VERSION ""

NS_ :

BS_:

BU_:

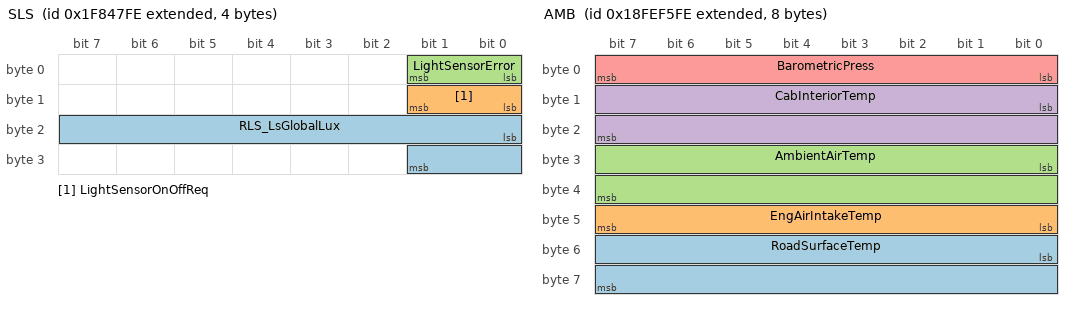
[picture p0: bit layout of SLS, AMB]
BO_ 2180532222 SLS: 4 Vector__XXX
 SG_ RLS_LsGlobalLux : 16|10@1+ (25,0) [0|25000] "" Vector__XXX
 SG_ LightSensorOnOffReq : 8|2@1+ (1,0) [0|0] "" Vector__XXX
 SG_ LightSensorError : 0|2@1+ (1,0) [0|3] "" Vector__XXX

BO_ 2566845950 AMB: 8 Vector__XXX
 SG_ RoadSurfaceTemp : 48|16@1+ (0.03125,-273) [-273|1734.96875] "C" Vector__XXX
 SG_ EngAirIntakeTemp : 40|8@1+ (1,-40) [-40|210] "C" Vector__XXX
 SG_ AmbientAirTemp : 24|16@1+ (0.03125,-273) [-273|1734.96875] "C" Vector__XXX
 SG_ CabInteriorTemp : 8|16@1+ (0.03125,-273) [-273|1734.96875] "C" Vector__XXX
 SG_ BarometricPress : 0|8@1+ (0.5,0) [0|125] "kPa" Vector__XXX

BO_ 2583065598 CENTLOCKOUT: 2 Vector__XXX
 SG_ CentralLockFailState : 8|4@1+ (1,0) [0|15] "-" Vector__XXX
 SG_ CentralLockCommand : 0|5@1+ (1,0) [0|31] "-" Vector__XXX

BO_ 2515942654 ClimateTempData: 3 Vector__XXX
 SG_ CabinTempSensorFault : 16|1@1+ (1,0) [0|1] "" Vector__XXX
 SG_ ActualCabinTemperature : 0|16@1+ (0.03125,-273) [-273|1774.96875] "degC" Vector__XXX

BO_ 2180392702 RSDS: 1 Vector__XXX
 SG_ RollerShutterFaults : 3|3@1+ (1,0) [0|7] "" Vector__XXX
 SG_ RollerShutterStatus : 0|3@1+ (1,0) [0|7] "" Vector__XXX

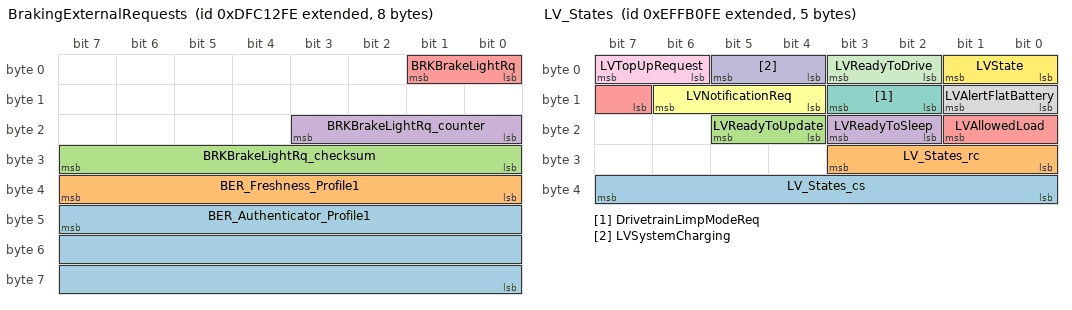
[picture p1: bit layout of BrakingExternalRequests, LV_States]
BO_ 2382107390 BrakingExternalRequests: 8 Vector__XXX
 SG_ BER_Authenticator_Profile1 : 47|24@0+ (1,0) [0|16777215] "" Vector__XXX
 SG_ BER_Freshness_Profile1 : 39|8@0+ (1,0) [0|255] "" Vector__XXX
 SG_ BRKBrakeLightRq_checksum : 24|8@1+ (1,0) [0|255] "" Vector__XXX
 SG_ BRKBrakeLightRq_counter : 16|4@1+ (1,0) [0|15] "" Vector__XXX
 SG_ BRKBrakeLightRq : 0|2@1+ (1,0) [0|3] "" Vector__XXX

BO_ 2399121662 LV_States: 5 Vector__XXX
 SG_ LV_States_cs : 32|8@1+ (1,0) [0|255] "" Vector__XXX
 SG_ LV_States_rc : 24|4@1+ (1,0) [0|15] "" Vector__XXX
 SG_ LVReadyToUpdate : 20|2@1+ (1,0) [0|3] "" Vector__XXX
 SG_ LVReadyToSleep : 18|2@1+ (1,0) [0|3] "" Vector__XXX
 SG_ LVAllowedLoad : 15|3@1+ (1,0) [0|7] "" Vector__XXX
 SG_ LVNotificationReq : 12|3@1+ (1,0) [0|7] "" Vector__XXX
 SG_ DrivetrainLimpModeReq : 10|2@1+ (1,0) [0|3] "" Vector__XXX
 SG_ LVAlertFlatBattery : 8|2@1+ (1,0) [0|3] "" Vector__XXX
 SG_ LVTopUpRequest : 6|2@1+ (1,0) [0|3] "" Vector__XXX
 SG_ LVSystemCharging : 4|2@1+ (1,0) [0|3] "" Vector__XXX
 SG_ LVReadyToDrive : 2|2@1+ (1,0) [0|3] "" Vector__XXX
 SG_ LVState : 0|2@1+ (1,0) [0|3] "" Vector__XXX

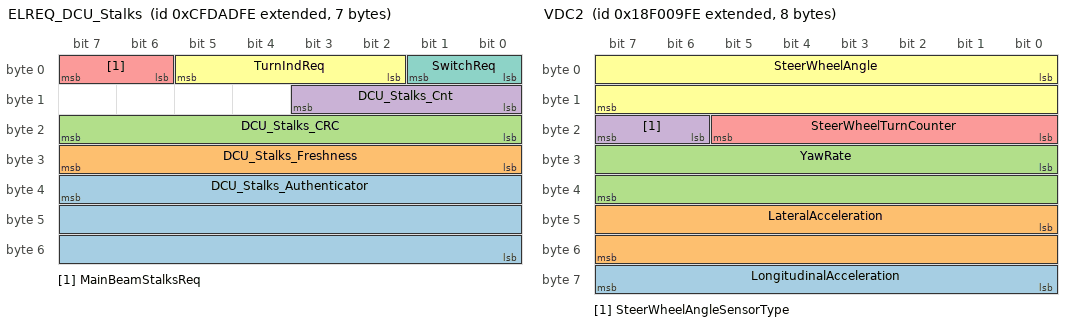
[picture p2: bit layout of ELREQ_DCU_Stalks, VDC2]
BO_ 2365435390 ELREQ_DCU_Stalks: 7 Vector__XXX
 SG_ DCU_Stalks_Authenticator : 39|24@0+ (1,0) [0|16777215] "" Vector__XXX
 SG_ DCU_Stalks_Freshness : 31|8@0+ (1,0) [0|255] "" Vector__XXX
 SG_ DCU_Stalks_CRC : 16|8@1+ (1,0) [0|0] "" Vector__XXX
 SG_ DCU_Stalks_Cnt : 8|4@1+ (1,0) [0|0] "" Vector__XXX
 SG_ MainBeamStalksReq : 6|2@1+ (1,0) [0|3] "" Vector__XXX
 SG_ TurnIndReq : 2|4@1+ (1,0) [0|3] "" Vector__XXX
 SG_ SwitchReq : 0|2@1+ (1,0) [0|3] "" Vector__XXX

BO_ 2365473278 LCMD: 8 Vector__XXX
 SG_ ImplementRearWorkLightCmd : 62|2@1+ (1,0) [0|3] "" Vector__XXX
 SG_ ImplLeftFacingWorkLightCmd : 60|2@1+ (1,0) [0|3] "" Vector__XXX
 SG_ ImplRightFwdWorkLightCmd : 58|2@1+ (1,0) [0|3] "" Vector__XXX
 SG_ LightingDataRqCmd : 56|2@1+ (1,0) [0|3] "" Vector__XXX
 SG_ ImplLeftForwardWorkLightCmd : 54|2@1+ (1,0) [0|3] "" Vector__XXX
 SG_ ImplRightFacingWorkLightCmd : 52|2@1+ (1,0) [0|3] "" Vector__XXX
 SG_ ImplOEMOption1LightCmd : 50|2@1+ (1,0) [0|3] "" Vector__XXX
 SG_ ImplOEMOption2LightCmd : 48|2@1+ (1,0) [0|3] "" Vector__XXX
 SG_ TrctrFrntHghMdWkLightsCmd : 46|2@1+ (1,0) [0|3] "" Vector__XXX
 SG_ TrctrFrntLowMdWkLightsCmd : 44|2@1+ (1,0) [0|3] "" Vector__XXX
 SG_ TrctrSdeHighMdWkLightsCmd : 42|2@1+ (1,0) [0|3] "" Vector__XXX
 SG_ TrctrSideLowMdWkLightsCmd : 40|2@1+ (1,0) [0|3] "" Vector__XXX
 SG_ TrctrRarHighMdWkLightsCmd : 38|2@1+ (1,0) [0|3] "" Vector__XXX
 SG_ TrctrRearLowMdWkLightsCmd : 36|2@1+ (1,0) [0|3] "" Vector__XXX
 SG_ TrctrUndrsdeMdWkLightsCmd : 34|2@1+ (1,0) [0|3] "" Vector__XXX
 SG_ RearFogLightsCmd : 32|2@1+ (1,0) [0|3] "" Vector__XXX
 SG_ TractorMarkerLightCmd : 30|2@1+ (1,0) [0|3] "" Vector__XXX
 SG_ ImplementMarkerLightCmd : 28|2@1+ (1,0) [0|3] "" Vector__XXX
 SG_ TractorClearanceLightCmd : 26|2@1+ (1,0) [0|3] "" Vector__XXX
 SG_ ImplementClearanceLightCmd : 24|2@1+ (1,0) [0|3] "" Vector__XXX
 SG_ LeftStopLightCmd : 22|2@1+ (1,0) [0|3] "" Vector__XXX
 SG_ RightStopLightCmd : 20|2@1+ (1,0) [0|3] "" Vector__XXX
 SG_ CenterStopLightCmd : 18|2@1+ (1,0) [0|3] "" Vector__XXX
 SG_ BackUpLightAndAlarmHornCmd : 16|2@1+ (1,0) [0|3] "" Vector__XXX
 SG_ LeftTurnSignalLightsCmd : 14|2@1+ (1,0) [0|3] "" Vector__XXX
 SG_ RightTurnSignalLightsCmd : 12|2@1+ (1,0) [0|3] "" Vector__XXX
 SG_ RotatingBeaconLightCmd : 10|2@1+ (1,0) [0|3] "" Vector__XXX
 SG_ TractorFrontFogLightsCmd : 8|2@1+ (1,0) [0|3] "" Vector__XXX
 SG_ HighBeamHeadLightCmd : 6|2@1+ (1,0) [0|3] "" Vector__XXX
 SG_ LowBeamHeadLightCmd : 4|2@1+ (1,0) [0|3] "" Vector__XXX
 SG_ AltBeamHeadLightCmd : 2|2@1+ (1,0) [0|3] "" Vector__XXX
 SG_ RunningLightCmd : 0|2@1+ (1,0) [0|3] "" Vector__XXX

BO_ 2566799614 LD: 8 Vector__XXX
 SG_ ImplementRearWorkLight : 62|2@1+ (1,0) [0|3] "" Vector__XXX
 SG_ ImplLeftFacingWorkLight : 60|2@1+ (1,0) [0|3] "" Vector__XXX
 SG_ ImplRightForwardWorkLight : 58|2@1+ (1,0) [0|3] "" Vector__XXX
 SG_ ImplLeftForwardWorkLight : 54|2@1+ (1,0) [0|3] "" Vector__XXX
 SG_ ImplRightFacingWorkLight : 52|2@1+ (1,0) [0|3] "" Vector__XXX
 SG_ ImplementOEMOption1Light : 50|2@1+ (1,0) [0|3] "" Vector__XXX
 SG_ ImplementOEMOption2Light : 48|2@1+ (1,0) [0|3] "" Vector__XXX
 SG_ TrctorFrontHighMdWkLights : 46|2@1+ (1,0) [0|3] "" Vector__XXX
 SG_ TractorFrontLowMdWkLights : 44|2@1+ (1,0) [0|3] "" Vector__XXX
 SG_ TractorSideHighMdWkLights : 42|2@1+ (1,0) [0|3] "" Vector__XXX
 SG_ TractorSideLowMdWkLights : 40|2@1+ (1,0) [0|3] "" Vector__XXX
 SG_ TractorRearHighMdWkLights : 38|2@1+ (1,0) [0|3] "" Vector__XXX
 SG_ TractorRearLowMdWkLights : 36|2@1+ (1,0) [0|3] "" Vector__XXX
 SG_ TrctorUndersideMdWkLights : 34|2@1+ (1,0) [0|3] "" Vector__XXX
 SG_ RearFogLights : 32|2@1+ (1,0) [0|3] "" Vector__XXX
 SG_ TractorMarkerLight : 30|2@1+ (1,0) [0|3] "" Vector__XXX
 SG_ ImplementMarkerLight : 28|2@1+ (1,0) [0|3] "" Vector__XXX
 SG_ TractorClearanceLight : 26|2@1+ (1,0) [0|3] "" Vector__XXX
 SG_ ImplementClearanceLight : 24|2@1+ (1,0) [0|3] "" Vector__XXX
 SG_ LeftStopLight : 22|2@1+ (1,0) [0|3] "" Vector__XXX
 SG_ RightStopLight : 20|2@1+ (1,0) [0|3] "" Vector__XXX
 SG_ CenterStopLight : 18|2@1+ (1,0) [0|3] "" Vector__XXX
 SG_ BackUpLightAndAlarmHorn : 16|2@1+ (1,0) [0|3] "" Vector__XXX
 SG_ LeftTurnSignalLights : 14|2@1+ (1,0) [0|3] "" Vector__XXX
 SG_ RightTurnSignalLights : 12|2@1+ (1,0) [0|3] "" Vector__XXX
 SG_ RotatingBeaconLight : 10|2@1+ (1,0) [0|3] "" Vector__XXX
 SG_ TractorFrontFogLights : 8|2@1+ (1,0) [0|3] "" Vector__XXX
 SG_ HighBeamHeadLight : 6|2@1+ (1,0) [0|3] "" Vector__XXX
 SG_ LowBeamHeadLight : 4|2@1+ (1,0) [0|3] "" Vector__XXX
 SG_ AltBeamHeadLight : 2|2@1+ (1,0) [0|3] "" Vector__XXX
 SG_ RunningLight : 0|2@1+ (1,0) [0|3] "" Vector__XXX

BO_ 2565868030 VDC2: 8 Vector__XXX
 SG_ LongitudinalAcceleration : 56|8@1+ (0.1,-12.5) [-12.5|12.5] "m/s" Vector__XXX
 SG_ LateralAcceleration : 40|16@1+ (0.00048828125,-15.687) [-15.687|15.687] "m/s" Vector__XXX
 SG_ YawRate : 24|16@1+ (0.0001220703125,-3.92) [-3.92|3.92] "rad/s" Vector__XXX
 SG_ SteerWheelAngleSensorType : 22|2@1+ (1,0) [0|3] "" Vector__XXX
 SG_ SteerWheelTurnCounter : 16|6@1+ (1,-32) [-10|10] "turns" Vector__XXX
 SG_ SteerWheelAngle : 0|16@1+ (0.0009765625,-31.374) [-31.374|31.374] "rad" Vector__XXX

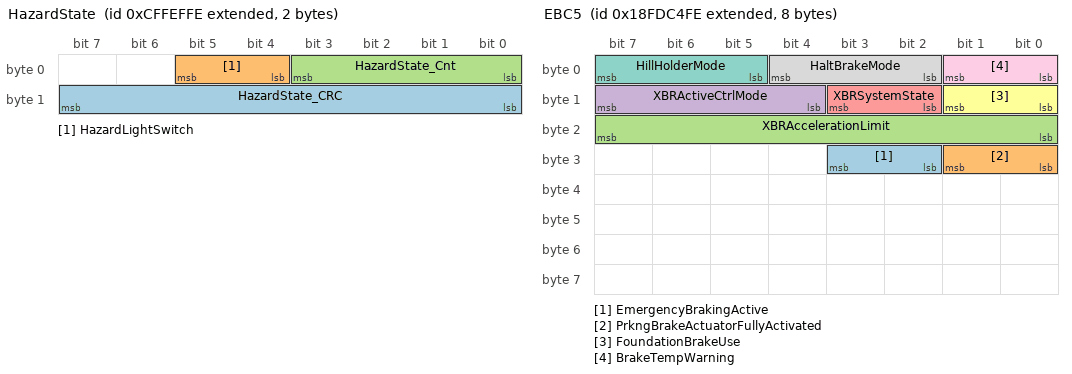
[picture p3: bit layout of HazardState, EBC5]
BO_ 2365583358 HazardState: 2 Vector__XXX
 SG_ HazardState_CRC : 8|8@1+ (1,0) [0|0] "" Vector__XXX
 SG_ HazardLightSwitch : 4|2@1+ (1,0) [0|3] "" Vector__XXX
 SG_ HazardState_Cnt : 0|4@1+ (1,0) [0|0] "" Vector__XXX

BO_ 2566767870 EBC5: 8 Vector__XXX
 SG_ EmergencyBrakingActive : 26|2@1+ (1,0) [0|3] "" Vector__XXX
 SG_ PrkngBrakeActuatorFullyActivated : 24|2@1+ (1,0) [0|3] "" Vector__XXX
 SG_ XBRAccelerationLimit : 16|8@1+ (0.1,-12.5) [-10|10] "m/s" Vector__XXX
 SG_ XBRActiveCtrlMode : 12|4@1+ (1,0) [0|15] "" Vector__XXX
 SG_ XBRSystemState : 10|2@1+ (1,0) [0|3] "" Vector__XXX
 SG_ FoundationBrakeUse : 8|2@1+ (1,0) [0|3] "" Vector__XXX
 SG_ HillHolderMode : 5|3@1+ (1,0) [0|7] "" Vector__XXX
 SG_ HaltBrakeMode : 2|3@1+ (1,0) [0|7] "" Vector__XXX
 SG_ BrakeTempWarning : 0|2@1+ (1,0) [0|3] "" Vector__XXX

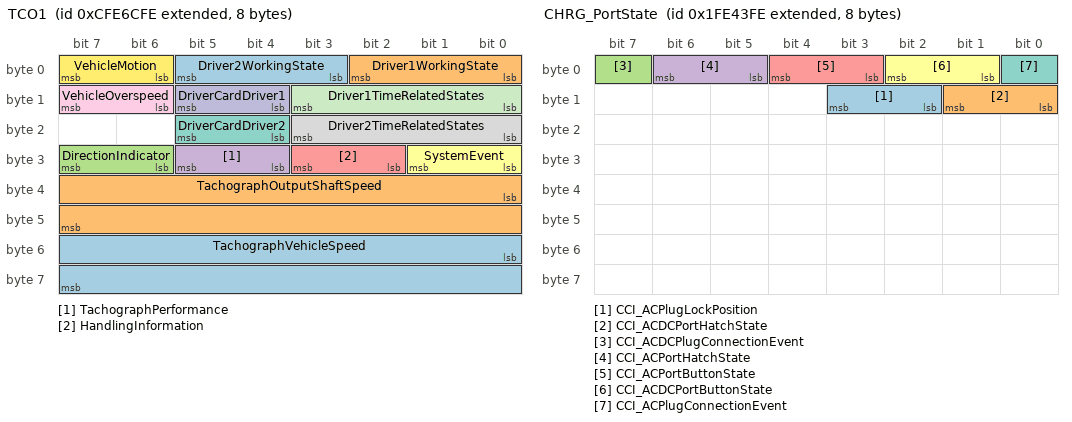
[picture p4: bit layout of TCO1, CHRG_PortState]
BO_ 2365484286 TCO1: 8 Vector__XXX
 SG_ TachographVehicleSpeed : 48|16@1+ (0.00390625,0) [0|250.996] "km/h" Vector__XXX
 SG_ TachographOutputShaftSpeed : 32|16@1+ (0.125,0) [0|8031.875] "rpm" Vector__XXX
 SG_ DirectionIndicator : 30|2@1+ (1,0) [0|3] "" Vector__XXX
 SG_ TachographPerformance : 28|2@1+ (1,0) [0|3] "" Vector__XXX
 SG_ HandlingInformation : 26|2@1+ (1,0) [0|3] "" Vector__XXX
 SG_ SystemEvent : 24|2@1+ (1,0) [0|3] "" Vector__XXX
 SG_ DriverCardDriver2 : 20|2@1+ (1,0) [0|3] "" Vector__XXX
 SG_ Driver2TimeRelatedStates : 16|4@1+ (1,0) [0|15] "" Vector__XXX
 SG_ VehicleOverspeed : 14|2@1+ (1,0) [0|3] "" Vector__XXX
 SG_ DriverCardDriver1 : 12|2@1+ (1,0) [0|3] "" Vector__XXX
 SG_ Driver1TimeRelatedStates : 8|4@1+ (1,0) [0|15] "" Vector__XXX
 SG_ VehicleMotion : 6|2@1+ (1,0) [0|3] "" Vector__XXX
 SG_ Driver2WorkingState : 3|3@1+ (1,0) [0|7] "" Vector__XXX
 SG_ Driver1WorkingState : 0|3@1+ (1,0) [0|7] "" Vector__XXX

BO_ 2180924414 CHRG_PortState: 8 Vector__XXX
 SG_ CCI_ACPlugLockPosition : 10|2@1+ (1,0) [0|3] "" Vector__XXX
 SG_ CCI_ACDCPortHatchState : 8|2@1+ (1,0) [0|3] "" Vector__XXX
 SG_ CCI_ACDCPlugConnectionEvent : 7|1@1+ (1,0) [0|1] "" Vector__XXX
 SG_ CCI_ACPortHatchState : 5|2@1+ (1,0) [0|3] "" Vector__XXX
 SG_ CCI_ACPortButtonState : 3|2@1+ (1,0) [0|3] "" Vector__XXX
 SG_ CCI_ACDCPortButtonState : 1|2@1+ (1,0) [0|3] "" Vector__XXX
 SG_ CCI_ACPlugConnectionEvent : 0|1@1+ (1,0) [0|1] "" Vector__XXX

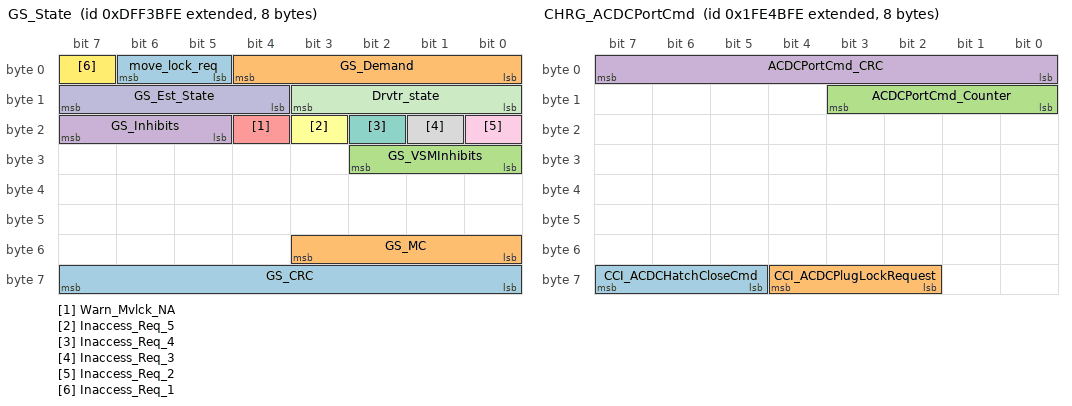
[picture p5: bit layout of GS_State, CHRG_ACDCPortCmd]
BO_ 2382314494 GS_State: 8 Vector__XXX
 SG_ GS_CRC : 56|8@1+ (1,0) [0|255] "" Vector__XXX
 SG_ GS_MC : 48|4@1+ (1,0) [0|15] "" Vector__XXX
 SG_ GS_VSMInhibits : 24|3@1+ (1,0) [0|7] "" Vector__XXX
 SG_ GS_Inhibits : 21|3@1+ (1,0) [0|7] "" Vector__XXX
 SG_ Warn_Mvlck_NA : 20|1@1+ (1,0) [0|1] "" Vector__XXX
 SG_ Inaccess_Req_5 : 19|1@1+ (1,0) [0|1] "" Vector__XXX
 SG_ Inaccess_Req_4 : 18|1@1+ (1,0) [0|1] "" Vector__XXX
 SG_ Inaccess_Req_3 : 17|1@1+ (1,0) [0|1] "" Vector__XXX
 SG_ Inaccess_Req_2 : 16|1@1+ (1,0) [0|1] "" Vector__XXX
 SG_ GS_Est_State : 12|4@1+ (1,0) [0|15] "" Vector__XXX
 SG_ Drvtr_state : 8|4@1+ (1,0) [0|15] "" Vector__XXX
 SG_ Inaccess_Req_1 : 7|1@1+ (1,0) [0|1] "" Vector__XXX
 SG_ move_lock_req : 5|2@1+ (1,0) [0|3] "" Vector__XXX
 SG_ GS_Demand : 0|5@1+ (1,0) [0|31] "" Vector__XXX

BO_ 2180926462 CHRG_ACDCPortCmd: 8 Vector__XXX
 SG_ CCI_ACDCHatchCloseCmd : 61|3@1+ (1,0) [0|7] "" Vector__XXX
 SG_ CCI_ACDCPlugLockRequest : 58|3@1+ (1,0) [0|7] "" Vector__XXX
 SG_ ACDCPortCmd_Counter : 8|4@1+ (1,0) [0|15] "" Vector__XXX
 SG_ ACDCPortCmd_CRC : 0|8@1+ (1,0) [0|255] "" Vector__XXX

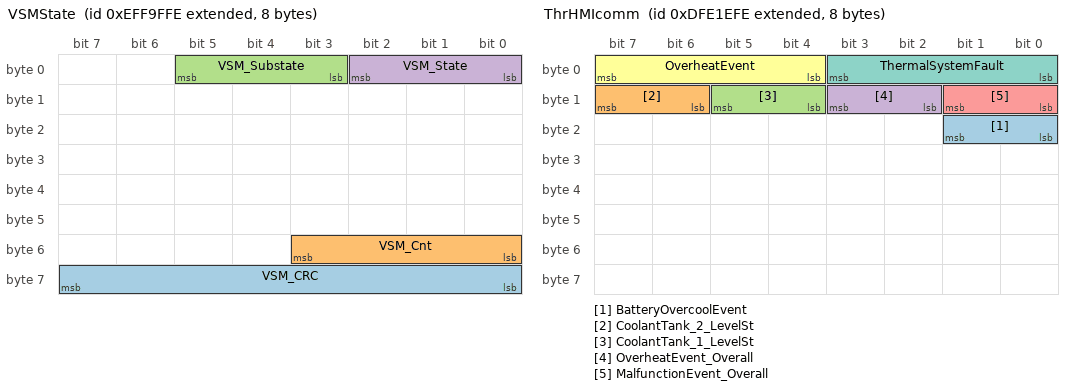
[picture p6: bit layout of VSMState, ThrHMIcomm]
BO_ 2399117310 VSMState: 8 Vector__XXX
 SG_ VSM_CRC : 56|8@1+ (1,0) [0|255] "" Vector__XXX
 SG_ VSM_Cnt : 48|4@1+ (1,0) [0|15] "" Vector__XXX
 SG_ VSM_Substate : 3|3@1+ (1,0) [0|7] "" Vector__XXX
 SG_ VSM_State : 0|3@1+ (1,0) [0|7] "" Vector__XXX

BO_ 2566883070 DoorLockNotify: 1 Vector__XXX
 SG_ RollerShutterLatchNotify : 3|3@1+ (1,0) [0|3] "-" Vector__XXX
 SG_ DoorLatchNotify : 0|3@1+ (1,0) [0|3] "-" Vector__XXX

BO_ 2382241534 ThrHMIcomm: 8 Vector__XXX
 SG_ BatteryOvercoolEvent : 16|2@1+ (1,0) [0|3] "" Vector__XXX
 SG_ CoolantTank_2_LevelSt : 14|2@1+ (1,0) [0|0] "" Vector__XXX
 SG_ CoolantTank_1_LevelSt : 12|2@1+ (1,0) [0|0] "" Vector__XXX
 SG_ OverheatEvent_Overall : 10|2@1+ (1,0) [0|0] "" Vector__XXX
 SG_ MalfunctionEvent_Overall : 8|2@1+ (1,0) [0|0] "" Vector__XXX
 SG_ OverheatEvent : 4|4@1+ (1,0) [0|0] "" Vector__XXX
 SG_ ThermalSystemFault : 0|4@1+ (1,0) [0|0] "" Vector__XXX

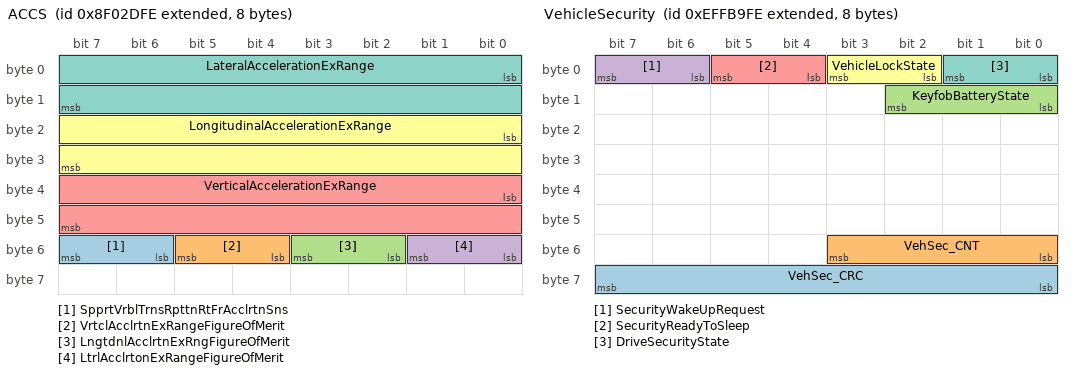
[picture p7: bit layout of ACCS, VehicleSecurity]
BO_ 2297441790 ACCS: 8 Vector__XXX
 SG_ SpprtVrblTrnsRpttnRtFrAcclrtnSns : 54|2@1+ (1,0) [0|3] "" Vector__XXX
 SG_ VrtclAcclrtnExRangeFigureOfMerit : 52|2@1+ (1,0) [0|3] "" Vector__XXX
 SG_ LngtdnlAcclrtnExRngFigureOfMerit : 50|2@1+ (1,0) [0|3] "" Vector__XXX
 SG_ LtrlAcclrtonExRangeFigureOfMerit : 48|2@1+ (1,0) [0|3] "" Vector__XXX
 SG_ VerticalAccelerationExRange : 32|16@1+ (0.01,-320) [-320|322.55] "m/s" Vector__XXX
 SG_ LongitudinalAccelerationExRange : 16|16@1+ (0.01,-320) [-320|322.55] "m/s" Vector__XXX
 SG_ LateralAccelerationExRange : 0|16@1+ (0.01,-320) [-320|322.55] "m/s" Vector__XXX

BO_ 2583173886 WPRWSH_UserRequest: 1 Vector__XXX
 SG_ WipeRequest : 2|3@1+ (1,0) [0|7] "" Vector__XXX
 SG_ WashRequest : 0|2@1+ (1,0) [0|3] "" Vector__XXX

BO_ 2516075518 RideHeight_Info: 8 Vector__XXX
 SG_ RideHeight_Value : 0|3@1+ (1,0) [0|0] "" Vector__XXX

BO_ 2566882814 VehicleKeyState: 8 Vector__XXX
 SG_ KeyRange : 3|3@1+ (1,0) [0|7] "-" Vector__XXX
 SG_ KeyCommand : 0|3@1+ (1,0) [0|7] "-" Vector__XXX

BO_ 2583062526 CENTLOCKIN_HMI: 8 Vector__XXX
 SG_ CentralLockRequest : 0|3@1+ (1,0) [0|7] "-" Vector__XXX

BO_ 2399123966 VehicleSecurity: 8 Vector__XXX
 SG_ VehSec_CRC : 56|8@1+ (1,0) [0|255] "" Vector__XXX
 SG_ VehSec_CNT : 48|4@1+ (1,0) [0|15] "" Vector__XXX
 SG_ KeyfobBatteryState : 8|3@1+ (1,0) [0|7] "" Vector__XXX
 SG_ SecurityWakeUpRequest : 6|2@1+ (1,0) [0|3] "" Vector__XXX
 SG_ SecurityReadyToSleep : 4|2@1+ (1,0) [0|3] "" Vector__XXX
 SG_ VehicleLockState : 2|2@1+ (1,0) [0|3] "" Vector__XXX
 SG_ DriveSecurityState : 0|2@1+ (1,0) [0|3] "" Vector__XXX

BO_ 2583065854 CENTLOCKIN_KeyFob: 8 Vector__XXX
 SG_ CentralLockRequest : 0|3@1+ (1,0) [0|7] "-" Vector__XXX

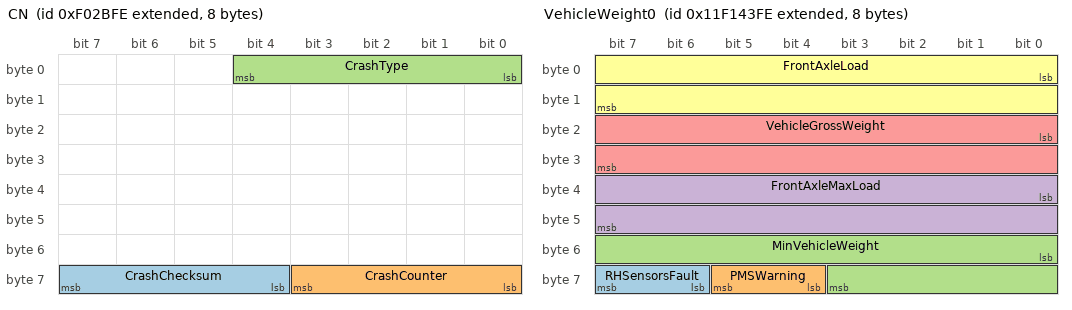
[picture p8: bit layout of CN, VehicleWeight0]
BO_ 2163223550 CN: 8 Vector__XXX
 SG_ CrashChecksum : 60|4@1+ (1,0) [0|15] "" Vector__XXX
 SG_ CrashCounter : 56|4@1+ (1,0) [0|15] "" Vector__XXX
 SG_ CrashType : 0|5@1+ (1,0) [0|31] "" Vector__XXX

BO_ 2448507902 VehicleWeight0: 8 Vector__XXX
 SG_ RHSensorsFault : 62|2@1+ (1,0) [0|3] "" Vector__XXX
 SG_ PMSWarning : 60|2@1+ (1,0) [0|3] "" Vector__XXX
 SG_ MinVehicleWeight : 48|12@1+ (10,0) [0|40000] "kg" Vector__XXX
 SG_ FrontAxleMaxLoad : 32|16@1+ (1,0) [0|65535] "kg" Vector__XXX
 SG_ VehicleGrossWeight : 16|16@1+ (1,0) [0|65535] "kg" Vector__XXX
 SG_ FrontAxleLoad : 0|16@1+ (1,0) [0|65535] "kg" Vector__XXX

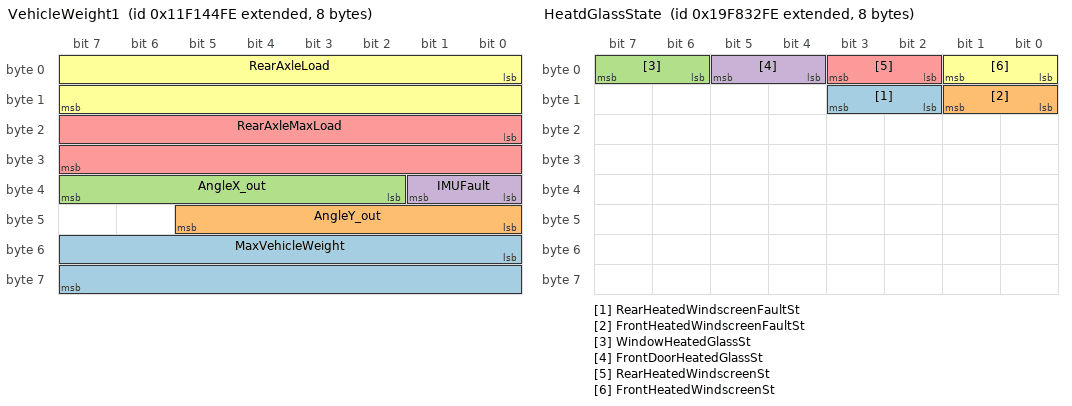
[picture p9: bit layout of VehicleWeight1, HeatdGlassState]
BO_ 2448508158 VehicleWeight1: 8 Vector__XXX
 SG_ MaxVehicleWeight : 48|16@1+ (1,0) [0|65535] "kg" Vector__XXX
 SG_ AngleY_out : 40|6@1+ (1.5,-45) [-45|45] "deg" Vector__XXX
 SG_ AngleX_out : 34|6@1+ (1.5,-45) [-45|45] "deg" Vector__XXX
 SG_ IMUFault : 32|2@1+ (1,0) [0|3] "" Vector__XXX
 SG_ RearAxleMaxLoad : 16|16@1+ (1,0) [0|65535] "kg" Vector__XXX
 SG_ RearAxleLoad : 0|16@1+ (1,0) [0|65535] "kg" Vector__XXX

BO_ 2583180030 HeatdGlassState: 8 Vector__XXX
 SG_ RearHeatedWindscreenFaultSt : 10|2@1+ (1,0) [0|3] "" Vector__XXX
 SG_ FrontHeatedWindscreenFaultSt : 8|2@1+ (1,0) [0|3] "" Vector__XXX
 SG_ WindowHeatedGlassSt : 6|2@1+ (1,0) [0|3] "" Vector__XXX
 SG_ FrontDoorHeatedGlassSt : 4|2@1+ (1,0) [0|3] "" Vector__XXX
 SG_ RearHeatedWindscreenSt : 2|2@1+ (1,0) [0|3] "" Vector__XXX
 SG_ FrontHeatedWindscreenSt : 0|2@1+ (1,0) [0|3] "" Vector__XXX

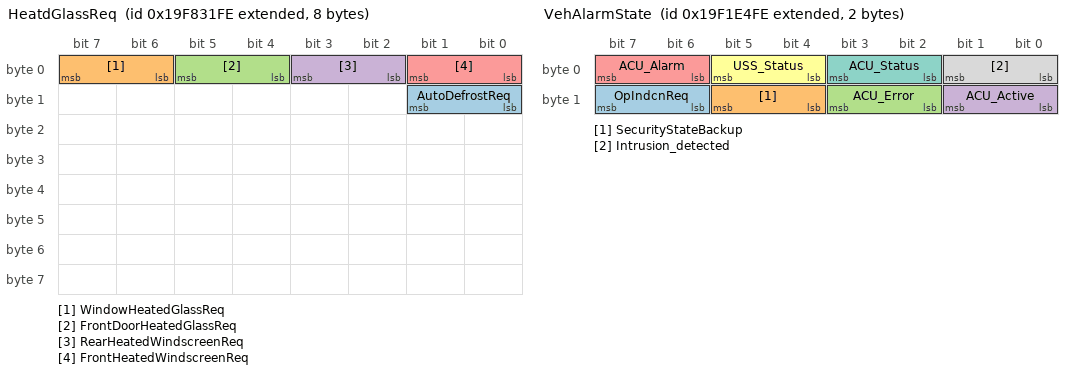
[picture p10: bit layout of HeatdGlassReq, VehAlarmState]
BO_ 2583179774 HeatdGlassReq: 8 Vector__XXX
 SG_ AutoDefrostReq : 8|2@1+ (1,0) [0|3] "" Vector__XXX
 SG_ WindowHeatedGlassReq : 6|2@1+ (1,0) [0|3] "" Vector__XXX
 SG_ FrontDoorHeatedGlassReq : 4|2@1+ (1,0) [0|3] "" Vector__XXX
 SG_ RearHeatedWindscreenReq : 2|2@1+ (1,0) [0|3] "" Vector__XXX
 SG_ FrontHeatedWindscreenReq : 0|2@1+ (1,0) [0|3] "" Vector__XXX

BO_ 2499547902 CDC: 8 Vector__XXX
 SG_ MirrorRight2HeatCmd : 54|2@1+ (1,0) [0|3] "" Vector__XXX
 SG_ MirrorLeft2HeatCmd : 52|2@1+ (1,0) [0|3] "" Vector__XXX
 SG_ MirrorRight1HeatCmd : 50|2@1+ (1,0) [0|3] "" Vector__XXX
 SG_ MirrorLeft1HeatCmd : 48|2@1+ (1,0) [0|3] "" Vector__XXX
 SG_ MirrorRight2VerticalCmd : 46|2@1+ (1,0) [0|3] "" Vector__XXX
 SG_ MirrorRight2HorizontalCmd : 44|2@1+ (1,0) [0|3] "" Vector__XXX
 SG_ MirrorLeft2VerticalCmd : 42|2@1+ (1,0) [0|3] "" Vector__XXX
 SG_ MirrorLeft2HorizontalCmd : 40|2@1+ (1,0) [0|3] "" Vector__XXX
 SG_ MirrorRight1VerticalCmd : 38|2@1+ (1,0) [0|3] "" Vector__XXX
 SG_ MirrorRight1HorizontalCmd : 36|2@1+ (1,0) [0|3] "" Vector__XXX
 SG_ MirrorLeft1VerticalCmd : 34|2@1+ (1,0) [0|3] "" Vector__XXX
 SG_ MirrorLeft1HorizontalCmd : 32|2@1+ (1,0) [0|3] "" Vector__XXX
 SG_ RightRearWindowPosCmd : 27|3@1+ (1,0) [0|7] "" Vector__XXX
 SG_ LeftRearWindowPosCmd : 24|3@1+ (1,0) [0|7] "" Vector__XXX
 SG_ RightFrontWindowPosCmd : 19|3@1+ (1,0) [0|7] "" Vector__XXX
 SG_ LeftFrontWindowPosCmd : 16|3@1+ (1,0) [0|7] "" Vector__XXX
 SG_ RemoteCabDoorLockReq : 8|3@1+ (1,0) [0|7] "" Vector__XXX
 SG_ DoorsLockActCmd : 0|3@1+ (1,0) [0|7] "" Vector__XXX

BO_ 2583177470 WPRWSH_RainData: 1 Vector__XXX
 SG_ RainIntensity : 0|3@1+ (1,0) [0|7] "" Vector__XXX

BO_ 2364552702 ImmoState: 1 Vector__XXX
 SG_ ImmoState : 0|2@1+ (1,0) [0|3] "" Vector__XXX

BO_ 2582766846 VehAlarmState: 2 Vector__XXX
 SG_ OpIndcnReq : 14|2@1+ (1,0) [0|3] "" Vector__XXX
 SG_ SecurityStateBackup : 12|2@1+ (1,0) [0|0] "" Vector__XXX
 SG_ ACU_Error : 10|2@1+ (1,0) [0|0] "" Vector__XXX
 SG_ ACU_Active : 8|2@1+ (1,0) [0|3] "" Vector__XXX
 SG_ ACU_Alarm : 6|2@1+ (1,0) [0|3] "" Vector__XXX
 SG_ USS_Status : 4|2@1+ (1,0) [0|3] "" Vector__XXX
 SG_ ACU_Status : 2|2@1+ (1,0) [0|3] "" Vector__XXX
 SG_ Intrusion_detected : 0|2@1+ (1,0) [0|3] "-" Vector__XXX

BO_ 2565865982 EBC1: 8 Vector__XXX
 SG_ TrctrMntdTrailerABSWarningSignal : 62|2@1+ (1,0) [0|3] "" Vector__XXX
 SG_ TrailerABSStatus : 60|2@1+ (1,0) [0|3] "" Vector__XXX
 SG_ HaltBrakeSwitch : 58|2@1+ (1,0) [0|3] "" Vector__XXX
 SG_ SrcAddrssOfCntrllngDvcFrBrkeCtrl : 48|8@1+ (1,0) [0|253] "" Vector__XXX
 SG_ ATC_ASRInformationSignal : 46|2@1+ (1,0) [0|3] "" Vector__XXX
 SG_ ABS_EBSAmberWarningSignal : 44|2@1+ (1,0) [0|3] "" Vector__XXX
 SG_ EBSRedWarningSignal : 42|2@1+ (1,0) [0|3] "" Vector__XXX
 SG_ ABSFullyOperational : 40|2@1+ (1,0) [0|3] "" Vector__XXX
 SG_ EngRetarderSelection : 32|8@1+ (0.4,0) [0|100] "%" Vector__XXX
 SG_ RemoteAccelEnableSwitch : 30|2@1+ (1,0) [0|3] "" Vector__XXX
 SG_ EngAuxShutdownSwitch : 28|2@1+ (1,0) [0|3] "" Vector__XXX
 SG_ EngDerateSwitch : 26|2@1+ (1,0) [0|3] "" Vector__XXX
 SG_ AccelInterlockSwitch : 24|2@1+ (1,0) [0|3] "" Vector__XXX
 SG_ TractionCtrlOverrideSwitch : 22|2@1+ (1,0) [0|3] "" Vector__XXX
 SG_ ASRHillHolderSwitch : 20|2@1+ (1,0) [0|3] "" Vector__XXX
 SG_ ASROffroadSwitch : 18|2@1+ (1,0) [0|3] "" Vector__XXX
 SG_ ABSOffroadSwitch : 16|2@1+ (1,0) [0|3] "" Vector__XXX
 SG_ BrakePedalPos : 8|8@1+ (0.4,0) [0|100] "%" Vector__XXX
 SG_ EBSBrakeSwitch : 6|2@1+ (1,0) [0|3] "" Vector__XXX
 SG_ AntiLockBrakingActive : 4|2@1+ (1,0) [0|3] "" Vector__XXX
 SG_ ASRBrakeCtrlActive : 2|2@1+ (1,0) [0|3] "" Vector__XXX
 SG_ ASREngCtrlActive : 0|2@1+ (1,0) [0|3] "" Vector__XXX

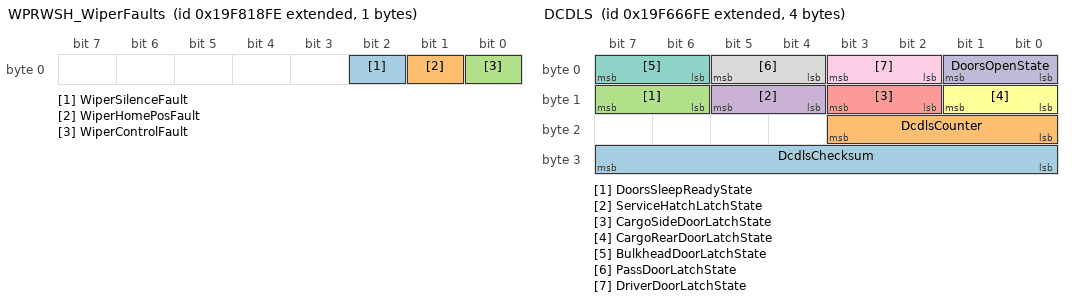
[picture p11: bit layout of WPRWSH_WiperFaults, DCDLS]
BO_ 2583173374 WPRWSH_WiperFaults: 1 Vector__XXX
 SG_ WiperSilenceFault : 2|1@1+ (1,0) [0|1] "" Vector__XXX
 SG_ WiperHomePosFault : 1|1@1+ (1,0) [0|1] "" Vector__XXX
 SG_ WiperControlFault : 0|1@1+ (1,0) [0|1] "" Vector__XXX

BO_ 2381731326 TP_TouchEvent: 8 Vector__XXX
 SG_ TouchFailState : 3|3@1+ (1,0) [0|7] "" Vector__XXX
 SG_ TouchEvent : 0|3@1+ (1,0) [0|7] "" Vector__XXX

BO_ 2583062270 DCDLS: 4 Vector__XXX
 SG_ DcdlsChecksum : 24|8@1+ (1,0) [0|255] "" Vector__XXX
 SG_ DcdlsCounter : 16|4@1+ (1,0) [0|15] "" Vector__XXX
 SG_ DoorsSleepReadyState : 14|2@1+ (1,0) [0|3] "-" Vector__XXX
 SG_ ServiceHatchLatchState : 12|2@1+ (1,0) [0|3] "" Vector__XXX
 SG_ CargoSideDoorLatchState : 10|2@1+ (1,0) [0|3] "-" Vector__XXX
 SG_ CargoRearDoorLatchState : 8|2@1+ (1,0) [0|3] "-" Vector__XXX
 SG_ BulkheadDoorLatchState : 6|2@1+ (1,0) [0|3] "-" Vector__XXX
 SG_ PassDoorLatchState : 4|2@1+ (1,0) [0|3] "-" Vector__XXX
 SG_ DriverDoorLatchState : 2|2@1+ (1,0) [0|3] "-" Vector__XXX
 SG_ DoorsOpenState : 0|2@1+ (1,0) [0|3] "-" Vector__XXX

BO_ 2516060670 ParkAssistRequest: 8 Vector__XXX
 SG_ paEnableReq : 2|2@1+ (1,0) [0|3] "" Vector__XXX
 SG_ paAutoReq : 0|2@1+ (1,0) [0|3] "" Vector__XXX

BO_ 2516060414 ParkAssistStatus: 8 Vector__XXX
 SG_ paStatus : 0|2@1+ (1,0) [0|3] "" Vector__XXX

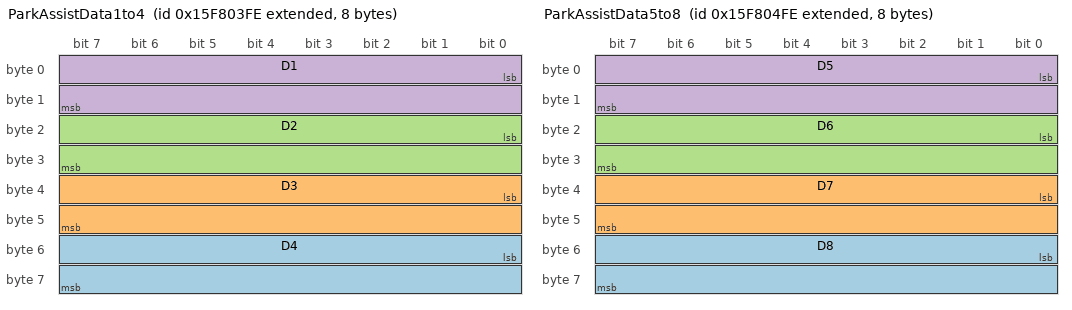
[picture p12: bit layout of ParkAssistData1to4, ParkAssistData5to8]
BO_ 2516059134 ParkAssistData1to4: 8 Vector__XXX
 SG_ D4 : 48|16@1+ (1,0) [0|65535] "mm" Vector__XXX
 SG_ D3 : 32|16@1+ (1,0) [0|65535] "mm" Vector__XXX
 SG_ D2 : 16|16@1+ (1,0) [0|65535] "mm" Vector__XXX
 SG_ D1 : 0|16@1+ (1,0) [0|65535] "mm" Vector__XXX

BO_ 2516059390 ParkAssistData5to8: 8 Vector__XXX
 SG_ D8 : 48|16@1+ (1,0) [0|65535] "mm" Vector__XXX
 SG_ D7 : 32|16@1+ (1,0) [0|65535] "mm" Vector__XXX
 SG_ D6 : 16|16@1+ (1,0) [0|65535] "mm" Vector__XXX
 SG_ D5 : 0|16@1+ (1,0) [0|65535] "mm" Vector__XXX

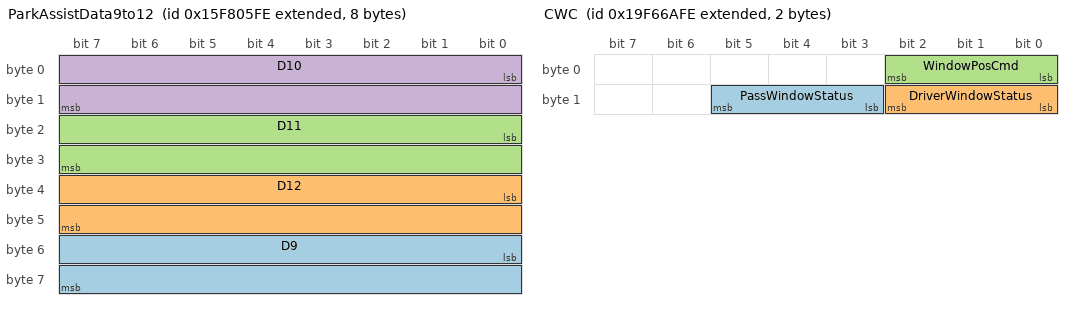
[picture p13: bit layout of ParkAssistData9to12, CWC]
BO_ 2516059646 ParkAssistData9to12: 8 Vector__XXX
 SG_ D9 : 48|16@1+ (1,0) [0|65535] "mm" Vector__XXX
 SG_ D12 : 32|16@1+ (1,0) [0|65535] "mm" Vector__XXX
 SG_ D11 : 16|16@1+ (1,0) [0|65535] "mm" Vector__XXX
 SG_ D10 : 0|16@1+ (1,0) [0|65535] "mm" Vector__XXX

BO_ 2381723902 HVAC_Feedback: 8 Vector__XXX
 SG_ HVACActualLVPower : 56|7@1+ (1,0) [0|127] "W" Vector__XXX
 SG_ RecircModeState : 52|3@1+ (1,0) [0|7] "" Vector__XXX
 SG_ OutletSelectionState : 48|4@1+ (1,0) [0|15] "" Vector__XXX
 SG_ BlowerSpeed : 40|7@1+ (1,0) [0|100] "%" Vector__XXX
 SG_ AirOutTemperature : 30|10@1+ (0.2,-50) [-50|154.6] "degC" Vector__XXX
 SG_ IsolationValveIntegrityFault : 29|1@1+ (1,0) [0|1] "" Vector__XXX
 SG_ WindscreenFlapIntegrityFault : 28|1@1+ (1,0) [0|1] "" Vector__XXX
 SG_ HVACFailure : 27|1@1+ (1,0) [0|1] "" Vector__XXX
 SG_ FrontFlapIntegrityFault : 26|1@1+ (1,0) [0|1] "" Vector__XXX
 SG_ AirInTemperature : 16|10@1+ (0.2,-50) [-50|154.6] "degC" Vector__XXX
 SG_ FloorFlapIntegrityFault : 15|1@1+ (1,0) [0|1] "" Vector__XXX
 SG_ RecircFlapIntegrityFault : 14|1@1+ (1,0) [0|1] "" Vector__XXX
 SG_ BlowerIntegrityFault : 13|1@1+ (1,0) [0|1] "" Vector__XXX
 SG_ TAirOutSensorIntegrityFault : 12|1@1+ (1,0) [0|1] "" Vector__XXX
 SG_ TAirInSensorIntegrityFault : 11|1@1+ (1,0) [0|1] "" Vector__XXX
 SG_ TChillerCoreSensorIntegrityFault : 10|1@1+ (1,0) [0|1] "" Vector__XXX
 SG_ ColdCoilTemperature : 0|10@1+ (0.2,-50) [-50|154.6] "degC" Vector__XXX

BO_ 2583063294 CWC: 2 Vector__XXX
 SG_ PassWindowStatus : 11|3@1+ (1,0) [0|3] "" Vector__XXX
 SG_ DriverWindowStatus : 8|3@1+ (1,0) [0|3] "" Vector__XXX
 SG_ WindowPosCmd : 0|3@1+ (1,0) [0|7] "" Vector__XXX

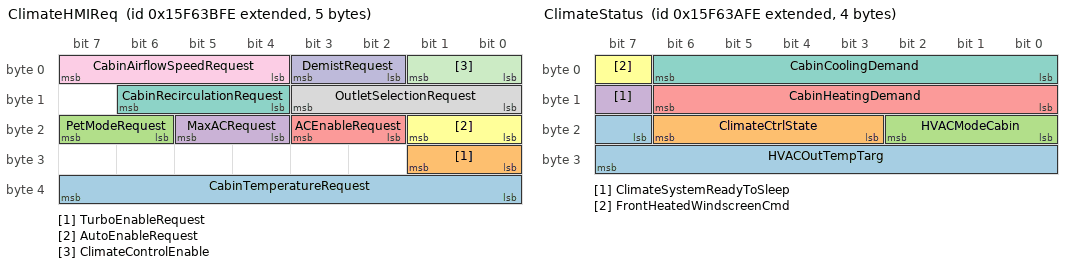
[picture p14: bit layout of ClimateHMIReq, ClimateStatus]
BO_ 2515942398 ClimateHMIReq: 5 Vector__XXX
 SG_ CabinTemperatureRequest : 32|8@1+ (0.25,0) [0|63.75] "degC" Vector__XXX
 SG_ TurboEnableRequest : 24|2@1+ (1,0) [0|3] "" Vector__XXX
 SG_ PetModeRequest : 22|2@1+ (1,0) [0|3] "" Vector__XXX
 SG_ MaxACRequest : 20|2@1+ (1,0) [0|3] "" Vector__XXX
 SG_ ACEnableRequest : 18|2@1+ (1,0) [0|3] "" Vector__XXX
 SG_ AutoEnableRequest : 16|2@1+ (1,0) [0|3] "" Vector__XXX
 SG_ CabinRecirculationRequest : 12|3@1+ (1,0) [0|7] "" Vector__XXX
 SG_ OutletSelectionRequest : 8|4@1+ (1,0) [0|15] "" Vector__XXX
 SG_ CabinAirflowSpeedRequest : 4|4@1+ (1,0) [0|15] "" Vector__XXX
 SG_ DemistRequest : 2|2@1+ (1,0) [0|3] "" Vector__XXX
 SG_ ClimateControlEnable : 0|2@1+ (1,0) [0|3] "" Vector__XXX

BO_ 2515949566 ClimateHMIState: 6 Vector__XXX
 SG_ ClimateSystemEffortDisp : 40|8@1+ (1,-100) [-100|100] "%" Vector__XXX
 SG_ IsolationValveIntegrityFault : 38|1@1+ (1,0) [0|1] "" Vector__XXX
 SG_ FloorFlapIntegrityFault : 37|1@1+ (1,0) [0|1] "" Vector__XXX
 SG_ FrontFlapIntegrityFault : 36|1@1+ (1,0) [0|1] "" Vector__XXX
 SG_ WindscreenFlapIntegrityFault : 35|1@1+ (1,0) [0|1] "" Vector__XXX
 SG_ RecircFlapIntegrityFault : 34|1@1+ (1,0) [0|1] "" Vector__XXX
 SG_ BlowerIntegrityFault : 33|1@1+ (1,0) [0|1] "" Vector__XXX
 SG_ RainLightSensorIntegrityFault : 32|1@1+ (1,0) [0|1] "" Vector__XXX
 SG_ AmbientTempSensorIntegrity : 31|1@1+ (1,0) [0|1] "" Vector__XXX
 SG_ CabinTempSensorIntegrityFault : 30|1@1+ (1,0) [0|1] "" Vector__XXX
 SG_ TAirOutSensorIntegrityFault : 29|1@1+ (1,0) [0|1] "" Vector__XXX
 SG_ TChillerCoreSensorIntegrityFault : 28|1@1+ (1,0) [0|1] "" Vector__XXX
 SG_ TAirInSensorIntegrityFault : 27|1@1+ (1,0) [0|1] "" Vector__XXX
 SG_ HVACFailure : 26|1@1+ (1,0) [0|1] "" Vector__XXX
 SG_ TurboEnableState : 24|2@1+ (1,0) [0|3] "" Vector__XXX
 SG_ PetModeState : 22|2@1+ (1,0) [0|3] "" Vector__XXX
 SG_ MaxACState : 20|2@1+ (1,0) [0|3] "" Vector__XXX
 SG_ ACEnableState : 18|2@1+ (1,0) [0|3] "" Vector__XXX
 SG_ AutoEnableState : 16|2@1+ (1,0) [0|3] "" Vector__XXX
 SG_ RecirculationRequestState : 12|3@1+ (1,0) [0|7] "" Vector__XXX
 SG_ OutletSelectionState : 8|4@1+ (1,0) [0|15] "" Vector__XXX
 SG_ BlowerSpeedRequestState : 4|4@1+ (1,0) [0|15] "" Vector__XXX
 SG_ DemistRequestState : 2|2@1+ (1,0) [0|3] "" Vector__XXX
 SG_ ClimateControlEnableState : 0|2@1+ (1,0) [0|3] "" Vector__XXX

BO_ 2515942142 ClimateStatus: 4 Vector__XXX
 SG_ HVACOutTempTarg : 23|9@1+ (0.2,-10) [-10|92.2] "degC" Vector__XXX
 SG_ ClimateCtrlState : 19|4@1+ (1,0) [0|0] "" Vector__XXX
 SG_ HVACModeCabin : 16|3@1+ (1,0) [0|0] "" Vector__XXX
 SG_ ClimateSystemReadyToSleep : 15|1@1+ (1,0) [0|1] "" Vector__XXX
 SG_ CabinHeatingDemand : 8|7@1+ (1,0) [0|100] "%" Vector__XXX
 SG_ FrontHeatedWindscreenCmd : 7|1@1+ (1,0) [0|1] "" Vector__XXX
 SG_ CabinCoolingDemand : 0|7@1+ (1,0) [0|100] "%" Vector__XXX

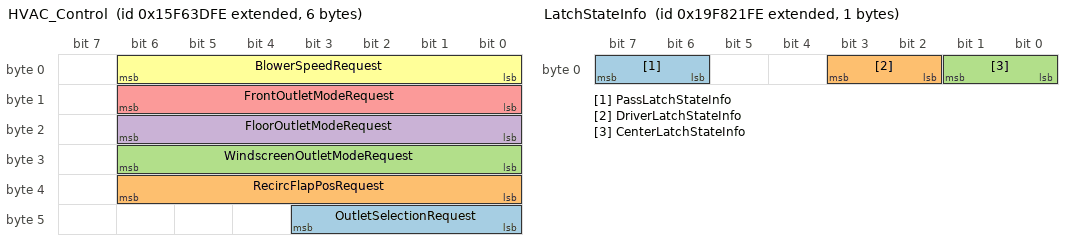
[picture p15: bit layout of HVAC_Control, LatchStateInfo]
BO_ 2515942910 HVAC_Control: 6 Vector__XXX
 SG_ OutletSelectionRequest : 40|4@1+ (1,0) [0|15] "" Vector__XXX
 SG_ RecircFlapPosRequest : 32|7@1+ (1,0) [0|100] "%" Vector__XXX
 SG_ WindscreenOutletModeRequest : 24|7@1+ (1,0) [0|100] "%" Vector__XXX
 SG_ FloorOutletModeRequest : 16|7@1+ (1,0) [0|100] "%" Vector__XXX
 SG_ FrontOutletModeRequest : 8|7@1+ (1,0) [0|100] "%" Vector__XXX
 SG_ BlowerSpeedRequest : 0|7@1+ (1,0) [0|100] "%" Vector__XXX

BO_ 2583175678 LatchStateInfo: 1 Vector__XXX
 SG_ PassLatchStateInfo : 6|2@1+ (1,0) [0|3] "" Vector__XXX
 SG_ DriverLatchStateInfo : 2|2@1+ (1,0) [0|3] "" Vector__XXX
 SG_ CenterLatchStateInfo : 0|2@1+ (1,0) [0|3] "" Vector__XXX

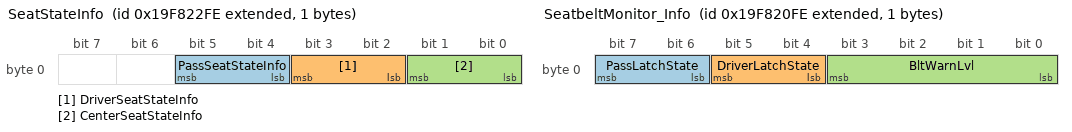
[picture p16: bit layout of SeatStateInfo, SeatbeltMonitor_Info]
BO_ 2583175934 SeatStateInfo: 1 Vector__XXX
 SG_ PassSeatStateInfo : 4|2@1+ (1,0) [0|3] "" Vector__XXX
 SG_ DriverSeatStateInfo : 2|2@1+ (1,0) [0|3] "" Vector__XXX
 SG_ CenterSeatStateInfo : 0|2@1+ (1,0) [0|3] "" Vector__XXX

BO_ 2381851134 HornSwitchState: 1 Vector__XXX
 SG_ HornSwitchReq : 0|2@1+ (1,0) [0|3] "" Vector__XXX

BO_ 2583175422 SeatbeltMonitor_Info: 1 Vector__XXX
 SG_ PassLatchState : 6|2@1+ (1,0) [0|3] "" Vector__XXX
 SG_ DriverLatchState : 4|2@1+ (1,0) [0|3] "" Vector__XXX
 SG_ BltWarnLvl : 0|4@1+ (1,0) [0|9] "" Vector__XXX

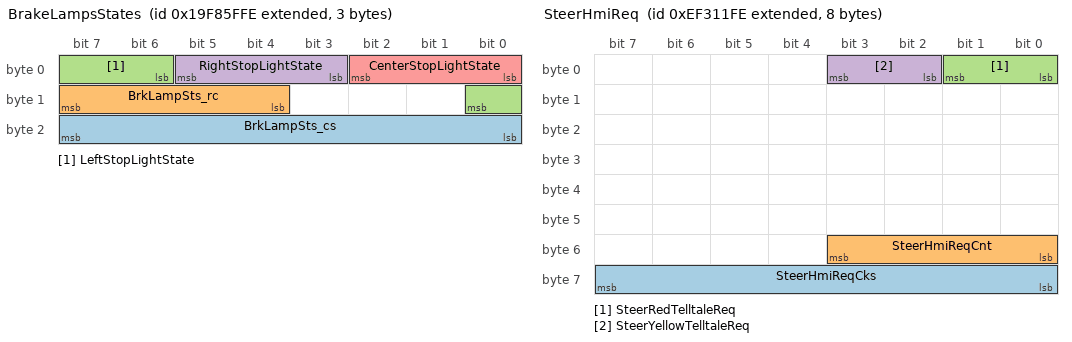
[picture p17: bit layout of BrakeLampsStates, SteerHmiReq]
BO_ 2583191550 BrakeLampsStates: 3 Vector__XXX
 SG_ BrkLampSts_cs : 16|8@1+ (1,0) [0|255] "" Vector__XXX
 SG_ BrkLampSts_rc : 12|4@1+ (1,0) [0|15] "" Vector__XXX
 SG_ LeftStopLightState : 6|3@1+ (1,0) [0|7] "" Vector__XXX
 SG_ RightStopLightState : 3|3@1+ (1,0) [0|7] "" Vector__XXX
 SG_ CenterStopLightState : 0|3@1+ (1,0) [0|7] "" Vector__XXX

BO_ 2398294526 SteerHmiReq: 8 VCU
 SG_ SteerHmiReqCks : 63|8@0+ (1,0) [0|255] "" Vector__XXX
 SG_ SteerHmiReqCnt : 51|4@0+ (1,0) [0|15] "" Vector__XXX
 SG_ SteerRedTelltaleReq : 1|2@0+ (1,0) [0|3] ""  HMI
 SG_ SteerYellowTelltaleReq : 3|2@0+ (1,0) [0|3] ""  HMI

BO_ 2381861118 STR_States: 8 Vector__XXX
 SG_ STRReadyToSleep : 2|2@1+ (1,0) [0|3] "" Vector__XXX
 SG_ STRReadyToDrive : 0|2@1+ (1,0) [0|3] "" Vector__XXX

BO_ 2566845694 TIRE1: 8 Vector__XXX
 SG_ TirePressThresholdDetection_00 m0 : 61|3@1+ (1,0) [0|7] "" Vector__XXX
 SG_ TirePressThresholdDetection_20 m32 : 61|3@1+ (1,0) [0|7] "" Vector__XXX
 SG_ TirePressThresholdDetection_21 m33 : 61|3@1+ (1,0) [0|7] "" Vector__XXX
 SG_ TirePressThresholdDetection_22 m34 : 61|3@1+ (1,0) [0|7] "" Vector__XXX
 SG_ TirePressThresholdDetection_23 m35 : 61|3@1+ (1,0) [0|7] "" Vector__XXX
 SG_ TirePressThresholdDetection_30 m48 : 61|3@1+ (1,0) [0|7] "" Vector__XXX
 SG_ TirePressThresholdDetection_31 m49 : 61|3@1+ (1,0) [0|7] "" Vector__XXX
 SG_ TirePressThresholdDetection_32 m50 : 61|3@1+ (1,0) [0|7] "" Vector__XXX
 SG_ TirePressThresholdDetection_33 m51 : 61|3@1+ (1,0) [0|7] "" Vector__XXX
 SG_ TirePressThresholdDetection_01 m1 : 61|3@1+ (1,0) [0|7] "" Vector__XXX
 SG_ TirePressThresholdDetection_10 m16 : 61|3@1+ (1,0) [0|7] "" Vector__XXX
 SG_ TirePressThresholdDetection_11 m17 : 61|3@1+ (1,0) [0|7] "" Vector__XXX
 SG_ TirePressThresholdDetection_12 m18 : 61|3@1+ (1,0) [0|7] "" Vector__XXX
 SG_ TirePressThresholdDetection_13 m19 : 61|3@1+ (1,0) [0|7] "" Vector__XXX
 SG_ TireAirLeakageRate_00 m0 : 40|16@1+ (0.1,0) [0|6425.5] "Pa/s" Vector__XXX
 SG_ TireAirLeakageRate_01 m1 : 40|16@1+ (0.1,0) [0|6425.5] "Pa/s" Vector__XXX
 SG_ TireAirLeakageRate_10 m16 : 40|16@1+ (0.1,0) [0|6425.5] "Pa/s" Vector__XXX
 SG_ TireAirLeakageRate_11 m17 : 40|16@1+ (0.1,0) [0|6425.5] "Pa/s" Vector__XXX
 SG_ TireAirLeakageRate_12 m18 : 40|16@1+ (0.1,0) [0|6425.5] "Pa/s" Vector__XXX
 SG_ TireAirLeakageRate_13 m19 : 40|16@1+ (0.1,0) [0|6425.5] "Pa/s" Vector__XXX
 SG_ TireAirLeakageRate_20 m32 : 40|16@1+ (0.1,0) [0|6425.5] "Pa/s" Vector__XXX
 SG_ TireAirLeakageRate_21 m33 : 40|16@1+ (0.1,0) [0|6425.5] "Pa/s" Vector__XXX
 SG_ TireAirLeakageRate_22 m34 : 40|16@1+ (0.1,0) [0|6425.5] "Pa/s" Vector__XXX
 SG_ TireAirLeakageRate_23 m35 : 40|16@1+ (0.1,0) [0|6425.5] "Pa/s" Vector__XXX
 SG_ TireAirLeakageRate_30 m48 : 40|16@1+ (0.1,0) [0|6425.5] "Pa/s" Vector__XXX
 SG_ TireAirLeakageRate_31 m49 : 40|16@1+ (0.1,0) [0|6425.5] "Pa/s" Vector__XXX
 SG_ TireAirLeakageRate_32 m50 : 40|16@1+ (0.1,0) [0|6425.5] "Pa/s" Vector__XXX
 SG_ TireAirLeakageRate_33 m51 : 40|16@1+ (0.1,0) [0|6425.5] "Pa/s" Vector__XXX
 SG_ ExTirePressSupport : 38|2@1+ (1,0) [0|3] "" Vector__XXX
 SG_ CTIWheelEndElectricalFault_00 m0 : 36|2@1+ (1,0) [0|3] "" Vector__XXX
 SG_ CTIWheelEndElectricalFault_01 m1 : 36|2@1+ (1,0) [0|3] "" Vector__XXX
 SG_ CTIWheelEndElectricalFault_10 m16 : 36|2@1+ (1,0) [0|3] "" Vector__XXX
 SG_ CTIWheelEndElectricalFault_11 m17 : 36|2@1+ (1,0) [0|3] "" Vector__XXX
 SG_ CTIWheelEndElectricalFault_12 m18 : 36|2@1+ (1,0) [0|3] "" Vector__XXX
 SG_ CTIWheelEndElectricalFault_13 m19 : 36|2@1+ (1,0) [0|3] "" Vector__XXX
 SG_ CTIWheelEndElectricalFault_20 m32 : 36|2@1+ (1,0) [0|3] "" Vector__XXX
 SG_ CTIWheelEndElectricalFault_21 m33 : 36|2@1+ (1,0) [0|3] "" Vector__XXX
 SG_ CTIWheelEndElectricalFault_22 m34 : 36|2@1+ (1,0) [0|3] "" Vector__XXX
 SG_ CTIWheelEndElectricalFault_23 m35 : 36|2@1+ (1,0) [0|3] "" Vector__XXX
 SG_ CTIWheelEndElectricalFault_30 m48 : 36|2@1+ (1,0) [0|3] "" Vector__XXX
 SG_ CTIWheelEndElectricalFault_31 m49 : 36|2@1+ (1,0) [0|3] "" Vector__XXX
 SG_ CTIWheelEndElectricalFault_32 m50 : 36|2@1+ (1,0) [0|3] "" Vector__XXX
 SG_ CTIWheelEndElectricalFault_33 m51 : 36|2@1+ (1,0) [0|3] "" Vector__XXX
 SG_ CTITireStatus_00 m0 : 34|2@1+ (1,0) [0|3] "" Vector__XXX
 SG_ CTITireStatus_01 m1 : 34|2@1+ (1,0) [0|3] "" Vector__XXX
 SG_ CTITireStatus_10 m16 : 34|2@1+ (1,0) [0|3] "" Vector__XXX
 SG_ CTITireStatus_11 m17 : 34|2@1+ (1,0) [0|3] "" Vector__XXX
 SG_ CTITireStatus_12 m18 : 34|2@1+ (1,0) [0|3] "" Vector__XXX
 SG_ CTITireStatus_13 m19 : 34|2@1+ (1,0) [0|3] "" Vector__XXX
 SG_ CTITireStatus_20 m32 : 34|2@1+ (1,0) [0|3] "" Vector__XXX
 SG_ CTITireStatus_21 m33 : 34|2@1+ (1,0) [0|3] "" Vector__XXX
 SG_ CTITireStatus_22 m34 : 34|2@1+ (1,0) [0|3] "" Vector__XXX
 SG_ CTITireStatus_23 m35 : 34|2@1+ (1,0) [0|3] "" Vector__XXX
 SG_ CTITireStatus_30 m48 : 34|2@1+ (1,0) [0|3] "" Vector__XXX
 SG_ CTITireStatus_31 m49 : 34|2@1+ (1,0) [0|3] "" Vector__XXX
 SG_ CTITireStatus_32 m50 : 34|2@1+ (1,0) [0|3] "" Vector__XXX
 SG_ CTITireStatus_33 m51 : 34|2@1+ (1,0) [0|3] "" Vector__XXX
 SG_ CTIWheelSensorStatus_00 m0 : 32|2@1+ (1,0) [0|3] "" Vector__XXX
 SG_ CTIWheelSensorStatus_01 m1 : 32|2@1+ (1,0) [0|3] "" Vector__XXX
 SG_ CTIWheelSensorStatus_10 m16 : 32|2@1+ (1,0) [0|3] "" Vector__XXX
 SG_ CTIWheelSensorStatus_11 m17 : 32|2@1+ (1,0) [0|3] "" Vector__XXX
 SG_ CTIWheelSensorStatus_12 m18 : 32|2@1+ (1,0) [0|3] "" Vector__XXX
 SG_ CTIWheelSensorStatus_13 m19 : 32|2@1+ (1,0) [0|3] "" Vector__XXX
 SG_ CTIWheelSensorStatus_20 m32 : 32|2@1+ (1,0) [0|3] "" Vector__XXX
 SG_ CTIWheelSensorStatus_21 m33 : 32|2@1+ (1,0) [0|3] "" Vector__XXX
 SG_ CTIWheelSensorStatus_22 m34 : 32|2@1+ (1,0) [0|3] "" Vector__XXX
 SG_ CTIWheelSensorStatus_23 m35 : 32|2@1+ (1,0) [0|3] "" Vector__XXX
 SG_ CTIWheelSensorStatus_30 m48 : 32|2@1+ (1,0) [0|3] "" Vector__XXX
 SG_ CTIWheelSensorStatus_31 m49 : 32|2@1+ (1,0) [0|3] "" Vector__XXX
 SG_ CTIWheelSensorStatus_32 m50 : 32|2@1+ (1,0) [0|3] "" Vector__XXX
 SG_ CTIWheelSensorStatus_33 m51 : 32|2@1+ (1,0) [0|3] "" Vector__XXX
 SG_ TireTemp_00 m0 : 16|16@1+ (0.03125,-273) [-273|1735] "C" Vector__XXX
 SG_ TireTemp_01 m1 : 16|16@1+ (0.03125,-273) [-273|1735] "C" Vector__XXX
 SG_ TireTemp_10 m16 : 16|16@1+ (0.03125,-273) [-273|1735] "C" Vector__XXX
 SG_ TireTemp_12 m18 : 16|16@1+ (0.03125,-273) [-273|1735] "C" Vector__XXX
 SG_ TireTemp_13 m19 : 16|16@1+ (0.03125,-273) [-273|1735] "C" Vector__XXX
 SG_ TireTemp_20 m32 : 16|16@1+ (0.03125,-273) [-273|1735] "C" Vector__XXX
 SG_ TireTemp_21 m33 : 16|16@1+ (0.03125,-273) [-273|1735] "C" Vector__XXX
 SG_ TireTemp_22 m34 : 16|16@1+ (0.03125,-273) [-273|1735] "C" Vector__XXX
 SG_ TireTemp_23 m35 : 16|16@1+ (0.03125,-273) [-273|1735] "C" Vector__XXX
 SG_ TireTemp_30 m48 : 16|16@1+ (0.03125,-273) [-273|1735] "C" Vector__XXX
 SG_ TireTemp_31 m49 : 16|16@1+ (0.03125,-273) [-273|1735] "C" Vector__XXX
 SG_ TireTemp_32 m50 : 16|16@1+ (0.03125,-273) [-273|1735] "C" Vector__XXX
 SG_ TireTemp_33 m51 : 16|16@1+ (0.03125,-273) [-273|1735] "C" Vector__XXX
 SG_ TireTemp_11 m17 : 16|16@1+ (0.03125,-273) [-273|1735] "C" Vector__XXX
 SG_ TirePress_00 m0 : 8|8@1+ (4,0) [0|1000] "kPa" Vector__XXX
 SG_ TirePress_01 m1 : 8|8@1+ (4,0) [0|1000] "kPa" Vector__XXX
 SG_ TirePress_10 m16 : 8|8@1+ (4,0) [0|1000] "kPa" Vector__XXX
 SG_ TirePress_11 m17 : 8|8@1+ (4,0) [0|1000] "kPa" Vector__XXX
 SG_ TirePress_12 m18 : 8|8@1+ (4,0) [0|1000] "kPa" Vector__XXX
 SG_ TirePress_13 m19 : 8|8@1+ (4,0) [0|1000] "kPa" Vector__XXX
 SG_ TirePress_20 m32 : 8|8@1+ (4,0) [0|1000] "kPa" Vector__XXX
 SG_ TirePress_21 m33 : 8|8@1+ (4,0) [0|1000] "kPa" Vector__XXX
 SG_ TirePress_22 m34 : 8|8@1+ (4,0) [0|1000] "kPa" Vector__XXX
 SG_ TirePress_23 m35 : 8|8@1+ (4,0) [0|1000] "kPa" Vector__XXX
 SG_ TirePress_30 m48 : 8|8@1+ (4,0) [0|1000] "kPa" Vector__XXX
 SG_ TirePress_31 m49 : 8|8@1+ (4,0) [0|1000] "kPa" Vector__XXX
 SG_ TirePress_32 m50 : 8|8@1+ (4,0) [0|1000] "kPa" Vector__XXX
 SG_ TirePress_33 m51 : 8|8@1+ (4,0) [0|1000] "kPa" Vector__XXX
 SG_ TireLocation M : 0|8@1+ (1,0) [0|255] "" Vector__XXX

BO_ 2650238974 ADAS_States: 8 Vector__XXX
 SG_ ADSReadyToSleep : 0|2@1+ (1,0) [0|3] "" Vector__XXX

BO_ 2600457214 VSM_DEBUG_OUT_1: 8 Vector__XXX
 SG_ VSM_Inp_BdShutDwnCrctVld : 63|1@1+ (1,0) [0|0] "" Vector__XXX
 SG_ VSM_Inp_BdShutDwnCrct : 62|1@1+ (1,0) [0|0] "" Vector__XXX
 SG_ VSM_GSSuggestedState : 60|2@1+ (1,0) [0|3] "" Vector__XXX
 SG_ VSM_DTS_Ignition : 59|1@1+ (1,0) [0|0] "" Vector__XXX
 SG_ VSM_DBG_DenyShutdown : 58|1@1+ (1,0) [0|0] "" Vector__XXX
 SG_ VSM_DBG_StandStill : 57|1@1+ (1,0) [0|0] "" Vector__XXX
 SG_ VSM_Inp_CrashValid : 56|1@1+ (1,0) [0|0] "" Vector__XXX
 SG_ VSM_Inp_BrPedPrValid : 55|1@1+ (1,0) [0|0] "" Vector__XXX
 SG_ VSM_Inp_VehSpdValid : 54|1@1+ (1,0) [0|0] "" Vector__XXX
 SG_ VSM_Inp_LvTopUp : 53|1@1+ (1,0) [0|0] "" Vector__XXX
 SG_ VSM_Inp_FlatBat : 52|1@1+ (1,0) [0|0] "" Vector__XXX
 SG_ VSM_Inp_HVBatStrReq : 51|1@1+ (1,0) [0|0] "" Vector__XXX
 SG_ VSM_Inp_VSMGSState : 48|3@1+ (1,0) [0|7] "" Vector__XXX
 SG_ VSM_Inp_OTAUpdReq : 45|3@1+ (1,0) [0|0] "" Vector__XXX
 SG_ VSM_Inp_Crash : 44|1@1+ (1,0) [0|0] "" Vector__XXX
 SG_ VSM_Inp_VehLockState : 42|2@1+ (1,0) [0|0] "" Vector__XXX
 SG_ VSM_Inp_ImmoState : 40|2@1+ (1,0) [0|0] "" Vector__XXX
 SG_ VSM_Inp_ChargeReq : 39|1@1+ (1,0) [0|0] "" Vector__XXX
 SG_ VSM_Inp_ThermCondReq : 38|1@1+ (1,0) [0|0] "" Vector__XXX
 SG_ VSM_Inp_ChrgPluggedIn : 37|1@1+ (1,0) [0|0] "" Vector__XXX
 SG_ VSM_Inp_ApprWakeReq : 36|1@1+ (1,0) [0|0] "" Vector__XXX
 SG_ VSM_Inp_DoorOpenSt : 35|1@1+ (1,0) [0|0] "" Vector__XXX
 SG_ VSM_Inp_DriverPres : 34|1@1+ (1,0) [0|0] "" Vector__XXX
 SG_ VSM_Inp_HMIWakeUp : 33|1@1+ (1,0) [0|0] "" Vector__XXX
 SG_ VSM_Inp_BrPedPr : 32|1@1+ (1,0) [0|0] "" Vector__XXX
 SG_ VSM_Inp_DriverDoorTPoint : 31|1@1+ (1,0) [0|0] "" Vector__XXX
 SG_ VSM_Int_DriverAbsenceTimer : 30|1@1+ (1,0) [0|0] "" Vector__XXX
 SG_ VSM_Int_ParkTimer : 29|1@1+ (1,0) [0|0] "" Vector__XXX
 SG_ VSM_Int_LowBatteryTimerCond : 28|1@1+ (1,0) [0|0] "" Vector__XXX
 SG_ VSM_Int_LowBatteryTimer : 27|1@1+ (1,0) [0|0] "" Vector__XXX
 SG_ VSM_Int_SleepTimer : 26|1@1+ (1,0) [0|0] "" Vector__XXX
 SG_ VSM_Int_Ready2AwakeSpeedCond : 25|1@1+ (1,0) [0|0] "" Vector__XXX
 SG_ VSM_StTran_Maint2Awake : 24|1@1+ (1,0) [0|0] "" Vector__XXX
 SG_ VSM_StTran_Awake2Maint : 23|1@1+ (1,0) [0|0] "" Vector__XXX
 SG_ VSM_StTran_Maint2InvAwake : 22|1@1+ (1,0) [0|0] "" Vector__XXX
 SG_ VSM_StTran_Maint2FullySleep : 21|1@1+ (1,0) [0|0] "" Vector__XXX
 SG_ VSM_StTran_Sleep2Maint : 20|1@1+ (1,0) [0|0] "" Vector__XXX
 SG_ VSM_StTran_FullySleep2InvAwake : 19|1@1+ (1,0) [0|0] "" Vector__XXX
 SG_ VSM_StTran_InvAwake2FullySleep : 18|1@1+ (1,0) [0|0] "" Vector__XXX
 SG_ VSM_StTran_Ready2Sleep : 17|1@1+ (1,0) [0|0] "" Vector__XXX
 SG_ VSM_StTran_Awake2Sleep : 16|1@1+ (1,0) [0|0] "" Vector__XXX
 SG_ VSM_StTran_Ready2Awake : 15|1@1+ (1,0) [0|0] "" Vector__XXX
 SG_ VSM_StTran_Awake2Ready : 14|1@1+ (1,0) [0|0] "" Vector__XXX
 SG_ VSM_StTran_Sleep2Awake : 13|1@1+ (1,0) [0|0] "" Vector__XXX
 SG_ VSM_Int_InitDecision : 9|4@1+ (1,0) [0|15] "" Vector__XXX
 SG_ VSM_Int_MandReadyValid : 8|1@1+ (1,0) [0|0] "" Vector__XXX
 SG_ VSM_InpRdy_ThermReady : 7|1@1+ (1,0) [0|0] "" Vector__XXX
 SG_ VSM_InpRdy_DTReady : 6|1@1+ (1,0) [0|0] "" Vector__XXX
 SG_ VSM_InpRdy_ChrgReady : 5|1@1+ (1,0) [0|0] "" Vector__XXX
 SG_ VSM_InpRdy_BrSys : 4|1@1+ (1,0) [0|0] "" Vector__XXX
 SG_ VSM_InpRdy_SteerReady : 3|1@1+ (1,0) [0|0] "" Vector__XXX
 SG_ VSM_InpRdy_LVReady : 2|1@1+ (1,0) [0|0] "" Vector__XXX
 SG_ VSM_InpRdy_HVReady : 1|1@1+ (1,0) [0|0] "" Vector__XXX
 SG_ VSM_Int_MandReady : 0|1@1+ (1,0) [0|0] "" Vector__XXX

BO_ 2399126014 COMMRequest1: 8 Vector__XXX
 SG_ HVBPCRequest : 2|2@1+ (1,0) [0|3] "" Vector__XXX
 SG_ HVBSMRequest : 0|2@1+ (1,0) [0|3] "" Vector__XXX

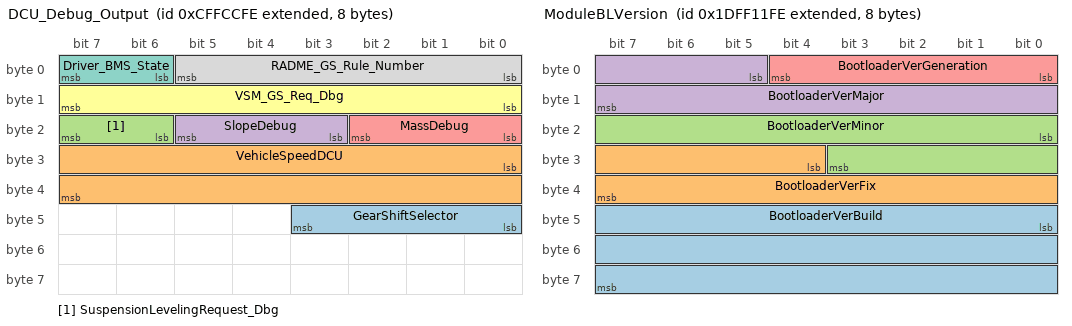
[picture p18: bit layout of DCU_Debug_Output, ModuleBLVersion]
BO_ 2365574398 DCU_Debug_Output: 8 Vector__XXX
 SG_ GearShiftSelector : 40|4@1+ (1,0) [0|0] "" Vector__XXX
 SG_ VehicleSpeedDCU : 24|16@1+ (0.004,-100) [-100|162.14] "kph" Vector__XXX
 SG_ SuspensionLevelingRequest_Dbg : 22|2@1+ (1,0) [0|0] "" Vector__XXX
 SG_ SlopeDebug : 19|3@1+ (0.01,-0.01) [-0.01|0.04] "rad" Vector__XXX
 SG_ MassDebug : 16|3@1- (500,5000) [3000|6500] "kg" Vector__XXX
 SG_ VSM_GS_Req_Dbg : 8|8@1- (1,0) [0|0] "" Vector__XXX
 SG_ Driver_BMS_State : 6|2@1+ (1,0) [0|0] "" Vector__XXX
 SG_ RADME_GS_Rule_Number : 0|6@1+ (1,0) [0|0] "" Vector__XXX

BO_ 2650739198 ModuleBLVersion: 8 Device
 SG_ BootloaderVerBuild : 40|24@1+ (1,0) [0|16777215] "" Vector__XXX
 SG_ BootloaderVerFix : 28|12@1+ (1,0) [0|4090] "" Vector__XXX
 SG_ BootloaderVerMinor : 16|12@1+ (1,0) [0|4095] "" Vector__XXX
 SG_ BootloaderVerMajor : 5|11@1+ (1,0) [0|2047] "" Vector__XXX
 SG_ BootloaderVerGeneration : 0|5@1+ (1,0) [0|31] "" Vector__XXX

CM_ BO_ 2180532222 "Control signals from light sensor #dbc\Software_Modules\Exterior_Lights\Light_Sensor\0.1.4.0\LightSens.dbc";
CM_ SG_ 2180532222 RLS_LsGlobalLux "Raw lux value provided by the RLS driver";
CM_ BO_ 2566845950 "Ambient Conditions #dbc\Software_Modules\Thermal_System\j1939_HVAC\0.1.1.0\j1939_HVAC.dbc";
CM_ SG_ 2566845950 RoadSurfaceTemp "Indicated temperature of road surface over which vehicle is operating.";
CM_ SG_ 2566845950 EngAirIntakeTemp "Temperature of air entering vehicle air induction system.";
CM_ SG_ 2566845950 AmbientAirTemp "Temperature of air surrounding vehicle.";
CM_ SG_ 2566845950 CabInteriorTemp "Temperature of air inside the part of the vehicle that encloses the driver and vehicle operating controls.

Note: See also SPN 1691.  SPN 1662 is an additional diagnostic SPN associated with cab temperature.";
CM_ SG_ 2566845950 BarometricPress "Absolute air pressure of the atmosphere.";
CM_ BO_ 2583065598 " #dbc\Software_Modules\Closures_System\CENTLOCK\0.3.1.0\CENTLOCK.dbc #dbc\Software_Modules\Closures_System\CENTLOCK\0.3.1.0\CENTLOCK.dbc";
CM_ SG_ 2583065598 CentralLockFailState "State of central lock command execution failure
";
CM_ SG_ 2583065598 CentralLockCommand "State of closures system command for doors central locking
";
CM_ BO_ 2515942654 "Cabin Climate Temperature State #dbc\Software_Modules\Thermal_System\Climate_System\0.3.1.0\Climate_System.dbc";
CM_ BO_ 2180392702 " #dbc\Software_Modules\Closures_System\Roller_Shutter\0.0.7.0\RollerShutter.dbc";
CM_ SG_ 2180392702 RollerShutterFaults "Indicates the roller shutter faults";
CM_ SG_ 2180392702 RollerShutterStatus "Indicates the sensed roller shutter state";
CM_ BO_ 2382107390 "Message with general information about current Drivetrain System state #dbc\Software_Modules\Braking_System\BRK_ext\0.1.1.0\BRK_ext.dbc";
CM_ BO_ 2399121662 "Message with LV system states #dbc\Software_Modules\LV_System\LVSYSOP\0.2.9.0\LVSYSOP.dbc #dbc\Software_Modules\LV_System\LVSYSOP\0.2.9.0\LVSYSOP.dbc #dbc\Software_Modules\LV_System\LVSYSOP\0.2.9.0\LVSYSOP.dbc";
CM_ SG_ 2399121662 LVReadyToUpdate "Feedback that device ready for FW update";
CM_ SG_ 2399121662 LVReadyToSleep "Signals if the LV Controller is ready to sleep";
CM_ SG_ 2399121662 LVAllowedLoad "LV load permission depending on a load shedding request";
CM_ SG_ 2399121662 LVNotificationReq "LV Notification request";
CM_ SG_ 2399121662 DrivetrainLimpModeReq "Drivetrain Limp mode request";
CM_ SG_ 2399121662 LVAlertFlatBattery "flat battery alarm";
CM_ SG_ 2399121662 LVTopUpRequest "whether either of the LV Batteries require charging";
CM_ SG_ 2399121662 LVSystemCharging "ALDC LV Controller charging state";
CM_ SG_ 2399121662 LVReadyToDrive "ALDC LV Controller Ready to Drive state";
CM_ SG_ 2399121662 LVState "ALDC LV Controller state";
CM_ BO_ 2365435390 "The message containing the request on external light sources from the operator's external light control switch(s). #dbc\Software_Modules\Exterior_Lights\ExtLightsSystem\0.3.4.0\ExtLightsSystem.dbc";
CM_ SG_ 2365435390 MainBeamStalksReq "A 2 bit parameter to indicate the selected position of the operator's main light stalk";
CM_ SG_ 2365435390 TurnIndReq "A 4 bit parameter to indicate the selected position of the operator's turn signal stalk";
CM_ SG_ 2365435390 SwitchReq "A 2 bit parameter to indicate the selected position of operator's switch";
CM_ BO_ 2365473278 "Lighting Command
The lighting command message has been defined as a global message from the tractor to all lighting controllers on the tractor and attached implements.  Separate messages are provided for tractor and implement work and driving ... #dbc\j1939MISRA\0.0.8.2\j1939.dbc";
CM_ SG_ 2365473278 ImplementRearWorkLightCmd "Command to activate or de-activate implement rear work lights.  (This is also the same as Reversing Lights for truck applications.)  

00 De-activate
01 Activate
10 Reserved
11 Don't Care";
CM_ SG_ 2365473278 ImplLeftFacingWorkLightCmd "Command to activate or de-activate the left facing work lights toward the left end of the implement.

00 De-activate
01 Activate
10 Reserved
11 Don't Care";
CM_ SG_ 2365473278 ImplRightFwdWorkLightCmd "Command to activate or de-activate the forward facing work lights toward the right end of the implement.

00 De-activate
01 Activate
10 Reserved
11 Don't Care";
CM_ SG_ 2365473278 LightingDataRqCmd "Command to provide a response of the light state

00 De-activate
01 Activate
10 Reserved
11 Don't Care";
CM_ SG_ 2365473278 ImplLeftForwardWorkLightCmd "Command to activate or de-activate work lights mounted on an implement to illuminate beyond left end of the implement.

00 De-activate
01 Activate
10 Reserved
11 Don't Care";
CM_ SG_ 2365473278 ImplRightFacingWorkLightCmd "Command to activate or de-activate work lights mounted on an implement to illuminate beyond right end of the implement.

00 De-activate
01 Activate
10 Reserved
11 Don't Care";
CM_ SG_ 2365473278 ImplOEMOption1LightCmd "Command to activate or de-activate an implement OEM option 1 light.  This is provided to meet special needs on implements, such as tank inspection or filling lights.

00 De-activate
01 Activate
10 Reserved
11 Don't Care";
CM_ SG_ 2365473278 ImplOEMOption2LightCmd "Command to activate or de-activate an implement OEM option 2 light.  This is provided to meet special needs on implements, such as tank inspection or filling lights.

00 De-activate
01 Activate
10 Reserved
11 Don't Care";
CM_ SG_ 2365473278 TrctrFrntHghMdWkLightsCmd "Command to activate or de-activate the tractor front high mounted work lights.

00 De-activate
01 Activate
10 Reserved
11 Don't Care";
CM_ SG_ 2365473278 TrctrFrntLowMdWkLightsCmd "Command to activate or de-activate the tractor front low mounted work lights.

00 De-activate
01 Activate
10 Reserved
11 Don't Care";
CM_ SG_ 2365473278 TrctrSdeHighMdWkLightsCmd "Command to activate or de-activate the tractor side high mounted work lights.

00 De-activate
01 Activate
10 Reserved
11 Don't Care";
CM_ SG_ 2365473278 TrctrSideLowMdWkLightsCmd "Command to activate or de-activate the tractor side low mounted work lights.

00 De-activate
01 Activate
10 Reserved
11 Don't Care";
CM_ SG_ 2365473278 TrctrRarHighMdWkLightsCmd "Command to activate or de-activate the tractor rear high  mounted work lights.

00 De-activate
01 Activate
10 Reserved
11 Don't Care";
CM_ SG_ 2365473278 TrctrRearLowMdWkLightsCmd "Command to activate or de-activate the tractor rear low  mounted work lights.

00 De-activate
01 Activate
10 Reserved
11 Don't Care";
CM_ SG_ 2365473278 TrctrUndrsdeMdWkLightsCmd "Command to activate or de-activate the tractor underside mounted work lights.

00 De-activate
01 Activate
10 Reserved
11 Don't Care";
CM_ SG_ 2365473278 RearFogLightsCmd "Command to activate or de-activate tractor or implement rear fog lights.  

00 De-activate
01 Activate
10 Reserved
11 Don't Care";
CM_ SG_ 2365473278 TractorMarkerLightCmd "Command to activate or de-activate tractor and implement front position lights, rear red tail lights, side amber running lights, license plate lights and instrument and switch back lights.  

00 De-activate
01 Activate
10 Reserved
11 Don't Care";
CM_ SG_ 2365473278 ImplementMarkerLightCmd "Command to activate or de-activate implement front position lights, rear red tail lights, side amber running lights, license plate lights and instrument and switch back lights.  

00 De-activate
01 Activate
10 Reserved
11 Don't Care";
CM_ SG_ 2365473278 TractorClearanceLightCmd "Command to activate or de-activate the tractor high mounted clearance and center ID lights

00 De-activate
01 Activate
10 Reserved
11 Don't Care";
CM_ SG_ 2365473278 ImplementClearanceLightCmd "Command to activate or de-activate the implement high mounted clearance and lights.  

00 De-activate
01 Activate
10 Reserved
11 Don't Care";
CM_ SG_ 2365473278 LeftStopLightCmd "Command to activate or de-activate the tractor and implement left stop lights

00 De-activate
01 Activate
10 Reserved
11 Don't Care";
CM_ SG_ 2365473278 RightStopLightCmd "Command to activate or de-activate the tractor and implement right stop light

00 De-activate
01 Activate
10 Reserved
11 Don't Care";
CM_ SG_ 2365473278 CenterStopLightCmd "Command to activate or de-activate the tractor and implement center stop light

00 De-activate
01 Activate
10 Reserved
11 Don't Care";
CM_ SG_ 2365473278 BackUpLightAndAlarmHornCmd "Command to activate or de-activate the back up lights and/ or associated alarm if required

00 De-activate
01 Activate
10 Reserved
11 Don't Care";
CM_ SG_ 2365473278 LeftTurnSignalLightsCmd "Command to activate or de-activate left turn signal lights on the tractor and all connected implements

00 De-activate
01 Activate
10 Reserved
11 Don't Care";
CM_ SG_ 2365473278 RightTurnSignalLightsCmd "Command to activate or de-activate right turn signal lights on the tractor and all connected implements

00 De-activate
01 Activate
10 Reserved
11 Don't Care";
CM_ SG_ 2365473278 RotatingBeaconLightCmd "Command to activate or de-activate slow moving vehicle indicator lights on tractor and/or implements.  Activation of the slow moving vehicle lights implies that the controller should manipulate the lighting as appropriate to provide the slow moving ...";
CM_ SG_ 2365473278 TractorFrontFogLightsCmd "Command to activate or de-activate tractor front fog lights.

00 De-activate
01 Activate
10 Reserved
11 Don't Care";
CM_ SG_ 2365473278 HighBeamHeadLightCmd "Command to activate or de-activate the tractor high beam head light lamps. 

00 De-activate
01 Activate
10 Reserved
11 Don't Care";
CM_ SG_ 2365473278 LowBeamHeadLightCmd "Command to activate or de-activate the tractor low beam head light lamps. 

00 De-activate
01 Activate
10 Reserved
11 Don't Care";
CM_ SG_ 2365473278 AltBeamHeadLightCmd "Command to activate or de-activate the tractor alternate head lights (only low beam is available on alternate head lights).  The alternate position lights are intended for use with loader and snow plows that tend to block the primary head lights.
 ...";
CM_ SG_ 2365473278 RunningLightCmd "Command to activate or de-activate the tractor or powered vehicle running lights.  Usually only used for on road vehicles.

00 De-activate
01 Activate
10 Reserved
11 Don't Care";
CM_ BO_ 2566799614 "Lighting Data
This lighting message is a response to the request for lighting data in the lighting command message.  Each lighting controller on the tractor and attached implements must transmit this message to the Tractor ECU when requested.  The ... #dbc\j1939MISRA\0.0.8.2\j1939.dbc";
CM_ SG_ 2566799614 ImplementRearWorkLight "This parameter provides measured data from the implement rear work lamps.

00 De-activated
01 Activated
10 Fault Detected
11 Not Available";
CM_ SG_ 2566799614 ImplLeftFacingWorkLight "This parameter provides measured data from the left facing work lights toward the left end of the implement.

00 De-activated
01 Activated
10 Fault Detected
11 Not Available";
CM_ SG_ 2566799614 ImplRightForwardWorkLight "This parameter provides measured data from the forward facing work lights toward the right end of the implement.

00 De-activated
01 Activated
10 Fault Detected
11 Not Available";
CM_ SG_ 2566799614 ImplLeftForwardWorkLight "This parameter provides measured data from the work lights mounted on an implement to illuminate the forward left end of the implement.

00 De-activate
01 Activate
10 Fault Detected
11 Not Available";
CM_ SG_ 2566799614 ImplRightFacingWorkLight "This parameter provides measured data from the work lights mounted on an implement to illuminate beyond right end of the implement.

00 De-activated
01 Activated
10 Fault Detected
11 Not Available";
CM_ SG_ 2566799614 ImplementOEMOption1Light "This parameter provides measured data from the implement OEM option 1 light.

00 De-activated
01 Activated
10 Fault Detected
11 Not Available";
CM_ SG_ 2566799614 ImplementOEMOption2Light "This parameter provides measured data from the implement OEM option 2 light.

00 De-activated
01 Activated
10 Fault Detected
11 Not Available";
CM_ SG_ 2566799614 TrctorFrontHighMdWkLights "This parameter provides measured data from the tractor front high mounted work lights. 

00 De-activated
01 Activated
10 Fault Detected
11 Not Available";
CM_ SG_ 2566799614 TractorFrontLowMdWkLights "This parameter provides measured data from the tractor front low mounted work lights. 

00 De-activated
01 Activated
10 Fault Detected
11 Not Available";
CM_ SG_ 2566799614 TractorSideHighMdWkLights "This parameter provides measured data from the tractor side high mounted work lights. 

00 De-activated
01 Activated
10 Fault Detected
11 Not Available";
CM_ SG_ 2566799614 TractorSideLowMdWkLights "This parameter provides measured data from the tractor side low mounted work lights. 

00 De-activated
01 Activated
10 Fault Detected
11 Not Available";
CM_ SG_ 2566799614 TractorRearHighMdWkLights "This parameter provides measured data from the tractor rear high mounted work lights. 

00 De-activated
01 Activated
10 Fault Detected
11 Not Available";
CM_ SG_ 2566799614 TractorRearLowMdWkLights "This parameter provides measured data from the tractor rear low mounted work lights.

00 De-activated
01 Activated
10 Fault Detected
11 Not Available";
CM_ SG_ 2566799614 TrctorUndersideMdWkLights "This parameter provides measured data from the tractor underside mounted work lights. 

00 De-activated
01 Activated
10 Fault Detected
11 Not Available";
CM_ SG_ 2566799614 RearFogLights "This parameter provides measured data from the tractor and/or implement rear fog lights.

00 De-activated
01 Activated
10 Fault Detected
11 Not Available";
CM_ SG_ 2566799614 TractorMarkerLight "This parameter provides measured data from the tractor and attached implement marker lights, including front position lights, rear tail lights, side running lights, license plate lights and instruments and switch back lights.
00 De-activated
01 ...";
CM_ SG_ 2566799614 ImplementMarkerLight "This parameter provides measured data from an attached implement marker lights, including front position lights, rear tail lights, side running lights, license plate lights and instruments and switch back lights.
00 De-activated
01 Activated
10 ...";
CM_ SG_ 2566799614 TractorClearanceLight "This parameter provides measured data from the tractor high mounted clearance and center ID lights.

00 De-activated
01 Activated
10 Fault Detected
11 Not Available";
CM_ SG_ 2566799614 ImplementClearanceLight "This parameter provides measured data from an attached implement high mounted clearance lights.

00 De-activated
01 Activated
10 Fault Detected
11 Not Available";
CM_ SG_ 2566799614 LeftStopLight "This parameter provides measured data from the tractor and attached implement left stop lights.

00 De-activated
01 Activated
10 Fault Detected
11 Not Available";
CM_ SG_ 2566799614 RightStopLight "This parameter provides measured data from the tractor and attached implement right stop lights.

00 De-activated
01 Activated
10 Fault Detected
11 Not Available";
CM_ SG_ 2566799614 CenterStopLight "This parameter provides measured data from the tractor and attached implement center stop lights.

00 De-activated
01 Activated
10 Fault Detected
11 Not Available";
CM_ SG_ 2566799614 BackUpLightAndAlarmHorn "This parameter provides measured data from the back up lights and/ or associated alarm.

00 De-activated
01 Activated
10 Fault Detected
11 Not Available";
CM_ SG_ 2566799614 LeftTurnSignalLights "This parameter provides measured data from the tractor and attached implement left turn signal lights.

00 De-activated
01 Activated
10 Fault Detected
11 Not Available";
CM_ SG_ 2566799614 RightTurnSignalLights "This parameter provides measured data from the tractor and attached implement right turn signal lights.

00 De-activated
01 Activated
10 Fault Detected
11 Not Available";
CM_ SG_ 2566799614 RotatingBeaconLight "This parameter provides measured data from the beacon light on tractor or attached implements.

00 De-activated
01 Activated
10 Fault Detected
11 Not Available";
CM_ SG_ 2566799614 TractorFrontFogLights "This parameter provides measured data from the tractor front fog lights.

00 De-activated
01 Activated
10 Fault Detected
11 Not Available";
CM_ SG_ 2566799614 HighBeamHeadLight "This parameter provides measured data from the tractor high beam head light lamps. 

00 De-activated
01 Activated
10 Fault Detected
11 Not Available";
CM_ SG_ 2566799614 LowBeamHeadLight "This parameter provides measured data from the tractor low beam head light lamps. 

00 De-activated
01 Activated
10 Fault Detected
11 Not Available";
CM_ SG_ 2566799614 AltBeamHeadLight "This parameter provides measured data from the tractor alternate beam head light lamps. 

00 De-activated
01 Activated
10 Fault Detected
11 Not Available";
CM_ SG_ 2566799614 RunningLight "This parameter provides measured data from the vehicle's running lights.

00 De-activated
01 Activated
10 Fault Detected
11 Not Available";
CM_ BO_ 2565868030 "Vehicle Dynamic Stability Control 2
Contains information which relates to the vehicle's movement. #dbc\j1939MISRA\0.0.8.2\j1939.dbc";
CM_ SG_ 2565868030 LongitudinalAcceleration "Indicates the longitudinal acceleration of the vehicle. A positive longitudinal acceleration signal results when the vehicle speed increases, regardless of driving the vehicle forward or backward.  This parameter is applicable to vehicle speed ...";
CM_ SG_ 2565868030 LateralAcceleration "Indicates a lateral acceleration of the vehicle (the component of vehicle acceleration vector along the Y-axis). A positive lateral acceleration signal results when the vehicle is accelerated to the left.  This parameter is defined according to a ...";
CM_ SG_ 2565868030 YawRate "Indicates the rate of rotation about the vertical axis (i.e. the z-axis).  A positive yaw rate signal results when the vehicle turns counter-clockwise.   This parameter is defined according to a Z-Up axis system and the sign of the value is in ...";
CM_ SG_ 2565868030 SteerWheelAngleSensorType "Indicates whether the steering wheel angle sensor is capable of absolute measuring of the number of steering wheel turns or not (relative measuring to position at ignition on).
00 Relative measuring principle
01 Absolute measuring principle
10 ...";
CM_ SG_ 2565868030 SteerWheelTurnCounter "Indicates number of steering wheel turns, absolute position or relative position at ignition on. Positive values indicate left turns.";
CM_ SG_ 2565868030 SteerWheelAngle "The main operator`s steering wheel angle (on the steering column, not the actual wheel angle).  The vehicle being steered to the left (counterclockwise) results in a positive steering wheel angle.  This is the yaw angle of the steering wheel with ...";
CM_ BO_ 2365583358 "Operators External Light Controls Message
The message containing the information about the position of the operator's external light control switch(s).  Including switches for the Headlights, turn signals, hazard light, clearance lights, marker ... #dbc\Software_Modules\Exterior_Lights\HazardSwitch\0.0.3.0\HazardSwitch.dbc";
CM_ SG_ 2365583358 HazardLightSwitch "A 2 bit parameter to indicate the selected position of the operator's hazard light switch.

00   Hazard Lamps to be Off
01   Hazard Lamps to be Flashing
10   Error
11   Not available (do not change)";
CM_ BO_ 2566767870 "Electronic Brake Controller 5
Used for information on brake control. #dbc\j1939MISRA\0.0.8.2\j1939.dbc";
CM_ SG_ 2566767870 EmergencyBrakingActive "Signal which indicates an emergency braking situation (ref. ECE Regulation 13 paragraph 5.2.1.31) with high  deceleration values.  This signal can be used to activate the hazard lights (ref ECE Regulation 48 paragraph 6.23) to
indicate other road ...";
CM_ SG_ 2566767870 PrkngBrakeActuatorFullyActivated "Signal which indicates when the parking brake actuator is fully activated.  (see also SPN 70 and 619).

00 - Parking Brake Actuator not fully activated
01 - Parking Brake Actuator fully activated
10 - Error
11 - Not available";
CM_ SG_ 2566767870 XBRAccelerationLimit "The brake system may temporarily or generally limit the maximum brake performance available for external systems. A temporary limit may be nessary due to high brake temperature; a general limit may be defined by the vehicle manufacturer, e.g. a ...";
CM_ SG_ 2566767870 XBRActiveCtrlMode "This parameter indicates which XBR Control Mode is executed by the brake system.
0000                No brake demand being executed (default mode)
0001                Driver's brake demand being executed, no external brake demand
0010 ...";
CM_ SG_ 2566767870 XBRSystemState "This parameter indicates which external brake control is allowed.
00 - Any external brake demand will be accepted (brake system fully operational)
01 - Only external brake demand of highest XBR Priority (00) will be accepted  (e.g. because the ...";
CM_ SG_ 2566767870 FoundationBrakeUse "This parameter indicates if the brake system presently uses the foundation brakes.

00   Foundation brakes not in use
01   Foundation brakes in use
10   Reserved
11   Not available";
CM_ SG_ 2566767870 HillHolderMode "Signal which indicates the current mode of the hill holder function.
000            Inactive
001            Active
010            Active, but will change to inactive in a short time.  (This mode may be used to warn the driver)
011 ...";
CM_ SG_ 2566767870 HaltBrakeMode "Signal which indicates the current mode of the halt brake function.
000            Inactive
001            Active
010            Active, but not functioning properly.  (This mode may be used to warn the driver)
011 - 101  Not defined
110 ...";
CM_ SG_ 2566767870 BrakeTempWarning "This parameter indicates if the temperature in the service brakes exceeds a certain value. It can be used for a warning information for the driver. The temperature warning value is vehicle manufacturer specific.
00 Not Active
01 Active
10 ...";
CM_ BO_ 2365484286 "Tachograph #dbc\j1939MISRA\0.0.8.2\j1939.dbc #dbc\j1939MISRA\0.0.8.2\j1939.dbc";
CM_ SG_ 2365484286 TachographVehicleSpeed "Speed of the vehicle registered by the tachograph.";
CM_ SG_ 2365484286 TachographOutputShaftSpeed "Calculated speed of the transmission output shaft.";
CM_ SG_ 2365484286 DirectionIndicator "Indicates the direction of the vehicle.

00 - Forward
01 - Reverse
10 - Error
11 - Not available";
CM_ SG_ 2365484286 TachographPerformance "Indicates the tachograph performance; including electronic or mechanical analysis, instrument analysis, speed sensor analysis, mass storage analysis, and printer analysis.
00 - Normal performance
01 - Performance analysis
10 - Error
11 - Not ...";
CM_ SG_ 2365484286 HandlingInformation "Indicates that handling information is present.  Information could include 'no printer paper', 'no driver card', etc.

00 - No handling information
01 - Handling information
10 - Error
11 - Not available";
CM_ SG_ 2365484286 SystemEvent "Indicates that a tachograph event has occurred.  This may include power supply interruption, interruption of the speed sensor, incorrect data on the driver card, driving without a driver card, illegal removal of a driver card, insertion of a driver ...";
CM_ SG_ 2365484286 DriverCardDriver2 "Indicates the presence of a driver card

00 - Driver card not present
01 - Driver card present
10 - Error
11 - Not available";
CM_ SG_ 2365484286 Driver2TimeRelatedStates "Indicates if the driver approaches or exceeds working time limits (or other limits).
0000 Normal/No limits reached
0001 Limit #1 - 15 min before 4  h
0010 Limit #2 - 4  h reached
0011 Limit #3 - 15 min before 9 h
0100 Limit #4 - 9 h reached
 ...";
CM_ SG_ 2365484286 VehicleOverspeed "Indicates whether the vehicle is exceeding the legal speed limit set in the tachograph.

00 No overspeed
01 Overspeed
10 Error
11 Not available";
CM_ SG_ 2365484286 DriverCardDriver1 "Indicates the presence of a driver card

00 - Driver card not present
01 - Driver card present
10 - Error
11 - Not available";
CM_ SG_ 2365484286 Driver1TimeRelatedStates "Indicates if the driver approaches or exceeds working time limits (or other limits).
0000 Normal/No limits reached
0001 Limit #1 - 15 min before 4  h
0010 Limit #2 - 4  h reached
0011 Limit #3 - 15 min before 9 h
0100 Limit #4 - 9 h reached
 ...";
CM_ SG_ 2365484286 VehicleMotion "Indicates whether motion of the vehicle is detected or not.

00 Vehicle motion not detected
01 Vehicle motion detected
10 - Error
11 - Not available";
CM_ SG_ 2365484286 Driver2WorkingState "State of work of the driver.  

000 Rest - sleeping
001 Driver available - short break
010 Work - loading, unloading, working in an office
011 Drive - behind wheel 
100-101 Reserved
110 Error
111 Not available";
CM_ SG_ 2365484286 Driver1WorkingState "State of work of the driver.  

000 Rest - sleeping
001 Driver available - short break
010 Work - loading, unloading, working in an office
011 Drive - behind wheel 
100-101 Reserved
110 Error
111 Not available";
CM_ BO_ 2180924414 " #dbc\Components\BMS\Arrival_Charging_Controller\0.1.14.0\Arrival_Charging_Controller.dbc";
CM_ SG_ 2180924414 CCI_ACPlugLockPosition "Lock position of the plug lock on the AC side charging port lock.";
CM_ SG_ 2180924414 CCI_ACDCPortHatchState "State of the ACDC port charging hatch";
CM_ SG_ 2180924414 CCI_ACDCPlugConnectionEvent "ACDC charging port plug connection event.";
CM_ SG_ 2180924414 CCI_ACPortHatchState "State of the AC port charging hatch";
CM_ SG_ 2180924414 CCI_ACPortButtonState "AC Charging port button state.";
CM_ SG_ 2180924414 CCI_ACDCPortButtonState "ACDC Charging port button state.";
CM_ SG_ 2180924414 CCI_ACPlugConnectionEvent "AC charging port plug connection event.";
CM_ BO_ 2382314494 "Contains information about states of Gear Selector, Drivetrain, Gearbox Interlock and GS Request Sources.
 #dbc\GearSelector\GS\0.0.4.0\GS.dbc #dbc\GearSelector\GS\0.0.4.0\GS.dbc";
CM_ SG_ 2382314494 GS_VSMInhibits "Gear Selector Request from VSM";
CM_ SG_ 2382314494 GS_Inhibits "Gear Selector Request from VSM";
CM_ SG_ 2382314494 Inaccess_Req_5 "Flag  of the VSM request inaccessibility. If it is true then VSM GS request signal is valid but not correct in current circumstances";
CM_ SG_ 2382314494 Inaccess_Req_4 "Flag  of the HMI3 request inaccessibility. If it is true then HMI3 GS request signal is valid but not correct in current circumstances";
CM_ SG_ 2382314494 Inaccess_Req_3 "Flag  of the HMI2 request inaccessibility. If it is true then HMI2 GS request signal is valid but not correct in current circumstances";
CM_ SG_ 2382314494 Inaccess_Req_2 "Flag  of the HMI1 request inaccessibility. If it is true then HMI1 GS request signal is valid but not correct in current circumstances";
CM_ SG_ 2382314494 GS_Est_State "Gear Selector State estimated by Gear Selector module";
CM_ SG_ 2382314494 Drvtr_state "Drivetrain state calculated by Gear Selector module";
CM_ SG_ 2382314494 Inaccess_Req_1 "Flag  of the AI request inaccessibility. If it is true then AI GS request signal is valid but not correct in current circumstances";
CM_ SG_ 2382314494 move_lock_req "Move-locking device request";
CM_ SG_ 2382314494 GS_Demand "Gear selecor demand";
CM_ BO_ 2180926462 " #dbc\Components\BMS\Arrival_Charging_Controller\0.1.14.0\Arrival_Charging_Controller.dbc";
CM_ SG_ 2180926462 CCI_ACDCHatchCloseCmd "ACDC Charging port hatch close permission.";
CM_ SG_ 2180926462 CCI_ACDCPlugLockRequest "CCI Plug lock request";
CM_ SG_ 2180926462 ACDCPortCmd_Counter "Counter for CHRG_ACDCPortCmd message.";
CM_ SG_ 2180926462 ACDCPortCmd_CRC "CRC for CHRG_ACDCPortCmd message.";
CM_ BO_ 2399117310 "For DEBUG-TEST only! Consist of signals that can replace AIN siganls from Analog button block #dbc\Software_Modules\Vehicle_State_Machine\SimpVSM\0.0.3.0\SimpVSM.dbc #dbc\Software_Modules\Vehicle_State_Machine\SimpVSM\0.0.3.0\SimpVSM.dbc";
CM_ SG_ 2399117310 VSM_CRC "Gear selector request from AI";
CM_ SG_ 2399117310 VSM_Cnt "Gear selector request from AI";
CM_ SG_ 2399117310 VSM_State "Gear selector request from AI";
CM_ BO_ 2566883070 "Notifications from Doors to AVAS #dbc\Software_Modules\Closures_System\CLSAVAS\0.1.2.0\CLSAVAS.dbc #dbc\Software_Modules\Closures_System\CLSAVAS\0.1.2.0\CLSAVAS.dbc";
CM_ SG_ 2566883070 RollerShutterLatchNotify "Roller Shutter AVAS notification";
CM_ SG_ 2566883070 DoorLatchNotify "Doors AVAS notification";
CM_ BO_ 2382241534 " #dbc\Software_Modules\Thermal_System\VanThermal\0.7.0.0\VanThermal.dbc";
CM_ BO_ 2297441790 "Acceleration Sensor
The acceleration sensor message shall provide a measurement of the vehicle's acceleration in the lateral, longitudinal, and vertical axes.  The vehicle dynamics measurements in this message shall be according to a Z-Up axis ... #dbc\j1939MISRA\0.0.8.2\j1939.dbc";
CM_ SG_ 2297441790 SpprtVrblTrnsRpttnRtFrAcclrtnSns "Indicates which acceleration transmission rate are supported by the ECU in addition to the required 10 ms transmission rate.
00 - Reserve for SAE assignment
01 - Reserved for SAE assignment
10 - 20 ms rate supported
11 - ECU only supports ...";
CM_ SG_ 2297441790 VrtclAcclrtnExRangeFigureOfMerit "Figure of merit for vertical acceleration measurement.
00 = vertical acceleration is fully functional.  Data is within sensor specification
01 = verticalacceleration is degraded.  Data is suspect due to enviromental conditions
10 = error
11 = ...";
CM_ SG_ 2297441790 LngtdnlAcclrtnExRngFigureOfMerit "Figure of merit for longitudinal acceleration measurement.
00 = longitudinal acceleration is fully functional.  Data is within sensor specification
01 = longitudinal acceleration is degraded.  Data is suspect due to enviromental conditions
10 = ...";
CM_ SG_ 2297441790 LtrlAcclrtonExRangeFigureOfMerit "Figure of merit for lateral acceleration measurement.
00 = lateral acceleration is fully functional.  Data is within sensor specification
01 = lateral acceleration is degraded.  Data is suspect due to enviromental conditions
10 = error
11 = not ...";
CM_ SG_ 2297441790 VerticalAccelerationExRange "Indicates vertical acceleration of the vehicle and the effect of gravity (the component of vehicle acceleration vector along the Z-axis).  A positive vertical acceleration signal of 1 gravity results when the vehicle is stationary on a horizontal ...";
CM_ SG_ 2297441790 LongitudinalAccelerationExRange "Indicates longitudinal acceleration of the vehicle (the component of vehicle acceleration vector along the X-axis).  A positive longitudinal acceleration signal results when the vehicle speed increases in the forward direction.  Longitudinal ...";
CM_ SG_ 2297441790 LateralAccelerationExRange "Indicates lateral acceleration of the vehicle (the component of vehicle acceleration vector along the Y-axis).  A positive lateral acceleration signal results when the vehicle is accelerated to the left.  This parameter is defined according to a ...";
CM_ BO_ 2583173886 "Requests from the HMI to the Washer and Wiper controllers. #dbc\Software_Modules\Windshield_Wash_Wipe\WPRWSH\0.0.8.0\WPRWSH.dbc";
CM_ SG_ 2583173886 WipeRequest "Request from the HMI to the Wiper Controller.";
CM_ SG_ 2583173886 WashRequest "Request from the HMI to the Washer Controller.";
CM_ BO_ 2516075518 "The message contains the actual status of the suspension height.
HDLGHTLVL 1.0.0->ActualRideHeight #dbc\Software_Modules\Suspension_Control_System\HMI_SLC\0.2.0.1\HMI_SLC.dbc";
CM_ BO_ 2566882814 " #dbc\Components\Comunication_module\KeyFob\0.0.0.0\KeyFob.dbc";
CM_ SG_ 2566882814 KeyRange "Key fob range state
";
CM_ SG_ 2566882814 KeyCommand "Key fob command for doors central locking
";
CM_ BO_ 2583062526 " #dbc\Software_Modules\Closures_System\CENTLOCK\0.3.1.0\CENTLOCK.dbc";
CM_ SG_ 2583062526 CentralLockRequest "State of user request for doors central locking
";
CM_ BO_ 2399123966 "For DEBUG-TEST only! Consist of signals that can replace AIN siganls from Analog button block #dbc\Components\Comunication_module\ArrivalSecurity\0.1.2.0\ArrivalSecurity.dbc";
CM_ SG_ 2399123966 KeyfobBatteryState "Actual State of the Keyfob Battery";
CM_ BO_ 2583065854 " #dbc\Software_Modules\Closures_System\CENTLOCK\0.3.1.0\CENTLOCK.dbc";
CM_ SG_ 2583065854 CentralLockRequest "State of user request for doors central locking
";
CM_ BO_ 2163223550 "Crash Notification
This message is transmitted in case of a crash event.
The message contains information about the Crash Type, a Crash Counter and a Checksum. The function of the Crash Counter is to prevent other ECU's from reacting to a faulty ... #dbc\j1939MISRA\0.0.8.2\j1939.dbc #dbc\j1939MISRA\0.0.8.2\j1939.dbc #dbc\j1939MISRA\0.0.8.2\j1939.dbc";
CM_ SG_ 2163223550 CrashChecksum "The Crash Checksum is used to verify the signal path from the airbag ECU to other devices in case of a crash.
The 4 bit checksum is the sum of the high nibble and the low nibble of the sum of the identifier, the first 7 data bytes and the 4 bit ...";
CM_ SG_ 2163223550 CrashCounter "The Crash Counter prevents other ECUs from reacting to a faulty transmission of the Crash Notification PGN and serves as a safety mechanism. The Crash Counter becomes incremented by 1 for every sent message, starting with '0'. (0 follows 15)";
CM_ SG_ 2163223550 CrashType "Type of crash event. 

00001 = frontal crash
00010 = rear crash
00100 = side crash (left)
01000 = side crash (right)
10000 = rollover

It is possible to combine different Crash Types. (e.g. frontal and side crash (left) = 00101)";
CM_ BO_ 2448507902 "Vehicle Weight message with VGW information from Payload Management #dbc\Software_Modules\Payload_Management\PYLDSYS\0.0.7.0\PYLDSYS.dbc";
CM_ SG_ 2448507902 RHSensorsFault "Status of data flow from Ride Height Sensors";
CM_ SG_ 2448507902 PMSWarning "Figure of merit for ride height measurement.

00 - Ride height fully functional.  Data is within sensor specification. 
01 - Ride height degraded.  Data is suspect due to environmental conditions.
10 - Error
11 - Not available";
CM_ SG_ 2448507902 VehicleGrossWeight "Minimum value from ride height sensors measured on axles including distance unsprung mass";
CM_ BO_ 2448508158 "Vehicle Weight message with processed IMU  information from Payload Management #dbc\Software_Modules\Payload_Management\PYLDSYS\0.0.7.0\PYLDSYS.dbc";
CM_ SG_ 2448508158 IMUFault "Status of data flow from IMU";
CM_ BO_ 2583180030 " #dbc\Software_Modules\Thermal_System\HGCS\0.3.4.0\HGCS.dbc";
CM_ BO_ 2583179774 " #dbc\Software_Modules\Thermal_System\HGCS\0.3.4.0\HGCS.dbc";
CM_ BO_ 2499547902 "Cab Door Control
This message requests or commands the cabin door functionality; door latches, windows, and mirrors. Doors are numbered left to right, front to back. #dbc\j1939MISRA\0.0.8.2\j1939.dbc";
CM_ SG_ 2499547902 MirrorRight2HeatCmd "Command to activate heater for second mirror on the right side (passenger side for left-hand steer vehicle).  Mirror heat may be expected to latch in the 'on' state upon receipt of the command, stay on while the command is 'take no action' and turn ...";
CM_ SG_ 2499547902 MirrorLeft2HeatCmd "Command to activate heater for second mirror on the left side (driver side for left-hand steer vehicle).  Mirror heat may be expected to latch in the 'on' state upon receipt of the command, stay on while the command is 'take no action' and turn off ...";
CM_ SG_ 2499547902 MirrorRight1HeatCmd "Command to activate heater for primary mirror on the right side (passenger side for left-hand steer vehicle).  Mirror heat may be expected to latch in the 'on' state upon receipt of the command, stay on while the command is 'take no action' and turn ...";
CM_ SG_ 2499547902 MirrorLeft1HeatCmd "Command to activate heater for primary mirror on the left side (driver side for left-hand steer vehicle).  Mirror heat may be expected to latch in the 'on' state upon receipt of the command, stay on while the command is 'take no action' and turn off ...";
CM_ SG_ 2499547902 MirrorRight2VerticalCmd "Commands vertical position change of the second mirror on the right side (passenger side for lefthand steer vehicles).

00 = Move up
01 = Move down
10 = Reserved
11 = Take no action";
CM_ SG_ 2499547902 MirrorRight2HorizontalCmd "Commands horizontal position change of the second mirror on the right side (passenger side for lefthand steer vehicles).

00 = Move left
01 = Move right
10 = Reserved
11 = Take no action";
CM_ SG_ 2499547902 MirrorLeft2VerticalCmd "Commands vertical position change of the second mirror on the left side (driver side for left-hand steer vehicles). 

00 = Move up
01 = Move down
10 = Reserved
11 = Take no action";
CM_ SG_ 2499547902 MirrorLeft2HorizontalCmd "Commands horizontal position change of the second mirror on the left side (driver side for left-hand steer vehicles).

00 = Move left
01 = Move right
10 = Reserved
11 = Take no action";
CM_ SG_ 2499547902 MirrorRight1VerticalCmd "Commands vertical position change of the primary mirror on the right side (passenger side for lefthand steer vehicles).

00 = Move up
01 = Move down
10 = Reserved
11 = Take no action";
CM_ SG_ 2499547902 MirrorRight1HorizontalCmd "Commands horizontal position change of the primary mirror on the right side (passenger side for lefthand steer vehicles).

00 = Move left
01 = Move right
10 = Reserved
11 = Take no action";
CM_ SG_ 2499547902 MirrorLeft1VerticalCmd "Commands vertical position change of the primary mirror on the left side (driver side for left-hand steer vehicles).

00 = Move up
01 = Move down
10 = Reserved
11 = Take no action";
CM_ SG_ 2499547902 MirrorLeft1HorizontalCmd "Commands horizontal position change of the primary mirror on the left side (driver side for left-hand steer vehicles).

00 = Move left
01 = Move right
10 = Reserved
11 = Take no action";
CM_ SG_ 2499547902 RightRearWindowPosCmd "Commands position change of the right rear window.

000 = Window move up
001 = Window move down
010 = Window auto up
011 = Window auto down
100 = Reserved
101 = Reserved
110 = Reserved
111 = Take no action";
CM_ SG_ 2499547902 LeftRearWindowPosCmd "Commands position change of left rear window.

000 = Window move up
001 = Window move down
010 = Window auto up
011 = Window auto down
100 = Reserved
101 = Reserved
110 = Reserved
111 = Take no action";
CM_ SG_ 2499547902 RightFrontWindowPosCmd "Commands position change of right front window (passenger door window on left-hand steer vehicles).
000 = Window move up
001 = Window move down
010 = Window auto up
011 = Window auto down
100 = Reserved
101 = Reserved
110 = Reserved
111 = ...";
CM_ SG_ 2499547902 LeftFrontWindowPosCmd "Commands position change of left front window (driver door window on left-hand steer vehicles).
000 = Window move up
001 = Window move down
010 = Window auto up
011 = Window auto down
100 = Reserved
101 = Reserved
110 = Reserved
111 = Take ...";
CM_ SG_ 2499547902 RemoteCabDoorLockReq "Request to the cab door lock controller from Remote Keyless Entry or or other external device to lock or unlock doors.
This parameter is different from Cab Doors Lock Actuation Command (SPN xxxx) because this is a request to actuate door locks ...";
CM_ SG_ 2499547902 DoorsLockActCmd "Commands cab door latch state change: lock or unlock.
000 = Unlock left front cab door latch (driver door on LH steer vehicles)
001 = Unlock right front cab door latch (front passenger door for LH steer vehicles)
010 = Unlock left rear cab door ...";
CM_ BO_ 2583177470 "Rain data from the Rain Sensor Driver. #dbc\Software_Modules\Windshield_Wash_Wipe\WPRWSH\0.0.8.0\WPRWSH.dbc";
CM_ SG_ 2583177470 RainIntensity "Rain intensity logical interpretation.";
CM_ BO_ 2364552702 " #dbc\Components\Comunication_module\ArrivalSecurity\0.1.2.0\ArrivalSecurity.dbc";
CM_ BO_ 2582766846 " #dbc\Software_Modules\Safety_System\Alarm_system\0.1.2.0\ALARMDRV.dbc";
CM_ SG_ 2582766846 ACU_Active "State of siren ";
CM_ SG_ 2582766846 ACU_Alarm "State of alarm";
CM_ SG_ 2582766846 USS_Status "Arm or disarm USS status ";
CM_ SG_ 2582766846 ACU_Status "Arm or disarm ACU status ";
CM_ SG_ 2582766846 Intrusion_detected "State of intrusion detection
";
CM_ BO_ 2565865982 "Electronic Brake Controller 1
Used for brake control information #dbc\j1939MISRA\0.0.8.2\j1939.dbc";
CM_ SG_ 2565865982 TrctrMntdTrailerABSWarningSignal "This parameter commands the tractor-mounted trailer ABS optical warning signal.

00 Off
01 On 
10 Reserved
11 Take no action";
CM_ SG_ 2565865982 TrailerABSStatus "State signal which indicates that ABS in the trailer is actively controlling the brakes.  A message is sent to the tractor from the trailer (i.e. by PLC). The receiving device in the tractor transfers this information to the J1939 network.  At the ...";
CM_ SG_ 2565865982 HaltBrakeSwitch "Switch signal which indicates the position of the halt brake switch.

00    Halt brake switch passive
01    Halt brake switch active
10    Error
11    Not available";
CM_ SG_ 2565865982 SrcAddrssOfCntrllngDvcFrBrkeCtrl "The source address of the SAE J1939 device currently controlling the brake system. Its value may be the source address of the ECU transmitting the message (which means that no external SAE J1939 message is providing the active command) or the source ...";
CM_ SG_ 2565865982 ATC_ASRInformationSignal "This parameter commands the ATC/ASR driver information signal, for example a dash lamp.

00 Off
01 On 
10 Reserved
11 Take no action";
CM_ SG_ 2565865982 ABS_EBSAmberWarningSignal "This parameter commands the ABS/EBS amber/yellow optical warning signal

00 Off
01 On
10 Reserved
11 Take no action";
CM_ SG_ 2565865982 EBSRedWarningSignal "This parameter commands the EBS red optical warning signal

00 Off
01 On
10 Reserved
11 Take no action";
CM_ SG_ 2565865982 ABSFullyOperational "Signal which indicates whether an ABS system is fully operational or whether its functionality is reduced by a defect or by an intended action (e.g., by activation of an ABS-off-road switch or during special diagnostic procedures).  There are cases ...";
CM_ SG_ 2565865982 EngRetarderSelection "The position of the operator controlled selector, expressed as a percentage and determined by the ratio of the current position of the selector to its maximum possible position. Zero percent means no braking torque is requested by the operator from ...";
CM_ SG_ 2565865982 RemoteAccelEnableSwitch "Switch signal which indicates that the remote accelerator has been enabled and controls the engine.
00 - Off
01 - On
10 - Error
11 - Not available
NOTE-The accelerator interlock switch (see SPN 972) must be disabled in order for the remote ...";
CM_ SG_ 2565865982 EngAuxShutdownSwitch "Switch signal which requests that all engine fueling stop.

00 - Off
01 - On
10 - Error
11 - Not available";
CM_ SG_ 2565865982 EngDerateSwitch "Switch signal used to activate the torque limiting feature of the engine.  The specific nature of torque limiting should be verified with the manufacturer.

00 - Off
01 - On
10 - Error
11 - Not available";
CM_ SG_ 2565865982 AccelInterlockSwitch "Switch signal used to disable the accelerator and remote accelerator inputs, causing the engine to return to idle.

00 - Off
01 - On
10 - Error
11 - Not available";
CM_ SG_ 2565865982 TractionCtrlOverrideSwitch "Switch signal which indicates the position of the traction control override switch.  The traction control override signal disables the automatic traction control function allowing the wheels to spin.
00 - Off
01 - On
10 - Error
11 - Not ...";
CM_ SG_ 2565865982 ASRHillHolderSwitch "Switch signal which indicates the position of the ASR 'hill holder' switch.

00 - ASR 'hill holder' switch passive
01 - ASR 'hill holder' switch active
10 - Error
11 - Not available";
CM_ SG_ 2565865982 ASROffroadSwitch "Switch signal which indicates the position of the ASR off-road switch.

00 - ASR off-road switch passive
01 - ASR off-road switch active
10 - Error
11 - Not available";
CM_ SG_ 2565865982 ABSOffroadSwitch "Switch signal which indicates the position of the ABS off-road switch.

00 - ABS off-road switch passive
01 - ABS off-road switch active
10 - Error
11 - Not available";
CM_ SG_ 2565865982 BrakePedalPos "Ratio of brake pedal position to maximum pedal position.  Used for electric brake applications. 0% means no braking. Also when there are two brake pedals on the machine (Left Brake Pedal Position SPN 3033 and Right Brake Pedal Position SPN 3032) the ...";
CM_ SG_ 2565865982 EBSBrakeSwitch "Switch signal which indicates that the brake pedal is being pressed.  The EBS brake switch is independent of the brake light switch and has no provisions for external connections.
00 - Brake pedal is not being pressed
01 - Brake pedal is being ...";
CM_ SG_ 2565865982 AntiLockBrakingActive "State signal which indicates that the ABS is active.  The signal is set active when wheel brake pressure actually starts to be modulated by ABS and is reset to passive when all wheels are in a stable condition for a certain time.  The signal can ...";
CM_ SG_ 2565865982 ASRBrakeCtrlActive "State signal which indicates that ASR brake control is active. Active means that ASR actually controls wheel brake pressure at one or more wheels of the driven axle(s).
00 - ASR brake control passive but installed
01 - ASR brake control active
10 ...";
CM_ SG_ 2565865982 ASREngCtrlActive "State signal which indicates that ASR engine control has been commanded to be active. Active means that ASR actually tries to control the engine. This state signal is independent of other control commands to the engine (e.g., from the transmission) ...";
CM_ BO_ 2583173374 "Wiper faults detected by the Wiper Controller. #dbc\Software_Modules\Windshield_Wash_Wipe\WPRWSH\0.0.8.0\WPRWSH.dbc";
CM_ SG_ 2583173374 WiperSilenceFault "Indicates if Wiper Driver feedback is not on CAN network.";
CM_ SG_ 2583173374 WiperHomePosFault "Indicates if Wiper failed ''home position''.";
CM_ SG_ 2583173374 WiperControlFault "Indicates if Wiper failed to execute command from the Wiper Controller.";
CM_ BO_ 2381731326 " #dbc\Components\HMI\Smart_TP\0.2.5.0\SmartTP.dbc";
CM_ BO_ 2583062270 " #dbc\Software_Modules\Closures_System\CabinDoors\0.2.2.0\CabinDoors.dbc";
CM_ SG_ 2583062270 DoorsSleepReadyState "The status of all vehicle doors ";
CM_ SG_ 2583062270 CargoSideDoorLatchState "Actual state of the door latch";
CM_ SG_ 2583062270 CargoRearDoorLatchState "Actual state of the door latch";
CM_ SG_ 2583062270 BulkheadDoorLatchState "Actual state of the door latch";
CM_ SG_ 2583062270 PassDoorLatchState "Actual state of the door latch";
CM_ SG_ 2583062270 DriverDoorLatchState "Actual state of the door latch";
CM_ SG_ 2583062270 DoorsOpenState "The status of all vehicle doors ";
CM_ BO_ 2516060670 " #dbc\Software_Modules\ParkAssist\PA\0.1.2.0\ParkAssistance.dbc";
CM_ BO_ 2516060414 " #dbc\Software_Modules\ParkAssist\PA\0.1.2.0\ParkAssistance.dbc";
CM_ BO_ 2516059134 " #dbc\Software_Modules\ParkAssist\PA\0.1.2.0\ParkAssistance.dbc";
CM_ BO_ 2516059390 " #dbc\Software_Modules\ParkAssist\PA\0.1.2.0\ParkAssistance.dbc";
CM_ BO_ 2516059646 " #dbc\Software_Modules\ParkAssist\PA\0.1.2.0\ParkAssistance.dbc";
CM_ BO_ 2381723902 " #dbc\StaticInternal\TMS\Climate\0.1.0.0\Climate_int.dbc";
CM_ BO_ 2583063294 "Cab Door Control
This message requests or commands the cabin windows #dbc\Software_Modules\Closures_System\WindowControl\0.0.1.0\WindowControl.dbc";
CM_ SG_ 2583063294 WindowPosCmd "Commands position change of the right rear window.

000 = Window move up
001 = Window move down
010 = Window auto up
011 = Window auto down
100 = Reserved
101 = Reserved
110 = Reserved
111 = Take no action";
CM_ BO_ 2515942398 " #dbc\Software_Modules\Thermal_System\Climate_System\0.3.1.0\Climate_System.dbc";
CM_ BO_ 2515949566 " #dbc\Software_Modules\Thermal_System\Climate_System\0.3.1.0\Climate_System.dbc";
CM_ BO_ 2515942142 "Cabin Climate Controller State #dbc\Software_Modules\Thermal_System\Climate_System\0.3.1.0\Climate_System.dbc";
CM_ BO_ 2515942910 "Cabin Climate HVAC Request #dbc\StaticInternal\TMS\Climate\0.1.0.0\Climate_int.dbc";
CM_ BO_ 2583175678 "Message with information from seatbelts and seatmats monitor #dbc\Software_Modules\Safety_System\SEATBELT\0.3.2.0\SEATBELT.dbc";
CM_ SG_ 2583175678 PassLatchStateInfo "Passenger seatbelt fastener and seatmat combined state";
CM_ SG_ 2583175678 DriverLatchStateInfo "Driver seatbelt fastener and seatmat combined state";
CM_ SG_ 2583175678 CenterLatchStateInfo "Center passenger seatbelt fastener state";
CM_ BO_ 2583175934 "Message with information from seatbelts and seatmats monitor #dbc\Software_Modules\Safety_System\SEATBELT\0.3.2.0\SEATBELT.dbc";
CM_ SG_ 2583175934 PassSeatStateInfo "Passenger seatmat state";
CM_ SG_ 2583175934 DriverSeatStateInfo "Driver seatmat state";
CM_ SG_ 2583175934 CenterSeatStateInfo "Center passenger seatmat state";
CM_ BO_ 2381851134 " #dbc\Software_Modules\Safety_System\HORN\0.1.2.0\HORN.dbc";
CM_ SG_ 2381851134 HornSwitchReq "True - horn switch request active
False - horn switch request not active";
CM_ BO_ 2583175422 "Message with information from seatbelts and seatmats monitor #dbc\Software_Modules\Safety_System\SEATBELT\0.3.2.0\SEATBELT.dbc";
CM_ SG_ 2583175422 PassLatchState "Passenger seatbelt fastener and seatmat combined state";
CM_ SG_ 2583175422 DriverLatchState "Driver seatbelt fastener and seatmat combined state";
CM_ SG_ 2583175422 BltWarnLvl "Seatbelt minder warning level for driver and passenger.";
CM_ BO_ 2583191550 " #dbc\Software_Modules\Exterior_Lights\ELS_ext\0.1.1.0\ELS_ext.dbc";
CM_ BO_ 2398294526 "E2E protection: Autosar 1A
DATAID: 0x311 #dbc\Software_Modules\Steering_System\SteerHmi\0.1.0.0\SteerHmi.dbc";
CM_ SG_ 2398294526 SteerHmiReqCks "E2E CRC";
CM_ SG_ 2398294526 SteerHmiReqCnt "E2E Counter";
CM_ BO_ 2381861118 "Braking signals #dbc\Software_Modules\Steering_System\STR_HV\0.2.2.0\STR_HV.dbc";
CM_ BO_ 2566845694 "Tire Condition Message 1
Tire Condition Message
NOTE  Multiple instances of this message will be required to transmit data for all tire locations.  When reporting data for multiple tire locations, each successive message, which provides data for ... #dbc\Software_Modules\TPMS\j1939_TPMS\0.0.3.0\j1939_TPMS.dbc";
CM_ SG_ 2566845694 TirePressThresholdDetection_00 "Signal indicating the pressure level of the tire.";
CM_ SG_ 2566845694 TirePressThresholdDetection_20 "Signal indicating the pressure level of the tire.";
CM_ SG_ 2566845694 TirePressThresholdDetection_21 "Signal indicating the pressure level of the tire.";
CM_ SG_ 2566845694 TirePressThresholdDetection_22 "Signal indicating the pressure level of the tire.";
CM_ SG_ 2566845694 TirePressThresholdDetection_23 "Signal indicating the pressure level of the tire.";
CM_ SG_ 2566845694 TirePressThresholdDetection_30 "Signal indicating the pressure level of the tire.";
CM_ SG_ 2566845694 TirePressThresholdDetection_31 "Signal indicating the pressure level of the tire.";
CM_ SG_ 2566845694 TirePressThresholdDetection_32 "Signal indicating the pressure level of the tire.";
CM_ SG_ 2566845694 TirePressThresholdDetection_33 "Signal indicating the pressure level of the tire.";
CM_ SG_ 2566845694 TirePressThresholdDetection_01 "Signal indicating the pressure level of the tire.";
CM_ SG_ 2566845694 TirePressThresholdDetection_10 "Signal indicating the pressure level of the tire.";
CM_ SG_ 2566845694 TirePressThresholdDetection_11 "Signal indicating the pressure level of the tire.";
CM_ SG_ 2566845694 TirePressThresholdDetection_12 "Signal indicating the pressure level of the tire.";
CM_ SG_ 2566845694 TirePressThresholdDetection_13 "Signal indicating the pressure level of the tire.";
CM_ SG_ 2566845694 TireAirLeakageRate_00 "The pressure loss rate of a tire.";
CM_ SG_ 2566845694 TireAirLeakageRate_01 "The pressure loss rate of a tire.";
CM_ SG_ 2566845694 TireAirLeakageRate_10 "The pressure loss rate of a tire.";
CM_ SG_ 2566845694 TireAirLeakageRate_11 "The pressure loss rate of a tire.";
CM_ SG_ 2566845694 TireAirLeakageRate_12 "The pressure loss rate of a tire.";
CM_ SG_ 2566845694 TireAirLeakageRate_13 "The pressure loss rate of a tire.";
CM_ SG_ 2566845694 TireAirLeakageRate_20 "The pressure loss rate of a tire.";
CM_ SG_ 2566845694 TireAirLeakageRate_21 "The pressure loss rate of a tire.";
CM_ SG_ 2566845694 TireAirLeakageRate_22 "The pressure loss rate of a tire.";
CM_ SG_ 2566845694 TireAirLeakageRate_23 "The pressure loss rate of a tire.";
CM_ SG_ 2566845694 TireAirLeakageRate_30 "The pressure loss rate of a tire.";
CM_ SG_ 2566845694 TireAirLeakageRate_31 "The pressure loss rate of a tire.";
CM_ SG_ 2566845694 TireAirLeakageRate_32 "The pressure loss rate of a tire.";
CM_ SG_ 2566845694 TireAirLeakageRate_33 "The pressure loss rate of a tire.";
CM_ SG_ 2566845694 ExTirePressSupport "Defines the choice of using the tire pressure (PGN 65268) or Extended Tire Pressure (PGN 64578). The state value '01' indicates the extended tire pressure SPN is used for the pressure data. Any other value indicates the extended tire pressure SPN is ...";
CM_ SG_ 2566845694 CTIWheelEndElectricalFault_00 "Indicates the status of electrical fault on CTI wheel interface.";
CM_ SG_ 2566845694 CTIWheelEndElectricalFault_01 "Indicates the status of electrical fault on CTI wheel interface.";
CM_ SG_ 2566845694 CTIWheelEndElectricalFault_10 "Indicates the status of electrical fault on CTI wheel interface.";
CM_ SG_ 2566845694 CTIWheelEndElectricalFault_11 "Indicates the status of electrical fault on CTI wheel interface.";
CM_ SG_ 2566845694 CTIWheelEndElectricalFault_12 "Indicates the status of electrical fault on CTI wheel interface.";
CM_ SG_ 2566845694 CTIWheelEndElectricalFault_13 "Indicates the status of electrical fault on CTI wheel interface.";
CM_ SG_ 2566845694 CTIWheelEndElectricalFault_20 "Indicates the status of electrical fault on CTI wheel interface.";
CM_ SG_ 2566845694 CTIWheelEndElectricalFault_21 "Indicates the status of electrical fault on CTI wheel interface.";
CM_ SG_ 2566845694 CTIWheelEndElectricalFault_22 "Indicates the status of electrical fault on CTI wheel interface.";
CM_ SG_ 2566845694 CTIWheelEndElectricalFault_23 "Indicates the status of electrical fault on CTI wheel interface.";
CM_ SG_ 2566845694 CTIWheelEndElectricalFault_30 "Indicates the status of electrical fault on CTI wheel interface.";
CM_ SG_ 2566845694 CTIWheelEndElectricalFault_31 "Indicates the status of electrical fault on CTI wheel interface.";
CM_ SG_ 2566845694 CTIWheelEndElectricalFault_32 "Indicates the status of electrical fault on CTI wheel interface.";
CM_ SG_ 2566845694 CTIWheelEndElectricalFault_33 "Indicates the status of electrical fault on CTI wheel interface.";
CM_ SG_ 2566845694 CTITireStatus_00 "Indicates the status of the tire.";
CM_ SG_ 2566845694 CTITireStatus_01 "Indicates the status of the tire.";
CM_ SG_ 2566845694 CTITireStatus_10 "Indicates the status of the tire.";
CM_ SG_ 2566845694 CTITireStatus_11 "Indicates the status of the tire.";
CM_ SG_ 2566845694 CTITireStatus_12 "Indicates the status of the tire.";
CM_ SG_ 2566845694 CTITireStatus_13 "Indicates the status of the tire.";
CM_ SG_ 2566845694 CTITireStatus_20 "Indicates the status of the tire.";
CM_ SG_ 2566845694 CTITireStatus_21 "Indicates the status of the tire.";
CM_ SG_ 2566845694 CTITireStatus_22 "Indicates the status of the tire.";
CM_ SG_ 2566845694 CTITireStatus_23 "Indicates the status of the tire.";
CM_ SG_ 2566845694 CTITireStatus_30 "Indicates the status of the tire.";
CM_ SG_ 2566845694 CTITireStatus_31 "Indicates the status of the tire.";
CM_ SG_ 2566845694 CTITireStatus_32 "Indicates the status of the tire.";
CM_ SG_ 2566845694 CTITireStatus_33 "Indicates the status of the tire.";
CM_ SG_ 2566845694 CTIWheelSensorStatus_00 "Indicates whether the wheel is being monitored by the CTI controller.";
CM_ SG_ 2566845694 CTIWheelSensorStatus_01 "Indicates whether the wheel is being monitored by the CTI controller.";
CM_ SG_ 2566845694 CTIWheelSensorStatus_10 "Indicates whether the wheel is being monitored by the CTI controller.";
CM_ SG_ 2566845694 CTIWheelSensorStatus_11 "Indicates whether the wheel is being monitored by the CTI controller.";
CM_ SG_ 2566845694 CTIWheelSensorStatus_12 "Indicates whether the wheel is being monitored by the CTI controller.";
CM_ SG_ 2566845694 CTIWheelSensorStatus_13 "Indicates whether the wheel is being monitored by the CTI controller.";
CM_ SG_ 2566845694 CTIWheelSensorStatus_20 "Indicates whether the wheel is being monitored by the CTI controller.";
CM_ SG_ 2566845694 CTIWheelSensorStatus_21 "Indicates whether the wheel is being monitored by the CTI controller.";
CM_ SG_ 2566845694 CTIWheelSensorStatus_22 "Indicates whether the wheel is being monitored by the CTI controller.";
CM_ SG_ 2566845694 CTIWheelSensorStatus_23 "Indicates whether the wheel is being monitored by the CTI controller.";
CM_ SG_ 2566845694 CTIWheelSensorStatus_30 "Indicates whether the wheel is being monitored by the CTI controller.";
CM_ SG_ 2566845694 CTIWheelSensorStatus_31 "Indicates whether the wheel is being monitored by the CTI controller.";
CM_ SG_ 2566845694 CTIWheelSensorStatus_32 "Indicates whether the wheel is being monitored by the CTI controller.";
CM_ SG_ 2566845694 CTIWheelSensorStatus_33 "Indicates whether the wheel is being monitored by the CTI controller.";
CM_ SG_ 2566845694 TireTemp_00 "Temperature at the surface of the tire sidewall.";
CM_ SG_ 2566845694 TireTemp_01 "Temperature at the surface of the tire sidewall.";
CM_ SG_ 2566845694 TireTemp_10 "Temperature at the surface of the tire sidewall.";
CM_ SG_ 2566845694 TireTemp_12 "Temperature at the surface of the tire sidewall.";
CM_ SG_ 2566845694 TireTemp_13 "Temperature at the surface of the tire sidewall.";
CM_ SG_ 2566845694 TireTemp_20 "Temperature at the surface of the tire sidewall.";
CM_ SG_ 2566845694 TireTemp_21 "Temperature at the surface of the tire sidewall.";
CM_ SG_ 2566845694 TireTemp_22 "Temperature at the surface of the tire sidewall.";
CM_ SG_ 2566845694 TireTemp_23 "Temperature at the surface of the tire sidewall.";
CM_ SG_ 2566845694 TireTemp_30 "Temperature at the surface of the tire sidewall.";
CM_ SG_ 2566845694 TireTemp_31 "Temperature at the surface of the tire sidewall.";
CM_ SG_ 2566845694 TireTemp_32 "Temperature at the surface of the tire sidewall.";
CM_ SG_ 2566845694 TireTemp_33 "Temperature at the surface of the tire sidewall.";
CM_ SG_ 2566845694 TireTemp_11 "Temperature at the surface of the tire sidewall.";
CM_ SG_ 2566845694 TirePress_00 "Pressure at which air is contained in cavity formed by tire and rim.";
CM_ SG_ 2566845694 TirePress_01 "Pressure at which air is contained in cavity formed by tire and rim.";
CM_ SG_ 2566845694 TirePress_10 "Pressure at which air is contained in cavity formed by tire and rim.";
CM_ SG_ 2566845694 TirePress_11 "Pressure at which air is contained in cavity formed by tire and rim.";
CM_ SG_ 2566845694 TirePress_12 "Pressure at which air is contained in cavity formed by tire and rim.";
CM_ SG_ 2566845694 TirePress_13 "Pressure at which air is contained in cavity formed by tire and rim.";
CM_ SG_ 2566845694 TirePress_20 "Pressure at which air is contained in cavity formed by tire and rim.";
CM_ SG_ 2566845694 TirePress_21 "Pressure at which air is contained in cavity formed by tire and rim.";
CM_ SG_ 2566845694 TirePress_22 "Pressure at which air is contained in cavity formed by tire and rim.";
CM_ SG_ 2566845694 TirePress_23 "Pressure at which air is contained in cavity formed by tire and rim.";
CM_ SG_ 2566845694 TirePress_30 "Pressure at which air is contained in cavity formed by tire and rim.";
CM_ SG_ 2566845694 TirePress_31 "Pressure at which air is contained in cavity formed by tire and rim.";
CM_ SG_ 2566845694 TirePress_32 "Pressure at which air is contained in cavity formed by tire and rim.";
CM_ SG_ 2566845694 TirePress_33 "Pressure at which air is contained in cavity formed by tire and rim.";
CM_ SG_ 2566845694 TireLocation "Identifies which tire is associated with the parametric data in this PGN.
The low order 4 bits represent a position number, counting left to right when facing in the direction of normal vehicle travel (forward).
The high order 4 bits represent a ...";
CM_ BO_ 2650238974 " #dbc\Components\ADAS\0.2.0.0\ADAS_Data.dbc";
CM_ BO_ 2600457214 " #dbc\StaticInternal\VSS\SimpVSM_DBG\0.1.0.0\SimpVSM_DBG.dbc";
CM_ SG_ 2600457214 VSM_Inp_BdShutDwnCrctVld "BoardShutDownCorrectValid
";
CM_ SG_ 2600457214 VSM_Inp_BdShutDwnCrct "BoardShutDownCorrect";
CM_ SG_ 2600457214 VSM_GSSuggestedState "GS Suggested  value from VSM_Adp:
0 Park
1 Neurtal
2 Drive
3 Reverse
";
CM_ SG_ 2600457214 VSM_Inp_VSMGSState "GS value from VSM_Adp:
0 P
1 N
2 D
3 R
or NA";
CM_ SG_ 2600457214 VSM_Inp_OTAUpdReq "     0     {'SimpleVSM_NoAction'   }
     1     {'SimpleVSM_Maintenance'}
     2     {'SimpleVSM_FullySleep' }
     3     {'SimpleVSM_InvAwake'   }
     4     {'SimpleVSM_Wake'       }";
CM_ SG_ 2600457214 VSM_Int_LowBatteryTimerCond "Result of AND block of Low Battery Timers Conditions";
CM_ BO_ 2399126014 "For DEBUG-TEST only! Consist of signals that can replace AIN siganls from Analog button block #dbc\Components\Comunication_module\Comm\0.0.2.0\Comm.dbc";
CM_ BO_ 2365574398 " #dbc\Vehicles\Van_Beta\Arrival_dcu_Van\0.1.0.0\Arrival_dcu_Van.dbc";
CM_ SG_ 2365574398 SuspensionLevelingRequest_Dbg "Write to memory last choice of SuspensionLevel request from HMI";
CM_ BO_ 2650739198 "Module bootloader version information #\\system_software\components\lib\module_info\0.36.0.0\dbc\module_info.dbc #\\system_software\components\lib\module_info\0.36.0.0\dbc\module_info.dbc";
CM_ SG_ 2650739198 BootloaderVerBuild "Bootloader build number";
CM_ SG_ 2650739198 BootloaderVerFix "Bootloader fix version";
CM_ SG_ 2650739198 BootloaderVerMinor "Bootloader minor version number";
CM_ SG_ 2650739198 BootloaderVerMajor "Bootloader Major version number";
CM_ SG_ 2650739198 BootloaderVerGeneration "Bootloader Generation number";
BA_DEF_ BO_  "Producer" STRING ;
BA_DEF_ BO_  "GenMsgDelayTime" INT 0 1000;
BA_DEF_ BO_  "SendOnChange" ENUM  "No","Yes";
BA_DEF_ BO_  "GenMsgSendType" ENUM  "cyclic","NotUsed","NotUsed","NotUsed","NotUsed","NotUsed","NotUsed","IfActive","noMsgSendType";
BA_DEF_ BO_  "GenMsgCycleTime" INT 0 3600000;
BA_DEF_ BO_  "VFrameFormat" ENUM  "StandardCAN","ExtendedCAN","reserved","J1939PG";
BA_DEF_ SG_  "SPN" INT 0 524287;
BA_DEF_ SG_  "SigType" ENUM  "Default","Range","RangeSigned","ASCII","Discrete","Control","ReferencePGN","DTC","StringDelimiter","StringLength","StringLengthControl","MessageCounter","MessageChecksum";
BA_DEF_ SG_  "GenSigStartValue" INT 0 2147483647;
BA_DEF_ SG_  "GenSigSendType" ENUM  "Cyclic","OnWrite","OnWriteWithRepetition","OnChange","OnChangeWithRepetition","IfActive","IfActiveWithRepetition","NoSigSendType";
BA_DEF_ BO_  "PpCcGenMsgType" STRING ;
BA_DEF_ BO_  "GenMsgRequestable" INT 0 1;
BA_DEF_ BO_  "GenMsgCycleTimeFast" INT 0 3600000;
BA_DEF_  "DBName" STRING ;
BA_DEF_  "BusType" STRING ;
BA_DEF_  "ProtocolType" STRING ;
BA_DEF_  "DatabaseVersion" STRING ;
BA_DEF_  "SAE_J1939_DA_SpecVersion" STRING ;
BA_DEF_  "SAE_J1939_81_SpecVersion" STRING ;
BA_DEF_  "SAE_J1939_75_SpecVersion" STRING ;
BA_DEF_  "SAE_J1939_21_SpecVersion" STRING ;
BA_DEF_  "SAE_J1939_73_SpecVersion" STRING ;
BA_DEF_  "SAE_J1939_71_SpecVersion" STRING ;
BA_DEF_DEF_  "Producer" "";
BA_DEF_DEF_  "GenMsgDelayTime" 0;
BA_DEF_DEF_  "SendOnChange" "No";
BA_DEF_DEF_  "GenMsgSendType" "noMsgSendType";
BA_DEF_DEF_  "GenMsgCycleTime" 0;
BA_DEF_DEF_  "VFrameFormat" "J1939PG";
BA_DEF_DEF_  "SPN" 0;
BA_DEF_DEF_  "SigType" "Default";
BA_DEF_DEF_  "GenSigStartValue" 0;
BA_DEF_DEF_  "GenSigSendType" "NoSigSendType";
BA_DEF_DEF_  "PpCcGenMsgType" "PpCcUndefined";
BA_DEF_DEF_  "GenMsgRequestable" 1;
BA_DEF_DEF_  "GenMsgCycleTimeFast" 0;
BA_DEF_DEF_  "DBName" "0_0_0_12_Body CAN 1";
BA_DEF_DEF_  "BusType" "CAN";
BA_DEF_DEF_  "ProtocolType" "J1939";
BA_DEF_DEF_  "DatabaseVersion" "8.5";
BA_DEF_DEF_  "SAE_J1939_DA_SpecVersion" "2015-01";
BA_DEF_DEF_  "SAE_J1939_81_SpecVersion" "2012-05";
BA_DEF_DEF_  "SAE_J1939_75_SpecVersion" "2012-05";
BA_DEF_DEF_  "SAE_J1939_21_SpecVersion" "2006-10";
BA_DEF_DEF_  "SAE_J1939_73_SpecVersion" "2012-10";
BA_DEF_DEF_  "SAE_J1939_71_SpecVersion" "2012-10";
BA_ "Producer" BO_ 2180532222 "WAWS";
BA_ "GenMsgDelayTime" BO_ 2180532222 100;
BA_ "SendOnChange" BO_ 2180532222 1;
BA_ "GenMsgSendType" BO_ 2180532222 0;
BA_ "GenMsgCycleTime" BO_ 2180532222 1000;
BA_ "GenMsgCycleTime" BO_ 2566845950 1000;
BA_ "GenMsgSendType" BO_ 2566845950 0;
BA_ "SPN" SG_ 2566845950 RoadSurfaceTemp 79;
BA_ "SigType" SG_ 2566845950 RoadSurfaceTemp 1;
BA_ "SPN" SG_ 2566845950 EngAirIntakeTemp 172;
BA_ "SigType" SG_ 2566845950 EngAirIntakeTemp 1;
BA_ "SPN" SG_ 2566845950 AmbientAirTemp 171;
BA_ "SigType" SG_ 2566845950 AmbientAirTemp 1;
BA_ "SPN" SG_ 2566845950 CabInteriorTemp 170;
BA_ "SigType" SG_ 2566845950 CabInteriorTemp 1;
BA_ "SPN" SG_ 2566845950 BarometricPress 108;
BA_ "SigType" SG_ 2566845950 BarometricPress 1;
BA_ "SendOnChange" BO_ 2583065598 1;
BA_ "GenMsgSendType" BO_ 2583065598 0;
BA_ "GenMsgCycleTime" BO_ 2583065598 1000;
BA_ "Producer" BO_ 2583065598 "CLS";
BA_ "GenSigStartValue" SG_ 2583065598 CentralLockFailState 15;
BA_ "GenSigStartValue" SG_ 2583065598 CentralLockCommand 1;
BA_ "GenMsgSendType" BO_ 2515942654 0;
BA_ "GenMsgCycleTime" BO_ 2515942654 1000;
BA_ "GenSigStartValue" SG_ 2515942654 ActualCabinTemperature 8736;
BA_ "Producer" BO_ 2180392702 "CLS";
BA_ "SendOnChange" BO_ 2180392702 1;
BA_ "GenMsgDelayTime" BO_ 2180392702 100;
BA_ "GenMsgSendType" BO_ 2180392702 0;
BA_ "GenMsgCycleTime" BO_ 2180392702 1000;
BA_ "GenSigStartValue" SG_ 2180392702 RollerShutterStatus 7;
BA_ "GenMsgSendType" BO_ 2382107390 0;
BA_ "GenMsgCycleTime" BO_ 2382107390 100;
BA_ "GenSigSendType" SG_ 2382107390 BRKBrakeLightRq_checksum 0;
BA_ "SigType" SG_ 2382107390 BRKBrakeLightRq_checksum 12;
BA_ "SigType" SG_ 2382107390 BRKBrakeLightRq_counter 11;
BA_ "GenSigSendType" SG_ 2382107390 BRKBrakeLightRq_counter 0;
BA_ "Producer" BO_ 2399121662 "LVPS";
BA_ "SendOnChange" BO_ 2399121662 1;
BA_ "GenMsgDelayTime" BO_ 2399121662 100;
BA_ "GenMsgCycleTime" BO_ 2399121662 1000;
BA_ "SigType" SG_ 2399121662 LV_States_cs 12;
BA_ "SigType" SG_ 2399121662 LV_States_rc 11;
BA_ "GenSigStartValue" SG_ 2399121662 LVAllowedLoad 2;
BA_ "GenSigStartValue" SG_ 2399121662 LVReadyToDrive 3;
BA_ "Producer" BO_ 2365435390 "UICS";
BA_ "GenMsgDelayTime" BO_ 2365435390 10;
BA_ "GenMsgSendType" BO_ 2365435390 0;
BA_ "GenMsgCycleTime" BO_ 2365435390 1000;
BA_ "SendOnChange" BO_ 2365435390 1;
BA_ "SigType" SG_ 2365435390 DCU_Stalks_CRC 12;
BA_ "SigType" SG_ 2365435390 DCU_Stalks_Cnt 11;
BA_ "SendOnChange" BO_ 2365473278 1;
BA_ "GenMsgDelayTime" BO_ 2365473278 100;
BA_ "GenMsgSendType" BO_ 2365473278 0;
BA_ "GenMsgCycleTime" BO_ 2365473278 1000;
BA_ "SigType" SG_ 2365473278 ImplementRearWorkLightCmd 5;
BA_ "SPN" SG_ 2365473278 ImplementRearWorkLightCmd 2405;
BA_ "SigType" SG_ 2365473278 ImplLeftFacingWorkLightCmd 5;
BA_ "SPN" SG_ 2365473278 ImplLeftFacingWorkLightCmd 2399;
BA_ "SigType" SG_ 2365473278 ImplRightFwdWorkLightCmd 5;
BA_ "SPN" SG_ 2365473278 ImplRightFwdWorkLightCmd 2401;
BA_ "SigType" SG_ 2365473278 LightingDataRqCmd 5;
BA_ "SPN" SG_ 2365473278 LightingDataRqCmd 2393;
BA_ "SigType" SG_ 2365473278 ImplLeftForwardWorkLightCmd 5;
BA_ "SPN" SG_ 2365473278 ImplLeftForwardWorkLightCmd 2597;
BA_ "SigType" SG_ 2365473278 ImplRightFacingWorkLightCmd 5;
BA_ "SPN" SG_ 2365473278 ImplRightFacingWorkLightCmd 2406;
BA_ "SigType" SG_ 2365473278 ImplOEMOption1LightCmd 5;
BA_ "SPN" SG_ 2365473278 ImplOEMOption1LightCmd 2395;
BA_ "SigType" SG_ 2365473278 ImplOEMOption2LightCmd 5;
BA_ "SPN" SG_ 2365473278 ImplOEMOption2LightCmd 2397;
BA_ "SigType" SG_ 2365473278 TrctrFrntHghMdWkLightsCmd 5;
BA_ "SPN" SG_ 2365473278 TrctrFrntHghMdWkLightsCmd 2355;
BA_ "SigType" SG_ 2365473278 TrctrFrntLowMdWkLightsCmd 5;
BA_ "SPN" SG_ 2365473278 TrctrFrntLowMdWkLightsCmd 2353;
BA_ "SigType" SG_ 2365473278 TrctrSdeHighMdWkLightsCmd 5;
BA_ "SPN" SG_ 2365473278 TrctrSdeHighMdWkLightsCmd 2365;
BA_ "SigType" SG_ 2365473278 TrctrSideLowMdWkLightsCmd 5;
BA_ "SPN" SG_ 2365473278 TrctrSideLowMdWkLightsCmd 2363;
BA_ "SigType" SG_ 2365473278 TrctrRarHighMdWkLightsCmd 5;
BA_ "SPN" SG_ 2365473278 TrctrRarHighMdWkLightsCmd 2361;
BA_ "SigType" SG_ 2365473278 TrctrRearLowMdWkLightsCmd 5;
BA_ "SPN" SG_ 2365473278 TrctrRearLowMdWkLightsCmd 2359;
BA_ "SigType" SG_ 2365473278 TrctrUndrsdeMdWkLightsCmd 5;
BA_ "SPN" SG_ 2365473278 TrctrUndrsdeMdWkLightsCmd 2357;
BA_ "SigType" SG_ 2365473278 RearFogLightsCmd 5;
BA_ "SPN" SG_ 2365473278 RearFogLightsCmd 2389;
BA_ "SigType" SG_ 2365473278 TractorMarkerLightCmd 5;
BA_ "SPN" SG_ 2365473278 TractorMarkerLightCmd 2377;
BA_ "SigType" SG_ 2365473278 ImplementMarkerLightCmd 5;
BA_ "SPN" SG_ 2365473278 ImplementMarkerLightCmd 2379;
BA_ "SigType" SG_ 2365473278 TractorClearanceLightCmd 5;
BA_ "SPN" SG_ 2365473278 TractorClearanceLightCmd 2381;
BA_ "SigType" SG_ 2365473278 ImplementClearanceLightCmd 5;
BA_ "SPN" SG_ 2365473278 ImplementClearanceLightCmd 2383;
BA_ "SigType" SG_ 2365473278 LeftStopLightCmd 5;
BA_ "SPN" SG_ 2365473278 LeftStopLightCmd 2371;
BA_ "SigType" SG_ 2365473278 RightStopLightCmd 5;
BA_ "SPN" SG_ 2365473278 RightStopLightCmd 2373;
BA_ "SigType" SG_ 2365473278 CenterStopLightCmd 5;
BA_ "SPN" SG_ 2365473278 CenterStopLightCmd 2375;
BA_ "SigType" SG_ 2365473278 BackUpLightAndAlarmHornCmd 5;
BA_ "SPN" SG_ 2365473278 BackUpLightAndAlarmHornCmd 2391;
BA_ "SigType" SG_ 2365473278 LeftTurnSignalLightsCmd 5;
BA_ "SPN" SG_ 2365473278 LeftTurnSignalLightsCmd 2367;
BA_ "SigType" SG_ 2365473278 RightTurnSignalLightsCmd 5;
BA_ "SPN" SG_ 2365473278 RightTurnSignalLightsCmd 2369;
BA_ "SigType" SG_ 2365473278 RotatingBeaconLightCmd 5;
BA_ "SPN" SG_ 2365473278 RotatingBeaconLightCmd 2385;
BA_ "SigType" SG_ 2365473278 TractorFrontFogLightsCmd 5;
BA_ "SPN" SG_ 2365473278 TractorFrontFogLightsCmd 2387;
BA_ "SigType" SG_ 2365473278 HighBeamHeadLightCmd 5;
BA_ "SPN" SG_ 2365473278 HighBeamHeadLightCmd 2347;
BA_ "SigType" SG_ 2365473278 LowBeamHeadLightCmd 5;
BA_ "SPN" SG_ 2365473278 LowBeamHeadLightCmd 2349;
BA_ "SigType" SG_ 2365473278 AltBeamHeadLightCmd 5;
BA_ "SPN" SG_ 2365473278 AltBeamHeadLightCmd 2351;
BA_ "SigType" SG_ 2365473278 RunningLightCmd 5;
BA_ "SPN" SG_ 2365473278 RunningLightCmd 2403;
BA_ "SendOnChange" BO_ 2566799614 1;
BA_ "GenMsgDelayTime" BO_ 2566799614 100;
BA_ "GenMsgCycleTime" BO_ 2566799614 100;
BA_ "SigType" SG_ 2566799614 ImplementRearWorkLight 4;
BA_ "SPN" SG_ 2566799614 ImplementRearWorkLight 2394;
BA_ "SigType" SG_ 2566799614 ImplLeftFacingWorkLight 4;
BA_ "SPN" SG_ 2566799614 ImplLeftFacingWorkLight 2400;
BA_ "SigType" SG_ 2566799614 ImplRightForwardWorkLight 4;
BA_ "SPN" SG_ 2566799614 ImplRightForwardWorkLight 2402;
BA_ "SigType" SG_ 2566799614 ImplLeftForwardWorkLight 4;
BA_ "SPN" SG_ 2566799614 ImplLeftForwardWorkLight 2598;
BA_ "SigType" SG_ 2566799614 ImplRightFacingWorkLight 4;
BA_ "SPN" SG_ 2566799614 ImplRightFacingWorkLight 2407;
BA_ "SigType" SG_ 2566799614 ImplementOEMOption1Light 4;
BA_ "SPN" SG_ 2566799614 ImplementOEMOption1Light 2396;
BA_ "SigType" SG_ 2566799614 ImplementOEMOption2Light 4;
BA_ "SPN" SG_ 2566799614 ImplementOEMOption2Light 2398;
BA_ "SigType" SG_ 2566799614 TrctorFrontHighMdWkLights 4;
BA_ "SPN" SG_ 2566799614 TrctorFrontHighMdWkLights 2356;
BA_ "SigType" SG_ 2566799614 TractorFrontLowMdWkLights 4;
BA_ "SPN" SG_ 2566799614 TractorFrontLowMdWkLights 2354;
BA_ "SigType" SG_ 2566799614 TractorSideHighMdWkLights 4;
BA_ "SPN" SG_ 2566799614 TractorSideHighMdWkLights 2366;
BA_ "SigType" SG_ 2566799614 TractorSideLowMdWkLights 4;
BA_ "SPN" SG_ 2566799614 TractorSideLowMdWkLights 2364;
BA_ "SigType" SG_ 2566799614 TractorRearHighMdWkLights 4;
BA_ "SPN" SG_ 2566799614 TractorRearHighMdWkLights 2362;
BA_ "SigType" SG_ 2566799614 TractorRearLowMdWkLights 4;
BA_ "SPN" SG_ 2566799614 TractorRearLowMdWkLights 2360;
BA_ "SigType" SG_ 2566799614 TrctorUndersideMdWkLights 4;
BA_ "SPN" SG_ 2566799614 TrctorUndersideMdWkLights 2358;
BA_ "SigType" SG_ 2566799614 RearFogLights 4;
BA_ "SPN" SG_ 2566799614 RearFogLights 2390;
BA_ "SigType" SG_ 2566799614 TractorMarkerLight 4;
BA_ "SPN" SG_ 2566799614 TractorMarkerLight 2378;
BA_ "SigType" SG_ 2566799614 ImplementMarkerLight 4;
BA_ "SPN" SG_ 2566799614 ImplementMarkerLight 2380;
BA_ "SigType" SG_ 2566799614 TractorClearanceLight 4;
BA_ "SPN" SG_ 2566799614 TractorClearanceLight 2382;
BA_ "SigType" SG_ 2566799614 ImplementClearanceLight 4;
BA_ "SPN" SG_ 2566799614 ImplementClearanceLight 2384;
BA_ "SigType" SG_ 2566799614 LeftStopLight 4;
BA_ "SPN" SG_ 2566799614 LeftStopLight 2372;
BA_ "SigType" SG_ 2566799614 RightStopLight 4;
BA_ "SPN" SG_ 2566799614 RightStopLight 2374;
BA_ "SigType" SG_ 2566799614 CenterStopLight 4;
BA_ "SPN" SG_ 2566799614 CenterStopLight 2376;
BA_ "SigType" SG_ 2566799614 BackUpLightAndAlarmHorn 4;
BA_ "SPN" SG_ 2566799614 BackUpLightAndAlarmHorn 2392;
BA_ "SigType" SG_ 2566799614 LeftTurnSignalLights 4;
BA_ "SPN" SG_ 2566799614 LeftTurnSignalLights 2368;
BA_ "SigType" SG_ 2566799614 RightTurnSignalLights 4;
BA_ "SPN" SG_ 2566799614 RightTurnSignalLights 2370;
BA_ "SigType" SG_ 2566799614 RotatingBeaconLight 4;
BA_ "SPN" SG_ 2566799614 RotatingBeaconLight 2386;
BA_ "SigType" SG_ 2566799614 TractorFrontFogLights 4;
BA_ "SPN" SG_ 2566799614 TractorFrontFogLights 2388;
BA_ "SigType" SG_ 2566799614 HighBeamHeadLight 4;
BA_ "SPN" SG_ 2566799614 HighBeamHeadLight 2348;
BA_ "SigType" SG_ 2566799614 LowBeamHeadLight 4;
BA_ "SPN" SG_ 2566799614 LowBeamHeadLight 2350;
BA_ "SigType" SG_ 2566799614 AltBeamHeadLight 4;
BA_ "SPN" SG_ 2566799614 AltBeamHeadLight 2352;
BA_ "SigType" SG_ 2566799614 RunningLight 4;
BA_ "SPN" SG_ 2566799614 RunningLight 2404;
BA_ "GenMsgSendType" BO_ 2565868030 0;
BA_ "GenMsgCycleTime" BO_ 2565868030 10;
BA_ "SigType" SG_ 2565868030 LongitudinalAcceleration 1;
BA_ "SPN" SG_ 2565868030 LongitudinalAcceleration 1810;
BA_ "SigType" SG_ 2565868030 LateralAcceleration 1;
BA_ "SPN" SG_ 2565868030 LateralAcceleration 1809;
BA_ "SigType" SG_ 2565868030 YawRate 1;
BA_ "SPN" SG_ 2565868030 YawRate 1808;
BA_ "SigType" SG_ 2565868030 SteerWheelAngleSensorType 5;
BA_ "SPN" SG_ 2565868030 SteerWheelAngleSensorType 1812;
BA_ "GenSigStartValue" SG_ 2565868030 SteerWheelTurnCounter 22;
BA_ "SPN" SG_ 2565868030 SteerWheelTurnCounter 1811;
BA_ "SigType" SG_ 2565868030 SteerWheelAngle 1;
BA_ "SPN" SG_ 2565868030 SteerWheelAngle 1807;
BA_ "SendOnChange" BO_ 2365583358 1;
BA_ "GenMsgCycleTime" BO_ 2365583358 1000;
BA_ "GenMsgSendType" BO_ 2365583358 0;
BA_ "GenMsgDelayTime" BO_ 2365583358 100;
BA_ "Producer" BO_ 2365583358 "UICS";
BA_ "SigType" SG_ 2365583358 HazardState_CRC 12;
BA_ "SPN" SG_ 2365583358 HazardLightSwitch 2875;
BA_ "SigType" SG_ 2365583358 HazardLightSwitch 4;
BA_ "SigType" SG_ 2365583358 HazardState_Cnt 11;
BA_ "GenMsgSendType" BO_ 2566767870 0;
BA_ "GenMsgCycleTime" BO_ 2566767870 100;
BA_ "SigType" SG_ 2566767870 EmergencyBrakingActive 5;
BA_ "SPN" SG_ 2566767870 EmergencyBrakingActive 5847;
BA_ "SigType" SG_ 2566767870 PrkngBrakeActuatorFullyActivated 4;
BA_ "SPN" SG_ 2566767870 PrkngBrakeActuatorFullyActivated 5275;
BA_ "SigType" SG_ 2566767870 XBRAccelerationLimit 1;
BA_ "GenSigStartValue" SG_ 2566767870 XBRAccelerationLimit 25;
BA_ "SPN" SG_ 2566767870 XBRAccelerationLimit 2921;
BA_ "SPN" SG_ 2566767870 XBRActiveCtrlMode 2918;
BA_ "SigType" SG_ 2566767870 XBRSystemState 5;
BA_ "SPN" SG_ 2566767870 XBRSystemState 2917;
BA_ "SigType" SG_ 2566767870 FoundationBrakeUse 5;
BA_ "SPN" SG_ 2566767870 FoundationBrakeUse 2919;
BA_ "SPN" SG_ 2566767870 HillHolderMode 2912;
BA_ "SPN" SG_ 2566767870 HaltBrakeMode 2913;
BA_ "SigType" SG_ 2566767870 BrakeTempWarning 5;
BA_ "SPN" SG_ 2566767870 BrakeTempWarning 3839;
BA_ "GenMsgSendType" BO_ 2365484286 0;
BA_ "GenMsgCycleTime" BO_ 2365484286 50;
BA_ "SigType" SG_ 2365484286 TachographVehicleSpeed 1;
BA_ "SPN" SG_ 2365484286 TachographVehicleSpeed 1624;
BA_ "SigType" SG_ 2365484286 TachographOutputShaftSpeed 1;
BA_ "SPN" SG_ 2365484286 TachographOutputShaftSpeed 1623;
BA_ "SigType" SG_ 2365484286 DirectionIndicator 4;
BA_ "SPN" SG_ 2365484286 DirectionIndicator 1619;
BA_ "SigType" SG_ 2365484286 TachographPerformance 5;
BA_ "SPN" SG_ 2365484286 TachographPerformance 1620;
BA_ "SigType" SG_ 2365484286 HandlingInformation 5;
BA_ "SPN" SG_ 2365484286 HandlingInformation 1621;
BA_ "SigType" SG_ 2365484286 SystemEvent 5;
BA_ "SPN" SG_ 2365484286 SystemEvent 1622;
BA_ "SigType" SG_ 2365484286 DriverCardDriver2 4;
BA_ "SPN" SG_ 2365484286 DriverCardDriver2 1616;
BA_ "SPN" SG_ 2365484286 Driver2TimeRelatedStates 1618;
BA_ "SigType" SG_ 2365484286 VehicleOverspeed 4;
BA_ "SPN" SG_ 2365484286 VehicleOverspeed 1614;
BA_ "SigType" SG_ 2365484286 DriverCardDriver1 4;
BA_ "SPN" SG_ 2365484286 DriverCardDriver1 1615;
BA_ "SPN" SG_ 2365484286 Driver1TimeRelatedStates 1617;
BA_ "SigType" SG_ 2365484286 VehicleMotion 4;
BA_ "SPN" SG_ 2365484286 VehicleMotion 1611;
BA_ "SPN" SG_ 2365484286 Driver2WorkingState 1613;
BA_ "SPN" SG_ 2365484286 Driver1WorkingState 1612;
BA_ "GenMsgSendType" BO_ 2180924414 0;
BA_ "GenMsgCycleTime" BO_ 2180924414 1000;
BA_ "GenMsgDelayTime" BO_ 2180924414 50;
BA_ "SendOnChange" BO_ 2180924414 1;
BA_ "GenMsgCycleTime" BO_ 2382314494 40;
BA_ "GenMsgSendType" BO_ 2382314494 0;
BA_ "SigType" SG_ 2382314494 GS_CRC 12;
BA_ "SigType" SG_ 2382314494 GS_MC 11;
BA_ "GenSigStartValue" SG_ 2382314494 GS_Demand 3;
BA_ "GenMsgSendType" BO_ 2180926462 0;
BA_ "GenMsgCycleTime" BO_ 2180926462 100;
BA_ "SigType" SG_ 2180926462 ACDCPortCmd_Counter 11;
BA_ "SigType" SG_ 2180926462 ACDCPortCmd_CRC 12;
BA_ "GenMsgSendType" BO_ 2399117310 0;
BA_ "GenMsgCycleTime" BO_ 2399117310 100;
BA_ "SigType" SG_ 2399117310 VSM_CRC 12;
BA_ "SigType" SG_ 2399117310 VSM_Cnt 11;
BA_ "GenSigStartValue" SG_ 2399117310 VSM_State 7;
BA_ "GenMsgDelayTime" BO_ 2566883070 100;
BA_ "SendOnChange" BO_ 2566883070 1;
BA_ "GenMsgCycleTime" BO_ 2566883070 1000;
BA_ "GenMsgSendType" BO_ 2566883070 0;
BA_ "Producer" BO_ 2566883070 "CLS";
BA_ "GenMsgSendType" BO_ 2382241534 0;
BA_ "GenMsgCycleTime" BO_ 2382241534 500;
BA_ "GenSigStartValue" SG_ 2382241534 BatteryOvercoolEvent 3;
BA_ "GenSigStartValue" SG_ 2382241534 CoolantTank_2_LevelSt 3;
BA_ "GenSigStartValue" SG_ 2382241534 CoolantTank_1_LevelSt 3;
BA_ "GenSigStartValue" SG_ 2382241534 OverheatEvent_Overall 3;
BA_ "GenSigStartValue" SG_ 2382241534 MalfunctionEvent_Overall 3;
BA_ "GenSigStartValue" SG_ 2382241534 OverheatEvent 15;
BA_ "GenSigStartValue" SG_ 2382241534 ThermalSystemFault 15;
BA_ "GenMsgSendType" BO_ 2297441790 0;
BA_ "GenMsgCycleTime" BO_ 2297441790 10;
BA_ "SigType" SG_ 2297441790 SpprtVrblTrnsRpttnRtFrAcclrtnSns 5;
BA_ "SPN" SG_ 2297441790 SpprtVrblTrnsRpttnRtFrAcclrtnSns 5353;
BA_ "SigType" SG_ 2297441790 VrtclAcclrtnExRangeFigureOfMerit 5;
BA_ "SPN" SG_ 2297441790 VrtclAcclrtnExRangeFigureOfMerit 5352;
BA_ "SigType" SG_ 2297441790 LngtdnlAcclrtnExRngFigureOfMerit 5;
BA_ "SPN" SG_ 2297441790 LngtdnlAcclrtnExRngFigureOfMerit 5351;
BA_ "SigType" SG_ 2297441790 LtrlAcclrtonExRangeFigureOfMerit 5;
BA_ "SPN" SG_ 2297441790 LtrlAcclrtonExRangeFigureOfMerit 5350;
BA_ "SigType" SG_ 2297441790 VerticalAccelerationExRange 1;
BA_ "SPN" SG_ 2297441790 VerticalAccelerationExRange 5349;
BA_ "SigType" SG_ 2297441790 LongitudinalAccelerationExRange 1;
BA_ "SPN" SG_ 2297441790 LongitudinalAccelerationExRange 5348;
BA_ "SigType" SG_ 2297441790 LateralAccelerationExRange 1;
BA_ "SPN" SG_ 2297441790 LateralAccelerationExRange 5347;
BA_ "Producer" BO_ 2583173886 "WAWS";
BA_ "GenMsgDelayTime" BO_ 2583173886 100;
BA_ "GenMsgSendType" BO_ 2583173886 0;
BA_ "SendOnChange" BO_ 2583173886 1;
BA_ "GenMsgCycleTime" BO_ 2583173886 1000;
BA_ "GenMsgSendType" BO_ 2516075518 0;
BA_ "GenMsgCycleTime" BO_ 2516075518 100;
BA_ "SigType" SG_ 2516075518 RideHeight_Value 4;
BA_ "GenMsgCycleTime" BO_ 2566882814 100;
BA_ "GenMsgSendType" BO_ 2566882814 0;
BA_ "SendOnChange" BO_ 2566882814 1;
BA_ "GenSigStartValue" SG_ 2566882814 KeyRange 7;
BA_ "GenSigStartValue" SG_ 2566882814 KeyCommand 7;
BA_ "SendOnChange" BO_ 2583062526 1;
BA_ "GenMsgCycleTime" BO_ 2583062526 1000;
BA_ "GenMsgSendType" BO_ 2583062526 0;
BA_ "GenSigStartValue" SG_ 2583062526 CentralLockRequest 7;
BA_ "GenMsgCycleTime" BO_ 2399123966 100;
BA_ "GenMsgSendType" BO_ 2399123966 0;
BA_ "SigType" SG_ 2399123966 VehSec_CRC 12;
BA_ "SigType" SG_ 2399123966 VehSec_CNT 11;
BA_ "SPN" SG_ 2399123966 KeyfobBatteryState 520006;
BA_ "SPN" SG_ 2399123966 SecurityWakeUpRequest 520005;
BA_ "GenSigStartValue" SG_ 2399123966 SecurityWakeUpRequest 3;
BA_ "SPN" SG_ 2399123966 SecurityReadyToSleep 520004;
BA_ "GenSigStartValue" SG_ 2399123966 SecurityReadyToSleep 3;
BA_ "SPN" SG_ 2399123966 VehicleLockState 520003;
BA_ "SPN" SG_ 2399123966 DriveSecurityState 520002;
BA_ "SendOnChange" BO_ 2583065854 1;
BA_ "GenMsgSendType" BO_ 2583065854 0;
BA_ "GenMsgCycleTime" BO_ 2583065854 1000;
BA_ "SendOnChange" BO_ 2163223550 1;
BA_ "GenMsgSendType" BO_ 2163223550 0;
BA_ "GenMsgCycleTime" BO_ 2163223550 100;
BA_ "SigType" SG_ 2163223550 CrashChecksum 12;
BA_ "SPN" SG_ 2163223550 CrashChecksum 4975;
BA_ "SigType" SG_ 2163223550 CrashCounter 11;
BA_ "SPN" SG_ 2163223550 CrashCounter 4974;
BA_ "SPN" SG_ 2163223550 CrashType 4973;
BA_ "GenMsgSendType" BO_ 2448507902 0;
BA_ "GenMsgCycleTime" BO_ 2448507902 100;
BA_ "GenMsgSendType" BO_ 2448508158 0;
BA_ "GenMsgCycleTime" BO_ 2448508158 100;
BA_ "GenSigStartValue" SG_ 2448508158 AngleY_out 30;
BA_ "GenSigStartValue" SG_ 2448508158 AngleX_out 30;
BA_ "GenMsgSendType" BO_ 2583180030 0;
BA_ "GenMsgCycleTime" BO_ 2583180030 1000;
BA_ "GenSigStartValue" SG_ 2583180030 RearHeatedWindscreenFaultSt 3;
BA_ "GenSigStartValue" SG_ 2583180030 FrontHeatedWindscreenFaultSt 3;
BA_ "GenSigStartValue" SG_ 2583180030 WindowHeatedGlassSt 3;
BA_ "GenSigStartValue" SG_ 2583180030 FrontDoorHeatedGlassSt 3;
BA_ "GenSigStartValue" SG_ 2583180030 RearHeatedWindscreenSt 3;
BA_ "GenSigStartValue" SG_ 2583180030 FrontHeatedWindscreenSt 3;
BA_ "Producer" BO_ 2583179774 "HMI";
BA_ "GenMsgSendType" BO_ 2583179774 0;
BA_ "GenMsgCycleTime" BO_ 2583179774 1000;
BA_ "GenMsgDelayTime" BO_ 2499547902 100;
BA_ "GenMsgSendType" BO_ 2499547902 0;
BA_ "GenMsgCycleTime" BO_ 2499547902 1000;
BA_ "SendOnChange" BO_ 2499547902 1;
BA_ "SigType" SG_ 2499547902 MirrorRight2HeatCmd 5;
BA_ "SPN" SG_ 2499547902 MirrorRight2HeatCmd 7744;
BA_ "SigType" SG_ 2499547902 MirrorLeft2HeatCmd 5;
BA_ "SPN" SG_ 2499547902 MirrorLeft2HeatCmd 7743;
BA_ "SigType" SG_ 2499547902 MirrorRight1HeatCmd 5;
BA_ "SPN" SG_ 2499547902 MirrorRight1HeatCmd 7742;
BA_ "SigType" SG_ 2499547902 MirrorLeft1HeatCmd 5;
BA_ "SPN" SG_ 2499547902 MirrorLeft1HeatCmd 7741;
BA_ "SigType" SG_ 2499547902 MirrorRight2VerticalCmd 5;
BA_ "SPN" SG_ 2499547902 MirrorRight2VerticalCmd 7740;
BA_ "SigType" SG_ 2499547902 MirrorRight2HorizontalCmd 5;
BA_ "SPN" SG_ 2499547902 MirrorRight2HorizontalCmd 7739;
BA_ "SigType" SG_ 2499547902 MirrorLeft2VerticalCmd 5;
BA_ "SPN" SG_ 2499547902 MirrorLeft2VerticalCmd 7738;
BA_ "SigType" SG_ 2499547902 MirrorLeft2HorizontalCmd 5;
BA_ "SPN" SG_ 2499547902 MirrorLeft2HorizontalCmd 7737;
BA_ "SigType" SG_ 2499547902 MirrorRight1VerticalCmd 5;
BA_ "SPN" SG_ 2499547902 MirrorRight1VerticalCmd 7736;
BA_ "SigType" SG_ 2499547902 MirrorRight1HorizontalCmd 5;
BA_ "SPN" SG_ 2499547902 MirrorRight1HorizontalCmd 7735;
BA_ "SigType" SG_ 2499547902 MirrorLeft1VerticalCmd 5;
BA_ "SPN" SG_ 2499547902 MirrorLeft1VerticalCmd 7734;
BA_ "SigType" SG_ 2499547902 MirrorLeft1HorizontalCmd 5;
BA_ "SPN" SG_ 2499547902 MirrorLeft1HorizontalCmd 7733;
BA_ "SPN" SG_ 2499547902 RightRearWindowPosCmd 7732;
BA_ "SPN" SG_ 2499547902 LeftRearWindowPosCmd 7731;
BA_ "SPN" SG_ 2499547902 RightFrontWindowPosCmd 7730;
BA_ "SPN" SG_ 2499547902 LeftFrontWindowPosCmd 7729;
BA_ "SPN" SG_ 2499547902 RemoteCabDoorLockReq 7728;
BA_ "SPN" SG_ 2499547902 DoorsLockActCmd 7727;
BA_ "Producer" BO_ 2583177470 "WAWS";
BA_ "GenMsgDelayTime" BO_ 2583177470 100;
BA_ "GenMsgCycleTime" BO_ 2583177470 1000;
BA_ "GenMsgSendType" BO_ 2583177470 0;
BA_ "SendOnChange" BO_ 2583177470 1;
BA_ "SendOnChange" BO_ 2364552702 1;
BA_ "GenMsgSendType" BO_ 2364552702 0;
BA_ "GenMsgCycleTime" BO_ 2364552702 1000;
BA_ "GenMsgDelayTime" BO_ 2364552702 100;
BA_ "Producer" BO_ 2364552702 "SECSYS";
BA_ "GenMsgDelayTime" BO_ 2582766846 100;
BA_ "SendOnChange" BO_ 2582766846 1;
BA_ "GenMsgCycleTime" BO_ 2582766846 1000;
BA_ "GenMsgSendType" BO_ 2582766846 0;
BA_ "Producer" BO_ 2582766846 "SECSYS";
BA_ "GenSigStartValue" SG_ 2582766846 ACU_Active 3;
BA_ "GenSigStartValue" SG_ 2582766846 ACU_Alarm 3;
BA_ "GenSigStartValue" SG_ 2582766846 USS_Status 3;
BA_ "GenSigStartValue" SG_ 2582766846 ACU_Status 3;
BA_ "GenSigStartValue" SG_ 2582766846 Intrusion_detected 3;
BA_ "GenMsgSendType" BO_ 2565865982 0;
BA_ "GenMsgCycleTime" BO_ 2565865982 100;
BA_ "SigType" SG_ 2565865982 TrctrMntdTrailerABSWarningSignal 5;
BA_ "SPN" SG_ 2565865982 TrctrMntdTrailerABSWarningSignal 1792;
BA_ "SigType" SG_ 2565865982 TrailerABSStatus 5;
BA_ "SPN" SG_ 2565865982 TrailerABSStatus 1836;
BA_ "SigType" SG_ 2565865982 HaltBrakeSwitch 4;
BA_ "SPN" SG_ 2565865982 HaltBrakeSwitch 2911;
BA_ "SPN" SG_ 2565865982 SrcAddrssOfCntrllngDvcFrBrkeCtrl 1481;
BA_ "SigType" SG_ 2565865982 ATC_ASRInformationSignal 5;
BA_ "SPN" SG_ 2565865982 ATC_ASRInformationSignal 1793;
BA_ "SigType" SG_ 2565865982 ABS_EBSAmberWarningSignal 5;
BA_ "SPN" SG_ 2565865982 ABS_EBSAmberWarningSignal 1438;
BA_ "SigType" SG_ 2565865982 EBSRedWarningSignal 5;
BA_ "SPN" SG_ 2565865982 EBSRedWarningSignal 1439;
BA_ "SigType" SG_ 2565865982 ABSFullyOperational 5;
BA_ "SPN" SG_ 2565865982 ABSFullyOperational 1243;
BA_ "SigType" SG_ 2565865982 EngRetarderSelection 1;
BA_ "SPN" SG_ 2565865982 EngRetarderSelection 973;
BA_ "SigType" SG_ 2565865982 RemoteAccelEnableSwitch 4;
BA_ "SPN" SG_ 2565865982 RemoteAccelEnableSwitch 969;
BA_ "SigType" SG_ 2565865982 EngAuxShutdownSwitch 4;
BA_ "SPN" SG_ 2565865982 EngAuxShutdownSwitch 970;
BA_ "SigType" SG_ 2565865982 EngDerateSwitch 4;
BA_ "SPN" SG_ 2565865982 EngDerateSwitch 971;
BA_ "SigType" SG_ 2565865982 AccelInterlockSwitch 4;
BA_ "SPN" SG_ 2565865982 AccelInterlockSwitch 972;
BA_ "SigType" SG_ 2565865982 TractionCtrlOverrideSwitch 4;
BA_ "SPN" SG_ 2565865982 TractionCtrlOverrideSwitch 1238;
BA_ "SigType" SG_ 2565865982 ASRHillHolderSwitch 4;
BA_ "SPN" SG_ 2565865982 ASRHillHolderSwitch 577;
BA_ "SigType" SG_ 2565865982 ASROffroadSwitch 4;
BA_ "SPN" SG_ 2565865982 ASROffroadSwitch 576;
BA_ "SigType" SG_ 2565865982 ABSOffroadSwitch 4;
BA_ "SPN" SG_ 2565865982 ABSOffroadSwitch 575;
BA_ "SigType" SG_ 2565865982 BrakePedalPos 1;
BA_ "SPN" SG_ 2565865982 BrakePedalPos 521;
BA_ "SigType" SG_ 2565865982 EBSBrakeSwitch 4;
BA_ "SPN" SG_ 2565865982 EBSBrakeSwitch 1121;
BA_ "SigType" SG_ 2565865982 AntiLockBrakingActive 5;
BA_ "SPN" SG_ 2565865982 AntiLockBrakingActive 563;
BA_ "SigType" SG_ 2565865982 ASRBrakeCtrlActive 5;
BA_ "SPN" SG_ 2565865982 ASRBrakeCtrlActive 562;
BA_ "SigType" SG_ 2565865982 ASREngCtrlActive 5;
BA_ "SPN" SG_ 2565865982 ASREngCtrlActive 561;
BA_ "Producer" BO_ 2583173374 "WAWS";
BA_ "GenMsgDelayTime" BO_ 2583173374 100;
BA_ "GenMsgSendType" BO_ 2583173374 0;
BA_ "SendOnChange" BO_ 2583173374 1;
BA_ "GenMsgCycleTime" BO_ 2583173374 1000;
BA_ "PpCcGenMsgType" BO_ 2381731326 "PpCcOutput";
BA_ "GenMsgSendType" BO_ 2381731326 0;
BA_ "SendOnChange" BO_ 2381731326 1;
BA_ "GenMsgCycleTime" BO_ 2381731326 1000;
BA_ "Producer" BO_ 2381731326 "UICS";
BA_ "Producer" BO_ 2583062270 "CLS";
BA_ "GenMsgDelayTime" BO_ 2583062270 100;
BA_ "SendOnChange" BO_ 2583062270 1;
BA_ "GenMsgSendType" BO_ 2583062270 0;
BA_ "GenMsgCycleTime" BO_ 2583062270 1000;
BA_ "SigType" SG_ 2583062270 DcdlsChecksum 12;
BA_ "SigType" SG_ 2583062270 DcdlsCounter 11;
BA_ "GenMsgSendType" BO_ 2516060670 0;
BA_ "GenMsgCycleTime" BO_ 2516060670 300;
BA_ "GenSigStartValue" SG_ 2516060670 paEnableReq 3;
BA_ "GenSigStartValue" SG_ 2516060670 paAutoReq 3;
BA_ "GenMsgCycleTime" BO_ 2516060414 300;
BA_ "GenMsgSendType" BO_ 2516060414 0;
BA_ "GenSigStartValue" SG_ 2516060414 paStatus 3;
BA_ "GenMsgCycleTime" BO_ 2516059134 300;
BA_ "GenMsgSendType" BO_ 2516059134 0;
BA_ "GenMsgCycleTime" BO_ 2516059390 300;
BA_ "GenMsgSendType" BO_ 2516059390 0;
BA_ "GenMsgCycleTime" BO_ 2516059646 300;
BA_ "GenMsgSendType" BO_ 2516059646 0;
BA_ "GenMsgCycleTime" BO_ 2381723902 250;
BA_ "GenMsgSendType" BO_ 2381723902 0;
BA_ "GenSigStartValue" SG_ 2381723902 RecircModeState 7;
BA_ "GenSigStartValue" SG_ 2381723902 OutletSelectionState 15;
BA_ "GenSigStartValue" SG_ 2381723902 AirOutTemperature 500;
BA_ "GenSigStartValue" SG_ 2381723902 AirInTemperature 500;
BA_ "GenSigStartValue" SG_ 2381723902 ColdCoilTemperature 500;
BA_ "SendOnChange" BO_ 2583063294 1;
BA_ "GenMsgDelayTime" BO_ 2583063294 100;
BA_ "GenMsgSendType" BO_ 2583063294 0;
BA_ "GenMsgCycleTime" BO_ 2583063294 1000;
BA_ "Producer" BO_ 2583063294 "CLS";
BA_ "GenSigStartValue" SG_ 2583063294 WindowPosCmd 7;
BA_ "Producer" BO_ 2515942398 "HMI";
BA_ "GenMsgSendType" BO_ 2515942398 0;
BA_ "GenMsgCycleTime" BO_ 2515942398 500;
BA_ "GenSigStartValue" SG_ 2515942398 CabinTemperatureRequest 84;
BA_ "GenSigStartValue" SG_ 2515942398 TurboEnableRequest 3;
BA_ "GenSigStartValue" SG_ 2515942398 PetModeRequest 3;
BA_ "GenSigStartValue" SG_ 2515942398 MaxACRequest 3;
BA_ "GenSigStartValue" SG_ 2515942398 ACEnableRequest 3;
BA_ "GenSigStartValue" SG_ 2515942398 AutoEnableRequest 3;
BA_ "GenSigStartValue" SG_ 2515942398 CabinRecirculationRequest 7;
BA_ "GenSigStartValue" SG_ 2515942398 OutletSelectionRequest 15;
BA_ "GenSigStartValue" SG_ 2515942398 CabinAirflowSpeedRequest 15;
BA_ "GenSigStartValue" SG_ 2515942398 DemistRequest 3;
BA_ "GenSigStartValue" SG_ 2515942398 ClimateControlEnable 3;
BA_ "GenMsgCycleTime" BO_ 2515949566 500;
BA_ "GenMsgSendType" BO_ 2515949566 0;
BA_ "GenSigStartValue" SG_ 2515949566 ClimateSystemEffortDisp 100;
BA_ "GenSigStartValue" SG_ 2515949566 TurboEnableState 3;
BA_ "GenSigStartValue" SG_ 2515949566 PetModeState 3;
BA_ "GenSigStartValue" SG_ 2515949566 MaxACState 3;
BA_ "GenSigStartValue" SG_ 2515949566 ACEnableState 3;
BA_ "GenSigStartValue" SG_ 2515949566 AutoEnableState 3;
BA_ "GenSigStartValue" SG_ 2515949566 RecirculationRequestState 7;
BA_ "GenSigStartValue" SG_ 2515949566 OutletSelectionState 15;
BA_ "GenSigStartValue" SG_ 2515949566 BlowerSpeedRequestState 15;
BA_ "GenSigStartValue" SG_ 2515949566 DemistRequestState 3;
BA_ "GenSigStartValue" SG_ 2515949566 ClimateControlEnableState 3;
BA_ "GenMsgSendType" BO_ 2515942142 0;
BA_ "GenMsgCycleTime" BO_ 2515942142 250;
BA_ "GenSigStartValue" SG_ 2515942142 HVACOutTempTarg 50;
BA_ "GenMsgSendType" BO_ 2515942910 0;
BA_ "GenMsgCycleTime" BO_ 2515942910 100;
BA_ "Producer" BO_ 2583175678 "SFT";
BA_ "GenMsgCycleTime" BO_ 2583175678 1000;
BA_ "GenMsgSendType" BO_ 2583175678 0;
BA_ "GenMsgDelayTime" BO_ 2583175678 100;
BA_ "SendOnChange" BO_ 2583175678 1;
BA_ "GenSigStartValue" SG_ 2583175678 PassLatchStateInfo 3;
BA_ "GenSigStartValue" SG_ 2583175678 DriverLatchStateInfo 3;
BA_ "GenSigStartValue" SG_ 2583175678 CenterLatchStateInfo 3;
BA_ "Producer" BO_ 2583175934 "SFT";
BA_ "GenMsgCycleTime" BO_ 2583175934 1000;
BA_ "GenMsgSendType" BO_ 2583175934 0;
BA_ "GenMsgDelayTime" BO_ 2583175934 100;
BA_ "SendOnChange" BO_ 2583175934 1;
BA_ "GenSigStartValue" SG_ 2583175934 PassSeatStateInfo 3;
BA_ "GenSigStartValue" SG_ 2583175934 DriverSeatStateInfo 3;
BA_ "GenSigStartValue" SG_ 2583175934 CenterSeatStateInfo 3;
BA_ "GenMsgDelayTime" BO_ 2381851134 100;
BA_ "SendOnChange" BO_ 2381851134 1;
BA_ "GenMsgCycleTime" BO_ 2381851134 1000;
BA_ "Producer" BO_ 2381851134 "UICS";
BA_ "Producer" BO_ 2583175422 "SFT";
BA_ "GenMsgSendType" BO_ 2583175422 0;
BA_ "GenMsgCycleTime" BO_ 2583175422 1000;
BA_ "GenMsgDelayTime" BO_ 2583175422 100;
BA_ "SendOnChange" BO_ 2583175422 1;
BA_ "GenSigStartValue" SG_ 2583175422 PassLatchState 3;
BA_ "GenSigStartValue" SG_ 2583175422 DriverLatchState 3;
BA_ "GenMsgDelayTime" BO_ 2583191550 100;
BA_ "GenMsgCycleTime" BO_ 2583191550 100;
BA_ "GenMsgSendType" BO_ 2583191550 0;
BA_ "Producer" BO_ 2583191550 "ELS";
BA_ "SigType" SG_ 2583191550 BrkLampSts_cs 12;
BA_ "SigType" SG_ 2583191550 BrkLampSts_rc 11;
BA_ "GenMsgSendType" BO_ 2398294526 0;
BA_ "GenMsgCycleTime" BO_ 2398294526 100;
BA_ "SigType" SG_ 2398294526 SteerHmiReqCks 12;
BA_ "SigType" SG_ 2398294526 SteerHmiReqCnt 11;
BA_ "GenSigStartValue" SG_ 2398294526 SteerRedTelltaleReq 3;
BA_ "GenSigStartValue" SG_ 2398294526 SteerYellowTelltaleReq 3;
BA_ "GenMsgSendType" BO_ 2381861118 0;
BA_ "GenMsgCycleTime" BO_ 2381861118 100;
BA_ "GenSigStartValue" SG_ 2381861118 STRReadyToDrive 3;
BA_ "GenMsgSendType" BO_ 2566845694 0;
BA_ "GenMsgCycleTime" BO_ 2566845694 500;
BA_ "SPN" SG_ 2566845694 TirePressThresholdDetection_00 521600;
BA_ "SPN" SG_ 2566845694 TirePressThresholdDetection_20 521620;
BA_ "SPN" SG_ 2566845694 TirePressThresholdDetection_21 521621;
BA_ "SPN" SG_ 2566845694 TirePressThresholdDetection_22 521622;
BA_ "SPN" SG_ 2566845694 TirePressThresholdDetection_23 521623;
BA_ "SPN" SG_ 2566845694 TirePressThresholdDetection_30 521630;
BA_ "SPN" SG_ 2566845694 TirePressThresholdDetection_31 521631;
BA_ "SPN" SG_ 2566845694 TirePressThresholdDetection_32 521632;
BA_ "SPN" SG_ 2566845694 TirePressThresholdDetection_33 521633;
BA_ "SPN" SG_ 2566845694 TirePressThresholdDetection_01 521601;
BA_ "SPN" SG_ 2566845694 TirePressThresholdDetection_10 521610;
BA_ "SPN" SG_ 2566845694 TirePressThresholdDetection_11 521611;
BA_ "SPN" SG_ 2566845694 TirePressThresholdDetection_12 521612;
BA_ "SPN" SG_ 2566845694 TirePressThresholdDetection_13 521613;
BA_ "SigType" SG_ 2566845694 TireAirLeakageRate_00 1;
BA_ "SPN" SG_ 2566845694 TireAirLeakageRate_00 521500;
BA_ "SigType" SG_ 2566845694 TireAirLeakageRate_01 1;
BA_ "SPN" SG_ 2566845694 TireAirLeakageRate_01 521501;
BA_ "SigType" SG_ 2566845694 TireAirLeakageRate_10 1;
BA_ "SPN" SG_ 2566845694 TireAirLeakageRate_10 521510;
BA_ "SigType" SG_ 2566845694 TireAirLeakageRate_11 1;
BA_ "SPN" SG_ 2566845694 TireAirLeakageRate_11 521511;
BA_ "SigType" SG_ 2566845694 TireAirLeakageRate_12 1;
BA_ "SPN" SG_ 2566845694 TireAirLeakageRate_12 521512;
BA_ "SigType" SG_ 2566845694 TireAirLeakageRate_13 1;
BA_ "SPN" SG_ 2566845694 TireAirLeakageRate_13 521513;
BA_ "SigType" SG_ 2566845694 TireAirLeakageRate_20 1;
BA_ "SPN" SG_ 2566845694 TireAirLeakageRate_20 521520;
BA_ "SigType" SG_ 2566845694 TireAirLeakageRate_21 1;
BA_ "SPN" SG_ 2566845694 TireAirLeakageRate_21 521521;
BA_ "SigType" SG_ 2566845694 TireAirLeakageRate_22 1;
BA_ "SPN" SG_ 2566845694 TireAirLeakageRate_22 521522;
BA_ "SigType" SG_ 2566845694 TireAirLeakageRate_23 1;
BA_ "SPN" SG_ 2566845694 TireAirLeakageRate_23 521523;
BA_ "SigType" SG_ 2566845694 TireAirLeakageRate_30 1;
BA_ "SPN" SG_ 2566845694 TireAirLeakageRate_30 521530;
BA_ "SigType" SG_ 2566845694 TireAirLeakageRate_31 1;
BA_ "SPN" SG_ 2566845694 TireAirLeakageRate_31 521531;
BA_ "SigType" SG_ 2566845694 TireAirLeakageRate_32 1;
BA_ "SPN" SG_ 2566845694 TireAirLeakageRate_32 521532;
BA_ "SigType" SG_ 2566845694 TireAirLeakageRate_33 1;
BA_ "SPN" SG_ 2566845694 TireAirLeakageRate_33 521533;
BA_ "SigType" SG_ 2566845694 ExTirePressSupport 4;
BA_ "SPN" SG_ 2566845694 ExTirePressSupport 6990;
BA_ "SigType" SG_ 2566845694 CTIWheelEndElectricalFault_00 4;
BA_ "SPN" SG_ 2566845694 CTIWheelEndElectricalFault_00 521200;
BA_ "SigType" SG_ 2566845694 CTIWheelEndElectricalFault_01 4;
BA_ "SPN" SG_ 2566845694 CTIWheelEndElectricalFault_01 521201;
BA_ "SigType" SG_ 2566845694 CTIWheelEndElectricalFault_10 4;
BA_ "SPN" SG_ 2566845694 CTIWheelEndElectricalFault_10 521210;
BA_ "SigType" SG_ 2566845694 CTIWheelEndElectricalFault_11 4;
BA_ "SPN" SG_ 2566845694 CTIWheelEndElectricalFault_11 521211;
BA_ "SigType" SG_ 2566845694 CTIWheelEndElectricalFault_12 4;
BA_ "SPN" SG_ 2566845694 CTIWheelEndElectricalFault_12 521212;
BA_ "SigType" SG_ 2566845694 CTIWheelEndElectricalFault_13 4;
BA_ "SPN" SG_ 2566845694 CTIWheelEndElectricalFault_13 521213;
BA_ "SigType" SG_ 2566845694 CTIWheelEndElectricalFault_20 4;
BA_ "SPN" SG_ 2566845694 CTIWheelEndElectricalFault_20 521220;
BA_ "SigType" SG_ 2566845694 CTIWheelEndElectricalFault_21 4;
BA_ "SPN" SG_ 2566845694 CTIWheelEndElectricalFault_21 521221;
BA_ "SigType" SG_ 2566845694 CTIWheelEndElectricalFault_22 4;
BA_ "SPN" SG_ 2566845694 CTIWheelEndElectricalFault_22 521222;
BA_ "SigType" SG_ 2566845694 CTIWheelEndElectricalFault_23 4;
BA_ "SPN" SG_ 2566845694 CTIWheelEndElectricalFault_23 521223;
BA_ "SigType" SG_ 2566845694 CTIWheelEndElectricalFault_30 4;
BA_ "SPN" SG_ 2566845694 CTIWheelEndElectricalFault_30 521230;
BA_ "SigType" SG_ 2566845694 CTIWheelEndElectricalFault_31 4;
BA_ "SPN" SG_ 2566845694 CTIWheelEndElectricalFault_31 521231;
BA_ "SigType" SG_ 2566845694 CTIWheelEndElectricalFault_32 4;
BA_ "SPN" SG_ 2566845694 CTIWheelEndElectricalFault_32 521232;
BA_ "SigType" SG_ 2566845694 CTIWheelEndElectricalFault_33 4;
BA_ "SPN" SG_ 2566845694 CTIWheelEndElectricalFault_33 521233;
BA_ "SigType" SG_ 2566845694 CTITireStatus_00 4;
BA_ "SPN" SG_ 2566845694 CTITireStatus_00 521300;
BA_ "SigType" SG_ 2566845694 CTITireStatus_01 4;
BA_ "SPN" SG_ 2566845694 CTITireStatus_01 521301;
BA_ "SigType" SG_ 2566845694 CTITireStatus_10 4;
BA_ "SPN" SG_ 2566845694 CTITireStatus_10 521310;
BA_ "SigType" SG_ 2566845694 CTITireStatus_11 4;
BA_ "SPN" SG_ 2566845694 CTITireStatus_11 521311;
BA_ "SigType" SG_ 2566845694 CTITireStatus_12 4;
BA_ "SPN" SG_ 2566845694 CTITireStatus_12 521312;
BA_ "SigType" SG_ 2566845694 CTITireStatus_13 4;
BA_ "SPN" SG_ 2566845694 CTITireStatus_13 521313;
BA_ "SigType" SG_ 2566845694 CTITireStatus_20 4;
BA_ "SPN" SG_ 2566845694 CTITireStatus_20 521320;
BA_ "SigType" SG_ 2566845694 CTITireStatus_21 4;
BA_ "SPN" SG_ 2566845694 CTITireStatus_21 521321;
BA_ "SigType" SG_ 2566845694 CTITireStatus_22 4;
BA_ "SPN" SG_ 2566845694 CTITireStatus_22 521322;
BA_ "SigType" SG_ 2566845694 CTITireStatus_23 4;
BA_ "SPN" SG_ 2566845694 CTITireStatus_23 521323;
BA_ "SigType" SG_ 2566845694 CTITireStatus_30 4;
BA_ "SPN" SG_ 2566845694 CTITireStatus_30 521330;
BA_ "SigType" SG_ 2566845694 CTITireStatus_31 4;
BA_ "SPN" SG_ 2566845694 CTITireStatus_31 521331;
BA_ "SigType" SG_ 2566845694 CTITireStatus_32 4;
BA_ "SPN" SG_ 2566845694 CTITireStatus_32 521332;
BA_ "SigType" SG_ 2566845694 CTITireStatus_33 4;
BA_ "SPN" SG_ 2566845694 CTITireStatus_33 521333;
BA_ "SigType" SG_ 2566845694 CTIWheelSensorStatus_00 4;
BA_ "SPN" SG_ 2566845694 CTIWheelSensorStatus_00 521400;
BA_ "SigType" SG_ 2566845694 CTIWheelSensorStatus_01 4;
BA_ "SPN" SG_ 2566845694 CTIWheelSensorStatus_01 521401;
BA_ "SigType" SG_ 2566845694 CTIWheelSensorStatus_10 4;
BA_ "SPN" SG_ 2566845694 CTIWheelSensorStatus_10 521410;
BA_ "SigType" SG_ 2566845694 CTIWheelSensorStatus_11 4;
BA_ "SPN" SG_ 2566845694 CTIWheelSensorStatus_11 521411;
BA_ "SigType" SG_ 2566845694 CTIWheelSensorStatus_12 4;
BA_ "SPN" SG_ 2566845694 CTIWheelSensorStatus_12 521412;
BA_ "SigType" SG_ 2566845694 CTIWheelSensorStatus_13 4;
BA_ "SPN" SG_ 2566845694 CTIWheelSensorStatus_13 521413;
BA_ "SigType" SG_ 2566845694 CTIWheelSensorStatus_20 4;
BA_ "SPN" SG_ 2566845694 CTIWheelSensorStatus_20 521420;
BA_ "SigType" SG_ 2566845694 CTIWheelSensorStatus_21 4;
BA_ "SPN" SG_ 2566845694 CTIWheelSensorStatus_21 521421;
BA_ "SigType" SG_ 2566845694 CTIWheelSensorStatus_22 4;
BA_ "SPN" SG_ 2566845694 CTIWheelSensorStatus_22 521422;
BA_ "SigType" SG_ 2566845694 CTIWheelSensorStatus_23 4;
BA_ "SPN" SG_ 2566845694 CTIWheelSensorStatus_23 521423;
BA_ "SigType" SG_ 2566845694 CTIWheelSensorStatus_30 4;
BA_ "SPN" SG_ 2566845694 CTIWheelSensorStatus_30 521430;
BA_ "SigType" SG_ 2566845694 CTIWheelSensorStatus_31 4;
BA_ "SPN" SG_ 2566845694 CTIWheelSensorStatus_31 521431;
BA_ "SigType" SG_ 2566845694 CTIWheelSensorStatus_32 4;
BA_ "SPN" SG_ 2566845694 CTIWheelSensorStatus_32 521432;
BA_ "SigType" SG_ 2566845694 CTIWheelSensorStatus_33 4;
BA_ "SPN" SG_ 2566845694 CTIWheelSensorStatus_33 521433;
BA_ "SigType" SG_ 2566845694 TireTemp_00 1;
BA_ "SPN" SG_ 2566845694 TireTemp_00 521100;
BA_ "SigType" SG_ 2566845694 TireTemp_01 1;
BA_ "SPN" SG_ 2566845694 TireTemp_01 521101;
BA_ "SigType" SG_ 2566845694 TireTemp_10 1;
BA_ "SPN" SG_ 2566845694 TireTemp_10 521110;
BA_ "SigType" SG_ 2566845694 TireTemp_12 1;
BA_ "SPN" SG_ 2566845694 TireTemp_12 521112;
BA_ "SigType" SG_ 2566845694 TireTemp_13 1;
BA_ "SPN" SG_ 2566845694 TireTemp_13 521113;
BA_ "SigType" SG_ 2566845694 TireTemp_20 1;
BA_ "SPN" SG_ 2566845694 TireTemp_20 521120;
BA_ "SigType" SG_ 2566845694 TireTemp_21 1;
BA_ "SPN" SG_ 2566845694 TireTemp_21 521121;
BA_ "SigType" SG_ 2566845694 TireTemp_22 1;
BA_ "SPN" SG_ 2566845694 TireTemp_22 521122;
BA_ "SigType" SG_ 2566845694 TireTemp_23 1;
BA_ "SPN" SG_ 2566845694 TireTemp_23 521123;
BA_ "SigType" SG_ 2566845694 TireTemp_30 1;
BA_ "SPN" SG_ 2566845694 TireTemp_30 521130;
BA_ "SigType" SG_ 2566845694 TireTemp_31 1;
BA_ "SPN" SG_ 2566845694 TireTemp_31 521131;
BA_ "SigType" SG_ 2566845694 TireTemp_32 1;
BA_ "SPN" SG_ 2566845694 TireTemp_32 521132;
BA_ "SigType" SG_ 2566845694 TireTemp_33 1;
BA_ "SPN" SG_ 2566845694 TireTemp_33 521133;
BA_ "SigType" SG_ 2566845694 TireTemp_11 1;
BA_ "SPN" SG_ 2566845694 TireTemp_11 521111;
BA_ "SigType" SG_ 2566845694 TirePress_00 1;
BA_ "SPN" SG_ 2566845694 TirePress_00 521000;
BA_ "SigType" SG_ 2566845694 TirePress_01 1;
BA_ "SPN" SG_ 2566845694 TirePress_01 521001;
BA_ "SigType" SG_ 2566845694 TirePress_10 1;
BA_ "SPN" SG_ 2566845694 TirePress_10 521010;
BA_ "SigType" SG_ 2566845694 TirePress_11 1;
BA_ "SPN" SG_ 2566845694 TirePress_11 521011;
BA_ "SigType" SG_ 2566845694 TirePress_12 1;
BA_ "SPN" SG_ 2566845694 TirePress_12 521012;
BA_ "SigType" SG_ 2566845694 TirePress_13 1;
BA_ "SPN" SG_ 2566845694 TirePress_13 521013;
BA_ "SigType" SG_ 2566845694 TirePress_20 1;
BA_ "SPN" SG_ 2566845694 TirePress_20 521020;
BA_ "SigType" SG_ 2566845694 TirePress_21 1;
BA_ "SPN" SG_ 2566845694 TirePress_21 521021;
BA_ "SigType" SG_ 2566845694 TirePress_22 1;
BA_ "SPN" SG_ 2566845694 TirePress_22 521022;
BA_ "SigType" SG_ 2566845694 TirePress_23 1;
BA_ "SPN" SG_ 2566845694 TirePress_23 521023;
BA_ "SigType" SG_ 2566845694 TirePress_30 1;
BA_ "SPN" SG_ 2566845694 TirePress_30 521030;
BA_ "SigType" SG_ 2566845694 TirePress_31 1;
BA_ "SPN" SG_ 2566845694 TirePress_31 521031;
BA_ "SigType" SG_ 2566845694 TirePress_32 1;
BA_ "SPN" SG_ 2566845694 TirePress_32 521032;
BA_ "SigType" SG_ 2566845694 TirePress_33 1;
BA_ "SPN" SG_ 2566845694 TirePress_33 521033;
BA_ "SPN" SG_ 2566845694 TireLocation 929;
BA_ "GenMsgCycleTime" BO_ 2650238974 500;
BA_ "GenMsgCycleTime" BO_ 2600457214 1000;
BA_ "GenMsgSendType" BO_ 2600457214 0;
BA_ "SendOnChange" BO_ 2600457214 1;
BA_ "GenMsgDelayTime" BO_ 2600457214 100;
BA_ "GenSigStartValue" SG_ 2600457214 VSM_Int_InitDecision 9;
BA_ "GenMsgSendType" BO_ 2399126014 0;
BA_ "GenMsgCycleTime" BO_ 2399126014 100;
BA_ "GenMsgCycleTime" BO_ 2365574398 1000;
BA_ "GenSigStartValue" SG_ 2365574398 VehicleSpeedDCU 25000;
BA_ "GenSigStartValue" SG_ 2365574398 SlopeDebug 1;
BA_ "GenMsgRequestable" BO_ 2650739198 0;
BA_ "SPN" SG_ 2650739198 BootloaderVerBuild 519392;
BA_ "SPN" SG_ 2650739198 BootloaderVerFix 519391;
BA_ "SPN" SG_ 2650739198 BootloaderVerMinor 519390;
BA_ "SPN" SG_ 2650739198 BootloaderVerMajor 519389;
BA_ "SPN" SG_ 2650739198 BootloaderVerGeneration 519388;
VAL_ 2180532222 LightSensorOnOffReq 3 "Not Available" 2 "Reserved" 1 "TurnOn" 0 "TurnOff" ;
VAL_ 2180532222 LightSensorError 3 "Not Available" 2 "Reserved" 1 "Erroneous" 0 "NoErrors" ;
VAL_ 2583065598 CentralLockFailState 15 "Not Available" 14 "Error" 13 "Reserved6" 12 "Reserved5" 11 "Reserved4" 10 "Reserved3" 9 "Reserved2" 8 "Reserved1" 7 "Centlock In Fault" 6 "Cargo Side Door Unlock Fail" 5 "Cargo Rear Door Unlock Fail" 4 "Passenger Door Unlock Fail" 3 "Driver Door Unlock Fail" 2 "Vehicle Fully Lock Fail" 1 "Vehicle Unlock Fail" 0 "No Fail" ;
VAL_ 2583065598 CentralLockCommand 30 "Error" 28 "Reserved" 26 "Reserved" 24 "Reserved" 22 "Reserved" 31 "Not Available" 29 "Reserved" 27 "Reserved" 25 "Reserved" 23 "Reserved" 21 "Reserved" 19 "Reserved" 18 "Reserved" 17 "Reserved" 20 "Reserved" 16 "Reserved" 15 "Reserved" 14 "Unlock Driver Door Internal" 13 "Unlock Driver Door" 12 "Lock Driver Door Internal" 11 "Lock Driver Door" 10 "Unlock All Doors Internal" 9 "Unlock All Doors" 8 "Lock All Doors Internal" 7 "Lock All Doors" 6 "Find Car Action" 5 "User Near Vehicle" 4 "User Out of Vehicle" 3 "Bye Action" 2 "Welcome Action" 1 "Sleep Vehicle" 0 "Wake Up Vehicle" ;
VAL_ 2180392702 RollerShutterFaults 7 "Not Available" 6 "CalibrationFail" 5 "UnknownPosition" 4 "Under Voltage" 3 "Over Voltage" 2 "Motor Overload" 1 "Movement Interrupted" 0 "No Fault" ;
VAL_ 2180392702 RollerShutterStatus 7 "Not available" 6 "Error" 5 "Unknown" 4 "Closing" 3 "Opening" 2 "Intermediate" 1 "Closed" 0 "Open" ;
VAL_ 2382107390 BRKBrakeLightRq 3 "Don't care/Take no action" 2 "Reserved" 1 "Turn brake light on" 0 "Turn brake light off" ;
VAL_ 2399121662 LVReadyToUpdate 3 "NA" 2 "Error" 1 "Ready" 0 "NotReady" ;
VAL_ 2399121662 LVReadyToSleep 3 "Not available" 2 "Fault" 1 "Ready" 0 "Not Ready" ;
VAL_ 2399121662 LVAllowedLoad 4 "NotAllowed" 3 "AllActive" 7 "NotAvailable" 6 "Error" 2 "CriticalOnly" 1 "PrimaryAllowed" 0 "AllAllowed" ;
VAL_ 2399121662 LVNotificationReq 6 "Not Available" 5 "Fault" 4 "Stop_safely" 3 "Drive_with_caution" 2 "LV_power_supply_limited" 1 "LV_system_requires_service" 0 "No_notification_required" ;
VAL_ 2399121662 DrivetrainLimpModeReq 3 "NA" 2 "Error" 1 "Requested" 0 "Not requested" ;
VAL_ 2399121662 LVAlertFlatBattery 3 "NA" 2 "Error" 1 "Alert" 0 "Normal" ;
VAL_ 2399121662 LVTopUpRequest 3 "NA" 2 "Error" 1 "Required" 0 "Not required" ;
VAL_ 2399121662 LVSystemCharging 3 "NA" 2 "Error" 1 "Charging" 0 "Not charging " ;
VAL_ 2399121662 LVReadyToDrive 3 "NA" 2 "Error" 1 "Ready" 0 "Not Ready" ;
VAL_ 2399121662 LVState 3 "NA" 2 "Fault" 0 "OFF" 1 "ON" ;
VAL_ 2365435390 MainBeamStalksReq 3 "Not available" 2 "Full Pull" 1 "Half Pull" 0 "No Action" ;
VAL_ 2365435390 TurnIndReq 5 "Not available" 4 "Full Down" 3 "Half Down" 2 "Full Up" 1 "Half Up" 0 "No Action" ;
VAL_ 2365435390 SwitchReq 3 "Not available" 2 "Reserved" 1 "Pressed" 0 "No Action" ;
VAL_ 2365473278 ImplementRearWorkLightCmd 3 "Don't Care" 2 "Reserved" 1 "Activate" 0 "De-activate" ;
VAL_ 2365473278 ImplLeftFacingWorkLightCmd 3 "Don't Care" 2 "Reserved" 1 "Activate" 0 "De-activate" ;
VAL_ 2365473278 ImplRightFwdWorkLightCmd 3 "Don't Care" 2 "Reserved" 1 "Activate" 0 "De-activate" ;
VAL_ 2365473278 LightingDataRqCmd 3 "Don't Care" 2 "Reserved" 1 "Activate" 0 "De-activate" ;
VAL_ 2365473278 ImplLeftForwardWorkLightCmd 3 "Don't Care" 2 "Reserved" 1 "Activate" 0 "De-activate" ;
VAL_ 2365473278 ImplRightFacingWorkLightCmd 3 "Don't Care" 2 "Reserved" 1 "Activate" 0 "De-activate" ;
VAL_ 2365473278 ImplOEMOption1LightCmd 3 "Don't Care" 2 "Reserved" 1 "Activate" 0 "De-activate" ;
VAL_ 2365473278 ImplOEMOption2LightCmd 3 "Don't Care" 2 "Reserved" 1 "Activate" 0 "De-activate" ;
VAL_ 2365473278 TrctrFrntHghMdWkLightsCmd 3 "Don't Care" 2 "Reserved" 1 "Activate" 0 "De-activate" ;
VAL_ 2365473278 TrctrFrntLowMdWkLightsCmd 3 "Don't Care" 2 "Reserved" 1 "Activate" 0 "De-activate" ;
VAL_ 2365473278 TrctrSdeHighMdWkLightsCmd 3 "Don't Care" 2 "Reserved" 1 "Activate" 0 "De-activate" ;
VAL_ 2365473278 TrctrSideLowMdWkLightsCmd 3 "Don't Care" 2 "Reserved" 1 "Activate" 0 "De-activate" ;
VAL_ 2365473278 TrctrRarHighMdWkLightsCmd 3 "Don't Care" 2 "Reserved" 1 "Activate" 0 "De-activate" ;
VAL_ 2365473278 TrctrRearLowMdWkLightsCmd 3 "Don't Care" 2 "Reserved" 1 "Activate" 0 "De-activate" ;
VAL_ 2365473278 TrctrUndrsdeMdWkLightsCmd 3 "Don't Care" 2 "Reserved" 1 "Activate" 0 "De-activate" ;
VAL_ 2365473278 RearFogLightsCmd 3 "Don't Care" 2 "Reserved" 1 "Activate" 0 "De-activate" ;
VAL_ 2365473278 TractorMarkerLightCmd 3 "Don't Care" 2 "Reserved" 1 "Activate" 0 "De-activate" ;
VAL_ 2365473278 ImplementMarkerLightCmd 2 "Reserved" 3 "Don't Care" 1 "Activate" 0 "De-activate" ;
VAL_ 2365473278 TractorClearanceLightCmd 3 "Don't Care" 2 "Reserved" 1 "Activate" 0 "De-activate" ;
VAL_ 2365473278 ImplementClearanceLightCmd 3 "Don't Care" 2 "Reserved" 1 "Activate" 0 "De-activate" ;
VAL_ 2365473278 LeftStopLightCmd 3 "Don't Care" 2 "Reserved" 1 "Activate" 0 "De-activate" ;
VAL_ 2365473278 RightStopLightCmd 3 "Don't Care" 2 "Reserved" 1 "Activate" 0 "De-activate" ;
VAL_ 2365473278 CenterStopLightCmd 3 "Don't Care" 2 "Reserved" 1 "Activate" 0 "De-activate" ;
VAL_ 2365473278 BackUpLightAndAlarmHornCmd 3 "Don't Care" 2 "Reserved" 1 "Activate" 0 "De-activate" ;
VAL_ 2365473278 LeftTurnSignalLightsCmd 3 "Don't Care" 2 "Reserved" 1 "Activate" 0 "De-activate" ;
VAL_ 2365473278 RightTurnSignalLightsCmd 3 "Don't Care" 2 "Reserved" 1 "Activate" 0 "De-activate" ;
VAL_ 2365473278 RotatingBeaconLightCmd 3 "Don't Care" 2 "Reserved" 1 "Activate" 0 "De-activate" ;
VAL_ 2365473278 TractorFrontFogLightsCmd 3 "Don't Care" 2 "Reserved" 1 "Activate" 0 "De-activate" ;
VAL_ 2365473278 HighBeamHeadLightCmd 3 "Don't Care" 2 "Reserved" 1 "Activate" 0 "De-activate" ;
VAL_ 2365473278 LowBeamHeadLightCmd 3 "Don't Care" 2 "Reserved" 1 "Activate" 0 "De-activate" ;
VAL_ 2365473278 AltBeamHeadLightCmd 3 "Don't Care" 2 "Reserved" 1 "Activate" 0 "De-activate" ;
VAL_ 2365473278 RunningLightCmd 3 "Don't Care" 2 "Reserved" 1 "Activate" 0 "De-activate" ;
VAL_ 2566799614 ImplementRearWorkLight 3 "Not Available" 2 "Fault Detected" 1 "Activated" 0 "De-activated" ;
VAL_ 2566799614 ImplLeftFacingWorkLight 3 "Not Available" 2 "Fault Detected" 1 "Activated" 0 "De-activated" ;
VAL_ 2566799614 ImplRightForwardWorkLight 3 "Not Available" 2 "Fault Detected" 1 "Activated" 0 "De-activated" ;
VAL_ 2566799614 ImplLeftForwardWorkLight 3 "Not Available" 2 "Fault Detected" 1 "Activated" 0 "De-activated" ;
VAL_ 2566799614 ImplRightFacingWorkLight 3 "Not Available" 2 "Fault Detected" 1 "Activated" 0 "De-activated" ;
VAL_ 2566799614 ImplementOEMOption1Light 3 "Not Available" 2 "Fault Detected" 1 "Activated" 0 "De-activated" ;
VAL_ 2566799614 ImplementOEMOption2Light 3 "Not Available" 2 "Fault Detected" 1 "Activated" 0 "De-activated" ;
VAL_ 2566799614 TrctorFrontHighMdWkLights 3 "Not Available" 2 "Fault Detected" 1 "Activated" 0 "De-activated" ;
VAL_ 2566799614 TractorFrontLowMdWkLights 3 "Not Available" 2 "Fault Detected" 1 "Activated" 0 "De-activated" ;
VAL_ 2566799614 TractorSideHighMdWkLights 3 "Not Available" 2 "Fault Detected" 1 "Activated" 0 "De-activated" ;
VAL_ 2566799614 TractorSideLowMdWkLights 3 "Not Available" 2 "Fault Detected" 1 "Activated" 0 "De-activated" ;
VAL_ 2566799614 TractorRearHighMdWkLights 3 "Not Available" 2 "Fault Detected" 1 "Activated" 0 "De-activated" ;
VAL_ 2566799614 TractorRearLowMdWkLights 3 "Not Available" 2 "Fault Detected" 1 "Activated" 0 "De-activated" ;
VAL_ 2566799614 TrctorUndersideMdWkLights 3 "Not Available" 2 "Fault Detected" 1 "Activated" 0 "De-activated" ;
VAL_ 2566799614 RearFogLights 3 "Not Available" 2 "Fault Detected" 1 "Activated" 0 "De-activated" ;
VAL_ 2566799614 TractorMarkerLight 3 "Not Available" 2 "Fault Detected" 1 "Activated" 0 "De-activated" ;
VAL_ 2566799614 ImplementMarkerLight 3 "Not Available" 2 "Fault Detected" 1 "Activated" 0 "De-activated" ;
VAL_ 2566799614 TractorClearanceLight 3 "Not Available" 2 "Fault Detected" 1 "Activated" 0 "De-activated" ;
VAL_ 2566799614 ImplementClearanceLight 3 "Not Available" 2 "Fault Detected" 1 "Activated" 0 "De-activated" ;
VAL_ 2566799614 LeftStopLight 3 "Not Available" 2 "Fault Detected" 1 "Activated" 0 "De-activated" ;
VAL_ 2566799614 RightStopLight 3 "Not Available" 2 "Fault Detected" 1 "Activated" 0 "De-activated" ;
VAL_ 2566799614 CenterStopLight 3 "Not Available" 2 "Fault Detected" 1 "Activated" 0 "De-activated" ;
VAL_ 2566799614 BackUpLightAndAlarmHorn 3 "Not Available" 2 "Fault Detected" 1 "Activated" 0 "De-activated" ;
VAL_ 2566799614 LeftTurnSignalLights 3 "Not Available" 2 "Fault Detected" 1 "Activated" 0 "De-activated" ;
VAL_ 2566799614 RightTurnSignalLights 3 "Not Available" 2 "Fault Detected" 1 "Activated" 0 "De-activated" ;
VAL_ 2566799614 RotatingBeaconLight 3 "Not Available" 2 "Fault Detected" 1 "Activated" 0 "De-activated" ;
VAL_ 2566799614 TractorFrontFogLights 3 "Not Available" 2 "Fault Detected" 1 "Activated" 0 "De-activated" ;
VAL_ 2566799614 HighBeamHeadLight 3 "Not Available" 2 "Fault Detected" 1 "Activated" 0 "De-activated" ;
VAL_ 2566799614 LowBeamHeadLight 3 "Not Available" 2 "Fault Detected" 1 "Activated" 0 "De-activated" ;
VAL_ 2566799614 AltBeamHeadLight 3 "Not Available" 2 "Fault Detected" 1 "Activated" 0 "De-activated" ;
VAL_ 2566799614 RunningLight 3 "Not Available" 2 "Fault Detected" 1 "Activated" 0 "De-activated" ;
VAL_ 2565868030 SteerWheelAngleSensorType 3 "Not Available" 2 "Reserved" 1 "Absolute measuring principle" 0 "Relative measuring principle" ;
VAL_ 2365583358 HazardLightSwitch 3 "Not available" 2 "Error" 1 "Hazard Lamps to be Flashing" 0 "Hazard Lamps to be Off" ;
VAL_ 2566767870 EmergencyBrakingActive 3 "not available" 2 "reserved" 1 "active" 0 "inactive" ;
VAL_ 2566767870 PrkngBrakeActuatorFullyActivated 3 "Not available" 2 "Error" 1 "Parking Brake Actuator fully activated" 0 "Parking Brake Actuator not fully activated" ;
VAL_ 2566767870 XBRActiveCtrlMode 15 "Not available" 3 "Maximum mode of XBR acceleration control being executed" 2 "Addition mode of XBR acceleration control being executed" 1 "Driver's brake demand being executed" 0 "No brake demand being executed" ;
VAL_ 2566767870 XBRSystemState 3 "not available" 2 "No external brake demand will be accepted" 1 "Only external brake demand of highest XBR Priority" 0 "Any external brake demand will be accepted" ;
VAL_ 2566767870 FoundationBrakeUse 3 "Not available" 2 "Reserved" 1 "Foundation brakes in use" 0 "Foundation brakes not in use" ;
VAL_ 2566767870 HillHolderMode 7 "Not available" 6 "Hill holder not functional" 3 "Active,  but may activate parking brake if needed." 2 "Active,  but will change to inactive in a short time" 1 "Active" 0 "Inactive" ;
VAL_ 2566767870 HaltBrakeMode 7 "Not available" 6 "Halt brake not functional" 2 "Active,  but not functioning properly" 1 "Active" 0 "Inactive" ;
VAL_ 2566767870 BrakeTempWarning 3 "not available" 2 "Reserved" 1 "Active" 0 "Not Active" ;
VAL_ 2365484286 DirectionIndicator 3 "Not available" 2 "Error" 1 "Reverse" 0 "Forward" ;
VAL_ 2365484286 TachographPerformance 3 "Not available" 2 "Error" 1 "Performance analysis" 0 "Normal performance" ;
VAL_ 2365484286 HandlingInformation 3 "Not available" 2 "Error" 1 "Handling information" 0 "No handling information" ;
VAL_ 2365484286 SystemEvent 3 "Not available" 2 "Error" 1 "Tachograph event" 0 "No tachograph event" ;
VAL_ 2365484286 DriverCardDriver2 3 "Not available" 2 "Error" 1 "Driver card present" 0 "Driver card not present" ;
VAL_ 2365484286 Driver2TimeRelatedStates 15 "Not available" 14 "Error" 13 "Other" 6 "Limit #6" 5 "Limit #5" 4 "Limit #4" 3 "Limit #3" 2 "Limit #2" 1 "Limit #1" 0 "Normal/No limits reached" ;
VAL_ 2365484286 VehicleOverspeed 3 "Not available" 2 "Error" 1 "Overspeed" 0 "No overspeed" ;
VAL_ 2365484286 DriverCardDriver1 3 "Not available" 2 "Error" 1 "Driver card present" 0 "Driver card not present" ;
VAL_ 2365484286 Driver1TimeRelatedStates 15 "Not available" 14 "Error" 13 "Other" 6 "Limit #6" 5 "Limit #5" 4 "Limit #4" 3 "Limit #3" 2 "Limit #2" 1 "Limit #1" 0 "Normal/No limits reached" ;
VAL_ 2365484286 VehicleMotion 3 "- Not available" 2 "- Error" 1 "Vehicle motion detected" 0 "Vehicle motion not detected" ;
VAL_ 2365484286 Driver2WorkingState 7 "Not available" 6 "Error" 3 "Drive" 2 "Work" 1 "Driver available" 0 "Rest" ;
VAL_ 2365484286 Driver1WorkingState 7 "Not available" 6 "Error" 3 "Drive" 2 "Work" 1 "Driver available" 0 "Rest" ;
VAL_ 2180924414 CCI_ACPlugLockPosition 2 "Not Locked" 1 "Locked" 0 "Unlocked" ;
VAL_ 2180924414 CCI_ACDCPortHatchState 2 "Hatch fully opened" 1 "Hatch closed" 0 "Hatch not closed" ;
VAL_ 2180924414 CCI_ACPortHatchState 2 "Hatch fully opened" 1 "Hatch closed" 0 "Hatch not closed" ;
VAL_ 2180924414 CCI_ACPortButtonState 3 "Reserve" 2 "Released" 1 "Pressed" 0 "Unknown" ;
VAL_ 2180924414 CCI_ACDCPortButtonState 3 "Reserve" 2 "Released" 1 "Pressed" 0 "Unknown" ;
VAL_ 2382314494 GS_VSMInhibits 7 "NA" 6 "NVSMInhib" 1 "RDDoorInhib" 0 "NoVSMNotif" 5 "NChargeInhib" 4 "RDVSMInhib" 3 "RDChargInhib" 2 "RDRampInhib" ;
VAL_ 2382314494 GS_Inhibits 7 "NA" 6 "Error" 1 "RDSpeedInhib" 0 "NoNotification" 5 "RNDChargeInhib" 4 "PSpeedInhib" 3 "NBrakeInhib" 2 "RDBrakeInhib" ;
VAL_ 2382314494 GS_Est_State 14 "Park_Reverse" 13 "Park_Drive" 11 "Change_in_Progress" 10 "Reverse_PErr" 9 "Drive_PErr" 8 "Neutral_PErr" 7 "Park_DT_Err" 6 "DT_Err" 5 "Reverse" 4 "Drive" 3 "Neutral" 2 "Park" 1 "Error" 0 "N_A" ;
VAL_ 2382314494 Drvtr_state 11 "Change_in_Progress" 1 "Error" 0 "N_A" 5 "Reverse" 4 "Drive" 3 "Neutral" ;
VAL_ 2382314494 move_lock_req 2 "Take_no_action" 1 "Unlocked" 0 "Locked" ;
VAL_ 2382314494 GS_Demand 16 "Reverse_ NoAction" 15 "Drive_NoAction" 14 "Park_Reverse" 13 "Park_Drive" 12 "Neutral_NoAction" 5 "Reverse" 4 "Drive" 3 "Neutral" 2 "Park" ;
VAL_ 2180926462 CCI_ACDCHatchCloseCmd 7 "ACDCHatchSt NA" 2 "ACDCHatchSt Open" 1 "ACDCHatchSt Close" 0 "ACDCHatchSt No Request" ;
VAL_ 2180926462 CCI_ACDCPlugLockRequest 7 "ACDCPlugLock NA" 2 "ACDCPlugLock Unlock" 1 "ACDCPlugLock Lock" 0 "ACDCPlugLock No Request" ;
VAL_ 2399117310 VSM_Substate 4 "Substate4" 3 "Substate3" 2 "Substate2" 1 "Substate1" 0 "Default" ;
VAL_ 2399117310 VSM_State 7 "NA" 5 "LongTerm Park" 4 "Maintenance" 3 "Charging" 2 "Ready" 1 "Awake" 0 "Sleep" ;
VAL_ 2566883070 RollerShutterLatchNotify 3 "Not Available" 2 "Error" 1 "Active" 0 "Inactive" ;
VAL_ 2566883070 DoorLatchNotify 3 "Not Available" 2 "Error" 1 "Active" 0 "Inactive" ;
VAL_ 2382241534 BatteryOvercoolEvent 3 "Not Available" 2 "Error" 1 "On" 0 "Off" ;
VAL_ 2382241534 CoolantTank_2_LevelSt 3 "NA" 2 "Reserved" 1 "High" 0 "Low" ;
VAL_ 2382241534 CoolantTank_1_LevelSt 3 "NA" 2 "Reserved" 1 "High" 0 "Low" ;
VAL_ 2382241534 OverheatEvent_Overall 3 "Overheat_NA" 2 "Overheat_Error" 1 "Overheat_Detected" 0 "Overheat_Not_Detected" ;
VAL_ 2382241534 MalfunctionEvent_Overall 3 "NA" 2 "Critical_Event" 1 "Medium_Event" 0 "Not_Detected" ;
VAL_ 2382241534 OverheatEvent 15 "Overheat_NA" 14 "Overheat_Error" 6 "Overheat_Battery" 5 "Overheat_DCDC" 4 "Overheat_OBC" 3 "Overheat_Gearbox" 2 "Overheat_Motor" 1 "Overheat_Invertor" 0 "Overheat_Nothing" ;
VAL_ 2382241534 ThermalSystemFault 14 "ThrFlt_Error" 15 "ThrFlt_NA" 3 "ThrFlt_DeviceFault" 2 "ThrFlt_CAN_Comm" 1 "ThrFlt_AmbOORange" 0 "ThrFlt_Nothing" ;
VAL_ 2297441790 SpprtVrblTrnsRpttnRtFrAcclrtnSns 3 "ECU only supports standard transmission rate of 10 ms" 2 "20 ms rate supported" 1 "Reserved for SAE assignment" 0 "Reserve for SAE assignment" ;
VAL_ 2297441790 VrtclAcclrtnExRangeFigureOfMerit 3 "not available" 2 "error" 1 "verticalacceleration is degraded" 0 "vertical acceleration is fully functional" ;
VAL_ 2297441790 LngtdnlAcclrtnExRngFigureOfMerit 3 "not available" 2 "error" 1 "longitudinal acceleration is degraded" 0 "longitudinal acceleration is fully functional" ;
VAL_ 2297441790 LtrlAcclrtonExRangeFigureOfMerit 3 "not available" 2 "error" 1 "lateral acceleration is degraded" 0 "lateral acceleration is fully functional" ;
VAL_ 2583173886 WipeRequest 7 "WPR_NA" 6 "WPR_Reserved" 5 "WPR_Auto" 4 "WPR_HighSpeed" 3 "WPR_LowSpeed" 2 "WPR_Intermittent" 1 "WPR_SingleStroke" 0 "WPR_TurnOff" ;
VAL_ 2583173886 WashRequest 3 "NA" 2 "Error" 1 "WSH_TurnOn" 0 "WSH_TurnOff" ;
VAL_ 2516075518 RideHeight_Value 0 "Nominal" 1 "Upper" 2 "Lower" 3 "Kneeling" 4 "JackMode" 5 "Fault" 6 "NA" 7 "Reserved" ;
VAL_ 2566882814 KeyRange 7 "Not Available" 6 "Error" 5 "In Cabin" 4 "In Use Range" 3 "In Wake Up Range" 2 "In Operational Range" 1 "Out of Operational Range" 0 "Lost" ;
VAL_ 2566882814 KeyCommand 7 "Not Available" 6 "Error" 5 "Reserved" 4 "Reserved" 3 "Reserved" 2 "Find Car" 1 "Fully Lock Vehicle" 0 "Unlock Vehicle" ;
VAL_ 2583062526 CentralLockRequest 7 "Not Available" 6 "Error" 5 "Unlock Cargo Side Door" 4 "Unlock Cargo Rear Door" 3 "Unlock Passenger Door" 2 "Unlock Driver Door" 1 "Fully Lock Vehicle" 0 "Unlock Vehicle" ;
VAL_ 2399123966 KeyfobBatteryState 7 "NA" 6 "Error" 5 "Reserved" 4 "Reserved" 3 "Reserved" 2 "Critical Level" 1 "Low Level" 0 "Battery OK" ;
VAL_ 2399123966 SecurityWakeUpRequest 3 "NA" 2 "Error" 1 "SecurityWakeUp" 0 "SecurityNotWakeUp" ;
VAL_ 2399123966 SecurityReadyToSleep 3 "NA" 2 "Error" 1 "Security Ready" 0 "Security Not Ready" ;
VAL_ 2399123966 VehicleLockState 3 "NA" 2 "Error" 1 "Unlocked" 0 "Locked" ;
VAL_ 2399123966 DriveSecurityState 3 "NA" 2 "Error" 1 "Unlocked" 0 "Locked" ;
VAL_ 2583065854 CentralLockRequest 7 "Not Available" 6 "Error" 5 "Unlock Cargo Side Door" 4 "Unlock Cargo Rear Door" 3 "Unlock Passenger Door" 2 "Unlock Driver Door" 1 "Fully Lock Vehicle" 0 "Unlock Vehicle" ;
VAL_ 2163223550 CrashType 16 "rollover" 8 "side crash, right)" 4 "side crash, left)" 2 "rear crash" 1 "frontal crash" ;
VAL_ 2448507902 RHSensorsFault 3 "NA" 2 "Reserved" 1 "RH Fault" 0 "Ok" ;
VAL_ 2448507902 PMSWarning 3 "NA" 2 "Fault" 1 "Active" 0 "Off" ;
VAL_ 2448508158 IMUFault 3 "NA" 2 "Reserved" 1 "IMU Fault" 0 "Ok" ;
VAL_ 2583180030 RearHeatedWindscreenFaultSt 3 "NA" 2 "Fault" 1 "NoError" 0 "Error" ;
VAL_ 2583180030 FrontHeatedWindscreenFaultSt 3 "NA" 2 "Fault" 1 "NoError" 0 "Error" ;
VAL_ 2583180030 WindowHeatedGlassSt 3 "Not available" 2 "Error" 1 "On" 0 "Off" ;
VAL_ 2583180030 FrontDoorHeatedGlassSt 3 "Not available" 2 "Error" 1 "On" 0 "Off" ;
VAL_ 2583180030 RearHeatedWindscreenSt 3 "Not available" 2 "Error" 1 "On" 0 "Off" ;
VAL_ 2583180030 FrontHeatedWindscreenSt 3 "Not available" 2 "Error" 1 "On" 0 "Off" ;
VAL_ 2583179774 AutoDefrostReq 3 "Not available" 2 "Error" 1 "On" 0 "Off" ;
VAL_ 2583179774 WindowHeatedGlassReq 3 "Not available" 2 "Error" 1 "On" 0 "Off" ;
VAL_ 2583179774 FrontDoorHeatedGlassReq 3 "Not available" 2 "Error" 1 "On" 0 "Off" ;
VAL_ 2583179774 RearHeatedWindscreenReq 3 "Not available" 2 "Error" 1 "On" 0 "Off" ;
VAL_ 2583179774 FrontHeatedWindscreenReq 3 "Not available" 2 "Error" 1 "On" 0 "Off" ;
VAL_ 2499547902 MirrorRight2HeatCmd 3 "Take no action" 2 "Reserved" 1 "Mirror heat on" 0 "Mirror heat off" ;
VAL_ 2499547902 MirrorLeft2HeatCmd 3 "Take no action" 2 "Reserved" 1 "Mirror heat on" 0 "Mirror heat off" ;
VAL_ 2499547902 MirrorRight1HeatCmd 3 "Take no action" 2 "Reserved" 1 "Mirror heat on" 0 "Mirror heat off" ;
VAL_ 2499547902 MirrorLeft1HeatCmd 3 "Take no action" 2 "Reserved" 1 "Mirror heat on" 0 "Mirror heat off" ;
VAL_ 2499547902 MirrorRight2VerticalCmd 3 "Take no action" 2 "Reserved" 1 "Move down" 0 "Move up" ;
VAL_ 2499547902 MirrorRight2HorizontalCmd 3 "Take no action" 2 "Reserved" 1 "Move right" 0 "Move left" ;
VAL_ 2499547902 MirrorLeft2VerticalCmd 3 "Take no action" 2 "Reserved" 1 "Move down" 0 "Move up" ;
VAL_ 2499547902 MirrorLeft2HorizontalCmd 3 "Take no action" 2 "Reserved" 1 "Move right" 0 "Move left" ;
VAL_ 2499547902 MirrorRight1VerticalCmd 3 "Take no action" 2 "Reserved" 1 "Move down" 0 "Move up" ;
VAL_ 2499547902 MirrorRight1HorizontalCmd 3 "Take no action" 2 "Reserved" 1 "Move right" 0 "Move left" ;
VAL_ 2499547902 MirrorLeft1VerticalCmd 3 "Take no action" 2 "Reserved" 1 "Move down" 0 "Move up" ;
VAL_ 2499547902 MirrorLeft1HorizontalCmd 3 "Take no action" 2 "Reserved" 1 "Move right" 0 "Move left" ;
VAL_ 2499547902 RightRearWindowPosCmd 7 "Take no action" 6 "Reserved" 5 "Reserved" 4 "Reserved" 3 "Window auto down" 2 "Window auto up" 1 "Window move down" 0 "Window move up" ;
VAL_ 2499547902 LeftRearWindowPosCmd 7 "Take no action" 6 "Reserved" 5 "Reserved" 4 "Reserved" 3 "Window auto down" 2 "Window auto up" 1 "Window move down" 0 "Window move up" ;
VAL_ 2499547902 RightFrontWindowPosCmd 7 "Take no action" 6 "Reserved" 5 "Reserved" 4 "Reserved" 3 "Window auto down" 2 "Window auto up" 1 "Window move down" 0 "Window move up" ;
VAL_ 2499547902 LeftFrontWindowPosCmd 7 "Take no action" 6 "Reserved" 5 "Reserved" 4 "Reserved" 3 "Window auto down" 2 "Window auto up" 1 "Window move down" 0 "Window move up" ;
VAL_ 2499547902 RemoteCabDoorLockReq 7 "Take no action" 6 "Reserved" 5 "Request lock all cab door latches" 4 "Request unlock all cab door latches" 3 "Request unlock right rear cab door latch" 2 "Request unlock left rear cab door latch" 1 "Request unlock right front cab door latch" 0 "Request unlock left front cab door latch" ;
VAL_ 2499547902 DoorsLockActCmd 7 "Take no action" 6 "Reserved" 5 "Lock all cab door latches" 4 "Unlock all cab door latches" 3 "Unlock right rear cab door latch" 2 "Unlock left rear cab door latch" 1 "Unlock right front cab door latch" 0 "Unlock left front cab door latch" ;
VAL_ 2583177470 RainIntensity 7 "RAIN_NA" 6 "RAIN_Error" 5 "RAIN_Reserved2" 4 "RAIN_Reserved1" 3 "RAIN_High" 2 "RAIN_Medium" 1 "RAIN_Low" 0 "RAIN_Off" ;
VAL_ 2364552702 ImmoState 3 "NA" 2 "Error" 1 "Unlocked" 0 "Locked" ;
VAL_ 2582766846 OpIndcnReq 3 "Not available" 2 "Error" 1 "Indication required" 0 "No indication required" ;
VAL_ 2582766846 SecurityStateBackup 3 "Not_Available" 2 "Reserved" 1 "Compromised" 0 "Not Compromised" ;
VAL_ 2582766846 ACU_Error 3 "Not_Available" 2 "Reserved" 1 "Error" 0 "No Error" ;
VAL_ 2582766846 ACU_Active 3 "Not_Available" 2 "Error" 1 "Siren_on" 0 "Siren_off" ;
VAL_ 2582766846 ACU_Alarm 3 "Not_Available" 2 "Error" 1 "Alarm_on" 0 "Alarm_off" ;
VAL_ 2582766846 USS_Status 3 "Not_Available" 2 "Error" 1 "Armed" 0 "Disarmed" ;
VAL_ 2582766846 ACU_Status 3 "NA" 2 "Error" 1 "Armed" 0 "Disarmed" ;
VAL_ 2582766846 Intrusion_detected 3 "N/A" 2 "Reserved" 1 "Intrusion_detected " 0 "Intrusion_not_detected " ;
VAL_ 2565865982 TrctrMntdTrailerABSWarningSignal 3 "Take no action" 2 "Reserved" 1 "On" 0 "Off" ;
VAL_ 2565865982 TrailerABSStatus 3 "Trailer ABS Status Information Not Available or Parameter Not Supported" 2 "Reserved" 1 "Trailer ABS Active" 0 "Trailer ABS Status Information Available But Not Active" ;
VAL_ 2565865982 HaltBrakeSwitch 3 "Not available" 2 "Error" 1 "Halt brake switch active" 0 "Halt brake switch passive" ;
VAL_ 2565865982 ATC_ASRInformationSignal 3 "Take no action" 2 "Reserved" 1 "On" 0 "Off" ;
VAL_ 2565865982 ABS_EBSAmberWarningSignal 3 "Take no action" 2 "Reserved" 1 "On" 0 "Off" ;
VAL_ 2565865982 EBSRedWarningSignal 3 "Take no action" 2 "Reserved" 1 "On" 0 "Off" ;
VAL_ 2565865982 ABSFullyOperational 3 "Not available" 2 "Reserved" 1 "Fully Operational" 0 "Not Fully Operational" ;
VAL_ 2565865982 RemoteAccelEnableSwitch 3 "Not Available" 2 "Error" 1 "On" 0 "Off" ;
VAL_ 2565865982 EngAuxShutdownSwitch 3 "Not Available" 2 "Error" 1 "On" 0 "Off" ;
VAL_ 2565865982 EngDerateSwitch 3 "Not Available" 2 "Error" 1 "On" 0 "Off" ;
VAL_ 2565865982 AccelInterlockSwitch 3 "Not Available" 2 "Error" 1 "On" 0 "Off" ;
VAL_ 2565865982 TractionCtrlOverrideSwitch 3 "Not available or not installed" 2 "Error" 1 "On" 0 "Off" ;
VAL_ 2565865982 ASRHillHolderSwitch 3 "Not available" 2 "Error" 1 "ASR 'hill holder' switch active" 0 "ASR 'hill holder' switch passive" ;
VAL_ 2565865982 ASROffroadSwitch 3 "Not available" 2 "Error" 1 "ASR off-road switch active" 0 "ASR off-road switch passive" ;
VAL_ 2565865982 ABSOffroadSwitch 3 "Not available" 2 "Error" 1 "ABS off-road switch active" 0 "ABS off-road switch passive" ;
VAL_ 2565865982 EBSBrakeSwitch 3 "Not available" 2 "Error" 1 "Brake pedal is being pressed" 0 "Brake pedal is not being pressed" ;
VAL_ 2565865982 AntiLockBrakingActive 3 "Not available" 2 "Reserved" 1 "ABS active" 0 "ABS passive but installed" ;
VAL_ 2565865982 ASRBrakeCtrlActive 3 "Not available" 2 "Reserved" 1 "ASR brake control active" 0 "ASR brake control passive but installed" ;
VAL_ 2565865982 ASREngCtrlActive 3 "Not available" 2 "Reserved" 1 "ASR engine control active" 0 "ASR engine control passive but installed" ;
VAL_ 2381731326 TouchFailState 7 "Not Available" 6 "Error" 5 "Reserved" 4 "Reserved" 3 "Reserved" 2 "Failed On Touch" 1 "Failed" 0 "Not Failed" ;
VAL_ 2381731326 TouchEvent 7 "Not Available" 6 "Error" 5 "Reserved" 4 "Reserved" 3 "Double Press" 2 "Pressed" 1 "Unpressed" 0 "Off" ;
VAL_ 2583062270 DoorsSleepReadyState 3 "Not Available" 1 "All doors standstill" 0 "Any door moving" ;
VAL_ 2583062270 ServiceHatchLatchState 3 "NA" 2 "Fault" 1 "Open" 0 "Closed" ;
VAL_ 2583062270 CargoSideDoorLatchState 3 "Not Available" 2 "Error" 1 "Latched" 0 "Unlatched" ;
VAL_ 2583062270 CargoRearDoorLatchState 3 "Not Available" 2 "Error" 1 "Latched" 0 "Unlatched" ;
VAL_ 2583062270 BulkheadDoorLatchState 3 "Not Available" 2 "Error" 1 "Latched" 0 "Unlatched" ;
VAL_ 2583062270 PassDoorLatchState 3 "Not Available" 2 "Error" 1 "Latched" 0 "Unlatched" ;
VAL_ 2583062270 DriverDoorLatchState 3 "Not Available" 2 "Error" 1 "Latched" 0 "Unlatched" ;
VAL_ 2583062270 DoorsOpenState 3 "Not Available" 2 "Error" 1 "All doors closed" 0 "Any door opened" ;
VAL_ 2516060670 paEnableReq 3 "NotAvailable" 2 "Reserved" 1 "Requested" 0 "NotRequested" ;
VAL_ 2516060670 paAutoReq 3 "NotAvailable" 2 "Reserved" 1 "Requested" 0 "NotRequested" ;
VAL_ 2516060414 paStatus 3 "NotAvailable" 2 "Error" 1 "Active" 0 "NotActive" ;
VAL_ 2381723902 RecircModeState 7 "NA" 6 "Error" 2 "Auto" 1 "FullRecirc" 0 "Fresh" ;
VAL_ 2381723902 OutletSelectionState 15 "NA" 14 "Error" 8 "Auto" 6 "Windscreen/Front" 7 "Windscreen/Front/Floor" 5 "Windscreen/Floor" 4 "Front/Floor" 3 "Floor" 2 "Front" 1 "Windscreen" 0 "Off" ;
VAL_ 2583063294 PassWindowStatus 3 "NA" 2 "Error" 1 "Open" 0 "Closed" ;
VAL_ 2583063294 DriverWindowStatus 3 "NA" 2 "Error" 1 "Open" 0 "Closed" ;
VAL_ 2583063294 WindowPosCmd 7 "Take no action" 6 "Reserved" 5 "Reserved" 4 "Reserved" 3 "Window auto down" 2 "Window auto up" 1 "Window move down" 0 "Window move up" ;
VAL_ 2515942398 TurboEnableRequest 2 "Error" 3 "Not Available" 1 "On" 0 "Off" ;
VAL_ 2515942398 PetModeRequest 2 "Error" 3 "Not Available" 1 "On" 0 "Off" ;
VAL_ 2515942398 MaxACRequest 2 "Error" 3 "Not Available" 1 "On" 0 "Off" ;
VAL_ 2515942398 ACEnableRequest 2 "Error" 3 "Not Available" 1 "On" 0 "Off" ;
VAL_ 2515942398 AutoEnableRequest 2 "Error" 3 "Not Available" 1 "On" 0 "Off" ;
VAL_ 2515942398 CabinRecirculationRequest 7 "NA" 6 "Error" 2 "Auto" 1 "FullRecirc" 0 "Fresh" ;
VAL_ 2515942398 OutletSelectionRequest 15 "NA" 14 "Error" 8 "Auto" 6 "Windscreen/Front" 7 "Windscreen/Front/Floor" 5 "Windscreen/Floor" 4 "Front/Floor" 3 "Floor" 2 "Front" 1 "Windscreen" 0 "Off" ;
VAL_ 2515942398 CabinAirflowSpeedRequest 15 "NA" 14 "Error" 10 "Auto" 9 "Level 9" 8 "Level 8" 7 "Level 7" 6 "Level 6" 5 "Level 5" 4 "Level 4" 3 "Level 3" 2 "Level 2" 1 "Level 1" 0 "Off" ;
VAL_ 2515942398 DemistRequest 2 "Error" 3 "Not Available" 1 "On" 0 "Off" ;
VAL_ 2515942398 ClimateControlEnable 2 "Error" 3 "Not Available" 1 "On" 0 "Off" ;
VAL_ 2515949566 TurboEnableState 2 "Error" 3 "Not Available" 1 "On" 0 "Off" ;
VAL_ 2515949566 PetModeState 2 "Error" 3 "Not Available" 1 "On" 0 "Off" ;
VAL_ 2515949566 MaxACState 2 "Error" 3 "Not Available" 1 "On" 0 "Off" ;
VAL_ 2515949566 ACEnableState 2 "Error" 3 "Not Available" 1 "On" 0 "Off" ;
VAL_ 2515949566 AutoEnableState 2 "Error" 3 "Not Available" 1 "On" 0 "Off" ;
VAL_ 2515949566 RecirculationRequestState 7 "NA" 6 "Error" 2 "Auto" 1 "FullRecirc" 0 "Fresh" ;
VAL_ 2515949566 OutletSelectionState 15 "NA" 14 "Error" 8 "Auto" 6 "Windscreen/Front" 7 "Windscreen/Front/Floor" 5 "Windscreen/Floor" 4 "Front/Floor" 3 "Floor" 2 "Front" 1 "Windscreen" 0 "Off" ;
VAL_ 2515949566 BlowerSpeedRequestState 15 "NA" 14 "Error" 10 "Auto" 9 "Level 9" 8 "Level 8" 7 "Level 7" 6 "Level 6" 5 "Level 5" 4 "Level 4" 3 "Level 3" 2 "Level 2" 1 "Level 1" 0 "Off" ;
VAL_ 2515949566 DemistRequestState 2 "Error" 3 "Not Available" 1 "On" 0 "Off" ;
VAL_ 2515949566 ClimateControlEnableState 2 "Error" 3 "Not Available" 1 "On" 0 "Off" ;
VAL_ 2515942142 ClimateCtrlState 15 "NA" 7 "Demist" 6 "Turbo" 5 "TurboToAuto" 4 "Auto" 3 "Manual" 2 "PreShutdown" 1 "Off" 0 "Init" ;
VAL_ 2515942142 HVACModeCabin 7 "NotAvailable" 4 "Ventilation" 3 "Demist" 2 "Heating" 1 "Cooling" 0 "Standby" ;
VAL_ 2515942910 OutletSelectionRequest 15 "NA" 14 "Error" 8 "Auto" 6 "Windscreen/Front" 7 "Windscreen/Front/Floor" 5 "Windscreen/Floor" 4 "Front/Floor" 3 "Floor" 2 "Front" 1 "Windscreen" 0 "Off" ;
VAL_ 2583175678 PassLatchStateInfo 3 "NA" 2 "Error" 1 "On" 0 "Off" ;
VAL_ 2583175678 DriverLatchStateInfo 3 "NA" 2 "Error" 1 "On" 0 "Off" ;
VAL_ 2583175678 CenterLatchStateInfo 3 "NA" 2 "Error" 1 "On" 0 "Off" ;
VAL_ 2583175934 PassSeatStateInfo 3 "NA" 2 "Error" 1 "Occpd" 0 "Free" ;
VAL_ 2583175934 DriverSeatStateInfo 3 "NA" 2 "Error" 1 "Occpd" 0 "Free" ;
VAL_ 2583175934 CenterSeatStateInfo 3 "NA" 2 "Error" 1 "Occpd" 0 "Free" ;
VAL_ 2381851134 HornSwitchReq 3 "HornSwtReqNA" 2 "HornSwtReqErr" 1 "HornSwtReqOn" 0 "HornSwtReqOff" ;
VAL_ 2583175422 PassLatchState 3 "NA" 2 "Error" 1 "On" 0 "Off" ;
VAL_ 2583175422 DriverLatchState 3 "NA" 2 "Error" 1 "On" 0 "Off" ;
VAL_ 2583175422 BltWarnLvl 9 "FinalWarnBoth" 8 "FinalWarnPass" 7 "FinalWarnDrvr" 6 "SecondWarnBoth" 5 "SecondWarnPass" 4 "SecondWarnDrvr" 3 "FirstWarnBoth" 2 "FirstWarnPass" 1 "FirstWarnDrvr" 0 "NoWarn" ;
VAL_ 2583191550 LeftStopLightState 7 "light_Not_Available" 6 "light_Fault_Detected" 1 "light_Activated" 0 "light_De_activated" ;
VAL_ 2583191550 RightStopLightState 7 "light_Not_Available" 6 "light_Fault_Detected" 1 "light_Activated" 0 "light_De_activated" ;
VAL_ 2583191550 CenterStopLightState 7 "light_Not_Available" 6 "light_Fault_Detected" 1 "light_Activated" 0 "light_De_activated" ;
VAL_ 2398294526 SteerRedTelltaleReq 3 "Not Available" 2 "Error" 1 "On" 0 "Off" ;
VAL_ 2398294526 SteerYellowTelltaleReq 3 "Not Available" 2 "Error" 1 "On" 0 "Off" ;
VAL_ 2381861118 STRReadyToSleep 3 "NA" 2 "Error" 1 "Ready" 0 "Not Ready" ;
VAL_ 2381861118 STRReadyToDrive 3 "NA" 2 "Error" 1 "Ready" 0 "Not Ready" ;
VAL_ 2566845694 TirePressThresholdDetection_00 7 "NotAvailable" 6 "ErrorIndicator" 5 "NotDefined" 4 "ExtrmUndrPrssTrPrssrIsAtALvlWhr" 3 "UndrPrssTrPrssrIsLwrThnThPrssrD" 2 "NWrnngPrssTrPrssrIsWthnThThrshl" 1 "OvrPrssTrPrssrIsHghrThnThPrssrD" 0 "ExtrmOvrPrssTrPrssrIsAtALvlWhrT" ;
VAL_ 2566845694 TirePressThresholdDetection_20 7 "NotAvailable" 6 "ErrorIndicator" 5 "NotDefined" 4 "ExtrmUndrPrssTrPrssrIsAtALvlWhr" 3 "UndrPrssTrPrssrIsLwrThnThPrssrD" 2 "NWrnngPrssTrPrssrIsWthnThThrshl" 1 "OvrPrssTrPrssrIsHghrThnThPrssrD" 0 "ExtrmOvrPrssTrPrssrIsAtALvlWhrT" ;
VAL_ 2566845694 TirePressThresholdDetection_21 7 "NotAvailable" 6 "ErrorIndicator" 5 "NotDefined" 4 "ExtrmUndrPrssTrPrssrIsAtALvlWhr" 3 "UndrPrssTrPrssrIsLwrThnThPrssrD" 2 "NWrnngPrssTrPrssrIsWthnThThrshl" 1 "OvrPrssTrPrssrIsHghrThnThPrssrD" 0 "ExtrmOvrPrssTrPrssrIsAtALvlWhrT" ;
VAL_ 2566845694 TirePressThresholdDetection_22 7 "NotAvailable" 6 "ErrorIndicator" 5 "NotDefined" 4 "ExtrmUndrPrssTrPrssrIsAtALvlWhr" 3 "UndrPrssTrPrssrIsLwrThnThPrssrD" 2 "NWrnngPrssTrPrssrIsWthnThThrshl" 1 "OvrPrssTrPrssrIsHghrThnThPrssrD" 0 "ExtrmOvrPrssTrPrssrIsAtALvlWhrT" ;
VAL_ 2566845694 TirePressThresholdDetection_23 7 "NotAvailable" 6 "ErrorIndicator" 5 "NotDefined" 4 "ExtrmUndrPrssTrPrssrIsAtALvlWhr" 3 "UndrPrssTrPrssrIsLwrThnThPrssrD" 2 "NWrnngPrssTrPrssrIsWthnThThrshl" 1 "OvrPrssTrPrssrIsHghrThnThPrssrD" 0 "ExtrmOvrPrssTrPrssrIsAtALvlWhrT" ;
VAL_ 2566845694 TirePressThresholdDetection_30 7 "NotAvailable" 6 "ErrorIndicator" 5 "NotDefined" 4 "ExtrmUndrPrssTrPrssrIsAtALvlWhr" 3 "UndrPrssTrPrssrIsLwrThnThPrssrD" 2 "NWrnngPrssTrPrssrIsWthnThThrshl" 1 "OvrPrssTrPrssrIsHghrThnThPrssrD" 0 "ExtrmOvrPrssTrPrssrIsAtALvlWhrT" ;
VAL_ 2566845694 TirePressThresholdDetection_31 7 "NotAvailable" 6 "ErrorIndicator" 5 "NotDefined" 4 "ExtrmUndrPrssTrPrssrIsAtALvlWhr" 3 "UndrPrssTrPrssrIsLwrThnThPrssrD" 2 "NWrnngPrssTrPrssrIsWthnThThrshl" 1 "OvrPrssTrPrssrIsHghrThnThPrssrD" 0 "ExtrmOvrPrssTrPrssrIsAtALvlWhrT" ;
VAL_ 2566845694 TirePressThresholdDetection_32 7 "NotAvailable" 6 "ErrorIndicator" 5 "NotDefined" 4 "ExtrmUndrPrssTrPrssrIsAtALvlWhr" 3 "UndrPrssTrPrssrIsLwrThnThPrssrD" 2 "NWrnngPrssTrPrssrIsWthnThThrshl" 1 "OvrPrssTrPrssrIsHghrThnThPrssrD" 0 "ExtrmOvrPrssTrPrssrIsAtALvlWhrT" ;
VAL_ 2566845694 TirePressThresholdDetection_33 7 "NotAvailable" 6 "ErrorIndicator" 5 "NotDefined" 4 "ExtrmUndrPrssTrPrssrIsAtALvlWhr" 3 "UndrPrssTrPrssrIsLwrThnThPrssrD" 2 "NWrnngPrssTrPrssrIsWthnThThrshl" 1 "OvrPrssTrPrssrIsHghrThnThPrssrD" 0 "ExtrmOvrPrssTrPrssrIsAtALvlWhrT" ;
VAL_ 2566845694 TirePressThresholdDetection_01 7 "NotAvailable" 6 "ErrorIndicator" 5 "NotDefined" 4 "ExtrmUndrPrssTrPrssrIsAtALvlWhr" 3 "UndrPrssTrPrssrIsLwrThnThPrssrD" 2 "NWrnngPrssTrPrssrIsWthnThThrshl" 1 "OvrPrssTrPrssrIsHghrThnThPrssrD" 0 "ExtrmOvrPrssTrPrssrIsAtALvlWhrT" ;
VAL_ 2566845694 TirePressThresholdDetection_10 7 "NotAvailable" 6 "ErrorIndicator" 5 "NotDefined" 4 "ExtrmUndrPrssTrPrssrIsAtALvlWhr" 3 "UndrPrssTrPrssrIsLwrThnThPrssrD" 2 "NWrnngPrssTrPrssrIsWthnThThrshl" 1 "OvrPrssTrPrssrIsHghrThnThPrssrD" 0 "ExtrmOvrPrssTrPrssrIsAtALvlWhrT" ;
VAL_ 2566845694 TirePressThresholdDetection_11 7 "NotAvailable" 6 "ErrorIndicator" 5 "NotDefined" 4 "ExtrmUndrPrssTrPrssrIsAtALvlWhr" 3 "UndrPrssTrPrssrIsLwrThnThPrssrD" 2 "NWrnngPrssTrPrssrIsWthnThThrshl" 1 "OvrPrssTrPrssrIsHghrThnThPrssrD" 0 "ExtrmOvrPrssTrPrssrIsAtALvlWhrT" ;
VAL_ 2566845694 TirePressThresholdDetection_12 7 "NotAvailable" 6 "ErrorIndicator" 5 "NotDefined" 4 "ExtrmUndrPrssTrPrssrIsAtALvlWhr" 3 "UndrPrssTrPrssrIsLwrThnThPrssrD" 2 "NWrnngPrssTrPrssrIsWthnThThrshl" 1 "OvrPrssTrPrssrIsHghrThnThPrssrD" 0 "ExtrmOvrPrssTrPrssrIsAtALvlWhrT" ;
VAL_ 2566845694 TirePressThresholdDetection_13 7 "NotAvailable" 6 "ErrorIndicator" 5 "NotDefined" 4 "ExtrmUndrPrssTrPrssrIsAtALvlWhr" 3 "UndrPrssTrPrssrIsLwrThnThPrssrD" 2 "NWrnngPrssTrPrssrIsWthnThThrshl" 1 "OvrPrssTrPrssrIsHghrThnThPrssrD" 0 "ExtrmOvrPrssTrPrssrIsAtALvlWhrT" ;
VAL_ 2566845694 ExTirePressSupport 3 "Not Available/Not Supported" 2 "Error" 1 "Using Extended Tire Pressure" 0 "Not Using Extended Tire Pressure" ;
VAL_ 2566845694 CTIWheelEndElectricalFault_00 3 "NotSupported" 2 "Error" 1 "NotDefined" 0 "Ok" ;
VAL_ 2566845694 CTIWheelEndElectricalFault_01 3 "NotSupported" 2 "Error" 1 "NotDefined" 0 "Ok" ;
VAL_ 2566845694 CTIWheelEndElectricalFault_10 3 "NotSupported" 2 "Error" 1 "NotDefined" 0 "Ok" ;
VAL_ 2566845694 CTIWheelEndElectricalFault_11 3 "NotSupported" 2 "Error" 1 "NotDefined" 0 "Ok" ;
VAL_ 2566845694 CTIWheelEndElectricalFault_12 3 "NotSupported" 2 "Error" 1 "NotDefined" 0 "Ok" ;
VAL_ 2566845694 CTIWheelEndElectricalFault_13 3 "NotSupported" 2 "Error" 1 "NotDefined" 0 "Ok" ;
VAL_ 2566845694 CTIWheelEndElectricalFault_20 3 "NotSupported" 2 "Error" 1 "NotDefined" 0 "Ok" ;
VAL_ 2566845694 CTIWheelEndElectricalFault_21 3 "NotSupported" 2 "Error" 1 "NotDefined" 0 "Ok" ;
VAL_ 2566845694 CTIWheelEndElectricalFault_22 3 "NotSupported" 2 "Error" 1 "NotDefined" 0 "Ok" ;
VAL_ 2566845694 CTIWheelEndElectricalFault_23 3 "NotSupported" 2 "Error" 1 "NotDefined" 0 "Ok" ;
VAL_ 2566845694 CTIWheelEndElectricalFault_30 3 "NotSupported" 2 "Error" 1 "NotDefined" 0 "Ok" ;
VAL_ 2566845694 CTIWheelEndElectricalFault_31 3 "NotSupported" 2 "Error" 1 "NotDefined" 0 "Ok" ;
VAL_ 2566845694 CTIWheelEndElectricalFault_32 3 "NotSupported" 2 "Error" 1 "NotDefined" 0 "Ok" ;
VAL_ 2566845694 CTIWheelEndElectricalFault_33 3 "NotSupported" 2 "Error" 1 "NotDefined" 0 "Ok" ;
VAL_ 2566845694 CTITireStatus_00 3 "NotSupported" 2 "Error" 1 "TireLeakDetected" 0 "Ok" ;
VAL_ 2566845694 CTITireStatus_01 3 "NotSupported" 2 "Error" 1 "TireLeakDetected" 0 "Ok" ;
VAL_ 2566845694 CTITireStatus_10 3 "NotSupported" 2 "Error" 1 "TireLeakDetected" 0 "Ok" ;
VAL_ 2566845694 CTITireStatus_11 3 "NotSupported" 2 "Error" 1 "TireLeakDetected" 0 "Ok" ;
VAL_ 2566845694 CTITireStatus_12 3 "NotSupported" 2 "Error" 1 "TireLeakDetected" 0 "Ok" ;
VAL_ 2566845694 CTITireStatus_13 3 "NotSupported" 2 "Error" 1 "TireLeakDetected" 0 "Ok" ;
VAL_ 2566845694 CTITireStatus_20 3 "NotSupported" 2 "Error" 1 "TireLeakDetected" 0 "Ok" ;
VAL_ 2566845694 CTITireStatus_21 3 "NotSupported" 2 "Error" 1 "TireLeakDetected" 0 "Ok" ;
VAL_ 2566845694 CTITireStatus_22 3 "NotSupported" 2 "Error" 1 "TireLeakDetected" 0 "Ok" ;
VAL_ 2566845694 CTITireStatus_23 3 "NotSupported" 2 "Error" 1 "TireLeakDetected" 0 "Ok" ;
VAL_ 2566845694 CTITireStatus_30 3 "NotSupported" 2 "Error" 1 "TireLeakDetected" 0 "Ok" ;
VAL_ 2566845694 CTITireStatus_31 3 "NotSupported" 2 "Error" 1 "TireLeakDetected" 0 "Ok" ;
VAL_ 2566845694 CTITireStatus_32 3 "NotSupported" 2 "Error" 1 "TireLeakDetected" 0 "Ok" ;
VAL_ 2566845694 CTITireStatus_33 3 "NotSupported" 2 "Error" 1 "TireLeakDetected" 0 "Ok" ;
VAL_ 2566845694 CTIWheelSensorStatus_00 3 "NotSupported" 2 "NotDefined" 1 "On" 0 "Off_IsolatedFromCTIPressCtrl" ;
VAL_ 2566845694 CTIWheelSensorStatus_01 3 "NotSupported" 2 "NotDefined" 1 "On" 0 "Off_IsolatedFromCTIPressCtrl" ;
VAL_ 2566845694 CTIWheelSensorStatus_10 3 "NotSupported" 2 "NotDefined" 1 "On" 0 "Off_IsolatedFromCTIPressCtrl" ;
VAL_ 2566845694 CTIWheelSensorStatus_11 3 "NotSupported" 2 "NotDefined" 1 "On" 0 "Off_IsolatedFromCTIPressCtrl" ;
VAL_ 2566845694 CTIWheelSensorStatus_12 3 "NotSupported" 2 "NotDefined" 1 "On" 0 "Off_IsolatedFromCTIPressCtrl" ;
VAL_ 2566845694 CTIWheelSensorStatus_13 3 "NotSupported" 2 "NotDefined" 1 "On" 0 "Off_IsolatedFromCTIPressCtrl" ;
VAL_ 2566845694 CTIWheelSensorStatus_20 3 "NotSupported" 2 "NotDefined" 1 "On" 0 "Off_IsolatedFromCTIPressCtrl" ;
VAL_ 2566845694 CTIWheelSensorStatus_21 3 "NotSupported" 2 "NotDefined" 1 "On" 0 "Off_IsolatedFromCTIPressCtrl" ;
VAL_ 2566845694 CTIWheelSensorStatus_22 3 "NotSupported" 2 "NotDefined" 1 "On" 0 "Off_IsolatedFromCTIPressCtrl" ;
VAL_ 2566845694 CTIWheelSensorStatus_23 3 "NotSupported" 2 "NotDefined" 1 "On" 0 "Off_IsolatedFromCTIPressCtrl" ;
VAL_ 2566845694 CTIWheelSensorStatus_30 3 "NotSupported" 2 "NotDefined" 1 "On" 0 "Off_IsolatedFromCTIPressCtrl" ;
VAL_ 2566845694 CTIWheelSensorStatus_31 3 "NotSupported" 2 "NotDefined" 1 "On" 0 "Off_IsolatedFromCTIPressCtrl" ;
VAL_ 2566845694 CTIWheelSensorStatus_32 3 "NotSupported" 2 "NotDefined" 1 "On" 0 "Off_IsolatedFromCTIPressCtrl" ;
VAL_ 2566845694 CTIWheelSensorStatus_33 3 "NotSupported" 2 "NotDefined" 1 "On" 0 "Off_IsolatedFromCTIPressCtrl" ;
VAL_ 2566845694 TireLocation 51 "Axle3_Position3" 50 "Axle3_Position2" 49 "Axle3_Position1" 35 "Axle2_Position3" 34 "Axle2_Position2" 33 "Axle2_Position1" 19 "Axle1_Position3" 18 "Axle1_Position2" 17 "Axle1_Position1" 1 "Axle0_Position1" 48 "Axle3_Position0" 32 "Axle2_Position0" 16 "Axle1_Position0" 0 "Axle0_Position0" ;
VAL_ 2650238974 ADSReadyToSleep 3 "NA" 2 "Reserved" 1 "True" 0 "False" ;
VAL_ 2399126014 HVBPCRequest 3 "Not Available" 2 "Error" 1 "On" 0 "Off" ;
VAL_ 2399126014 HVBSMRequest 3 "Not Available" 2 "Error" 1 "On" 0 "Off" ;
VAL_ 2365574398 GearShiftSelector 6 "gss_Change in Progress" 5 "gss_Drive" 4 "gss_Neutral" 3 "gss_Reverse" 2 "gss_Park" 1 "gss_Error" 0 "gss_N/A" ;
VAL_ 2365574398 Driver_BMS_State 3 "preparation_mode" 2 "drive_mode" 1 "charge_mode" 0 "standby_mode" ;
